VERSION "hnnbnnnynnnnnnnnnnnnnnnnnnnnnnnnnnnnnnnnnn/4/%%%/4/'%**4nnn///"

NS_ :

BS_:

BU_: BAP_Tester Fahrerdisplay_Kombi HUD ICAS1_X_Gateway ICAS3_Gateway ICC_IO_Node Kombi SmartLight_01 ZR_MIB_TOP_ab_Gen3

BO_ 975 TSG_HBFS_01: 8 ICAS1_X_Gateway
	SG_ ASW_Warnung_aktiv_HBFS : 40|1@1+ (1,0) [0|1] ""  Vector__XXX
	SG_ HBFS_FH_Bew_hoch : 32|1@1+ (1,0) [0|1] ""  Vector__XXX
	SG_ HBFS_FH_Bew_tief : 33|1@1+ (1,0) [0|1] ""  Vector__XXX
	SG_ HBFS_FH_Block : 35|1@1+ (1,0) [0|1] ""  Vector__XXX
	SG_ HBFS_FH_Fang : 34|1@1+ (1,0) [0|1] ""  Vector__XXX
	SG_ HBFS_FH_normiert : 39|1@1+ (1,0) [0|1] ""  Vector__XXX
	SG_ HBFS_FH_Oeffnung : 24|8@1+ (0.5,0) [0|100] "PerCent"  Vector__XXX
	SG_ HBFS_FH_S_AutoHoch : 21|1@1+ (1,0) [0|1] ""  Vector__XXX
	SG_ HBFS_FH_S_AutoTief : 23|1@1+ (1,0) [0|1] ""  Vector__XXX
	SG_ HBFS_FH_S_HFS_AutoHoch : 10|1@1+ (1,0) [0|1] ""  Vector__XXX
	SG_ HBFS_FH_S_HFS_AutoTief : 11|1@1+ (1,0) [0|1] ""  Vector__XXX
	SG_ HBFS_FH_S_HFS_ManHoch : 12|1@1+ (1,0) [0|1] ""  Vector__XXX
	SG_ HBFS_FH_S_HFS_ManTief : 13|1@1+ (1,0) [0|1] ""  Vector__XXX
	SG_ HBFS_FH_S_ManHoch : 20|1@1+ (1,0) [0|1] ""  Vector__XXX
	SG_ HBFS_FH_S_ManTief : 22|1@1+ (1,0) [0|1] ""  Vector__XXX
	SG_ HBFS_FH_Thermo : 36|1@1+ (1,0) [0|1] ""  Vector__XXX
	SG_ HBFS_gesafet : 2|1@1+ (1,0) [0|1] ""  Vector__XXX
	SG_ HBFS_Heckrollotaster_betaetigt : 3|1@1+ (1,0) [0|1] ""  Vector__XXX
	SG_ HBFS_Lock_Taster : 6|1@1+ (1,0) [0|1] ""  Vector__XXX
	SG_ HBFS_Lock_Taster_inv : 55|1@1+ (1,0) [0|1] ""  Vector__XXX
	SG_ HBFS_MRollo_Schalter : 52|3@1+ (1,0) [0|7] ""  Vector__XXX
	SG_ HBFS_Oben_Block_erw : 46|1@1+ (1,0) [0|1] ""  Vector__XXX
	SG_ HBFS_SAD_Schalter : 16|4@1+ (1,0) [0|15] ""  Vector__XXX
	SG_ HBFS_Seitenrollo_hoch : 42|1@1+ (1,0) [0|1] ""  Vector__XXX
	SG_ HBFS_Seitenrollo_tief : 43|1@1+ (1,0) [0|1] ""  Vector__XXX
	SG_ HBFS_SK_betaetigt : 63|1@1+ (1,0) [0|1] ""  Vector__XXX
	SG_ HBFS_Sperrklinke : 7|1@1+ (1,0) [0|1] ""  Vector__XXX
	SG_ HBFS_Status_eTAG : 57|2@1+ (1,0) [0|3] ""  Vector__XXX
	SG_ HBFS_Status_KiSi : 44|1@1+ (1,0) [0|1] ""  Vector__XXX
	SG_ HBFS_Status_KiSi_inv : 56|1@1+ (1,0) [0|1] ""  Vector__XXX
	SG_ HBFS_TAG_betaetigt : 8|1@1+ (1,0) [0|1] ""  Vector__XXX
	SG_ HBFS_TIG_betaetigt : 9|1@1+ (1,0) [0|1] ""  Vector__XXX
	SG_ HBFS_TIG_betaetigt_oeffnen : 61|1@1+ (1,0) [0|1] ""  Vector__XXX
	SG_ HBFS_TIG_betaetigt_schliessen : 60|1@1+ (1,0) [0|1] ""  Vector__XXX
	SG_ HBFS_Tuer_geoeffnet : 0|1@1+ (1,0) [0|1] ""  ICAS3_Gateway,ZR_MIB_TOP_ab_Gen3
	SG_ HBFS_Tuer_Status : 14|2@1+ (1,0) [0|3] ""  Vector__XXX
	SG_ HBFS_Tuer_Status_QBit : 59|1@1+ (1,0) [0|1] ""  Vector__XXX
	SG_ HBFS_Tueroeffnen_Warnung : 38|1@1+ (1,0) [0|1] ""  Vector__XXX
	SG_ HBFS_Tuerschloss_defekt : 4|1@1+ (1,0) [0|1] ""  Kombi
	SG_ HBFS_UEKB_aktiviert : 37|1@1+ (1,0) [0|1] ""  Vector__XXX
	SG_ HBFS_Unlock_Taster : 5|1@1+ (1,0) [0|1] ""  Vector__XXX
	SG_ HBFS_Unten_Block_erw : 47|1@1+ (1,0) [0|1] ""  Vector__XXX
	SG_ HBFS_verriegelt : 1|1@1+ (1,0) [0|1] ""  Vector__XXX
	SG_ HBFS_Vorraste_betaetigt : 62|1@1+ (1,0) [0|1] ""  Vector__XXX
	SG_ HBFS_Zuziehhilfe_aktiv : 41|1@1+ (1,0) [0|1] ""  Vector__XXX
	SG_ MTHBFS_M_Taste : 48|1@1+ (1,0) [0|1] ""  Vector__XXX
	SG_ MTHBFS_Pos1 : 49|1@1+ (1,0) [0|1] ""  Vector__XXX
	SG_ MTHBFS_Pos2 : 50|1@1+ (1,0) [0|1] ""  Vector__XXX
	SG_ MTHBFS_Pos3 : 51|1@1+ (1,0) [0|1] ""  Vector__XXX
	SG_ SSR_HBFS_Pos_Unten : 45|1@1+ (1,0) [0|1] ""  Vector__XXX

BO_ 974 TSG_HFS_01: 8 ICAS1_X_Gateway
	SG_ ASW_Warnung_aktiv_HFS : 40|1@1+ (1,0) [0|1] ""  Vector__XXX
	SG_ HFS_FH_Bew_hoch : 32|1@1+ (1,0) [0|1] ""  Vector__XXX
	SG_ HFS_FH_Bew_tief : 33|1@1+ (1,0) [0|1] ""  Vector__XXX
	SG_ HFS_FH_Block : 35|1@1+ (1,0) [0|1] ""  Vector__XXX
	SG_ HFS_FH_Fang : 34|1@1+ (1,0) [0|1] ""  Vector__XXX
	SG_ HFS_FH_normiert : 39|1@1+ (1,0) [0|1] ""  Vector__XXX
	SG_ HFS_FH_Oeffnung : 24|8@1+ (0.5,0) [0|100] "PerCent"  Vector__XXX
	SG_ HFS_FH_S_AutoHoch : 21|1@1+ (1,0) [0|1] ""  Vector__XXX
	SG_ HFS_FH_S_AutoTief : 23|1@1+ (1,0) [0|1] ""  Vector__XXX
	SG_ HFS_FH_S_HBFS_AutoHoch : 10|1@1+ (1,0) [0|1] ""  Vector__XXX
	SG_ HFS_FH_S_HBFS_AutoTief : 11|1@1+ (1,0) [0|1] ""  Vector__XXX
	SG_ HFS_FH_S_HBFS_ManHoch : 12|1@1+ (1,0) [0|1] ""  Vector__XXX
	SG_ HFS_FH_S_HBFS_ManTief : 13|1@1+ (1,0) [0|1] ""  Vector__XXX
	SG_ HFS_FH_S_ManHoch : 20|1@1+ (1,0) [0|1] ""  Vector__XXX
	SG_ HFS_FH_S_ManTief : 22|1@1+ (1,0) [0|1] ""  Vector__XXX
	SG_ HFS_FH_Thermo : 36|1@1+ (1,0) [0|1] ""  Vector__XXX
	SG_ HFS_gesafet : 2|1@1+ (1,0) [0|1] ""  Vector__XXX
	SG_ HFS_Heckrollotaster_betaetigt : 3|1@1+ (1,0) [0|1] ""  Vector__XXX
	SG_ HFS_Lock_Taster : 6|1@1+ (1,0) [0|1] ""  Vector__XXX
	SG_ HFS_Lock_Taster_inv : 55|1@1+ (1,0) [0|1] ""  Vector__XXX
	SG_ HFS_MRollo_Schalter : 52|3@1+ (1,0) [0|7] ""  Vector__XXX
	SG_ HFS_Oben_Block_erw : 46|1@1+ (1,0) [0|1] ""  Vector__XXX
	SG_ HFS_SAD_Schalter : 16|4@1+ (1,0) [0|15] ""  Vector__XXX
	SG_ HFS_Seitenrollo_hoch : 42|1@1+ (1,0) [0|1] ""  Vector__XXX
	SG_ HFS_Seitenrollo_tief : 43|1@1+ (1,0) [0|1] ""  Vector__XXX
	SG_ HFS_SK_betaetigt : 63|1@1+ (1,0) [0|1] ""  Vector__XXX
	SG_ HFS_Sperrklinke : 7|1@1+ (1,0) [0|1] ""  Vector__XXX
	SG_ HFS_Status_eTAG : 56|2@1+ (1,0) [0|3] ""  Vector__XXX
	SG_ HFS_Status_KiSi : 44|1@1+ (1,0) [0|1] ""  Vector__XXX
	SG_ HFS_TAG_betaetigt : 8|1@1+ (1,0) [0|1] ""  Vector__XXX
	SG_ HFS_TCR_Mode_aktiv : 59|1@1+ (1,0) [0|1] ""  Vector__XXX
	SG_ HFS_TIG_betaetigt : 9|1@1+ (1,0) [0|1] ""  Vector__XXX
	SG_ HFS_TIG_betaetigt_oeffnen : 61|1@1+ (1,0) [0|1] ""  Vector__XXX
	SG_ HFS_TIG_betaetigt_schliessen : 60|1@1+ (1,0) [0|1] ""  Vector__XXX
	SG_ HFS_Tuer_geoeffnet : 0|1@1+ (1,0) [0|1] ""  ICAS3_Gateway,ZR_MIB_TOP_ab_Gen3
	SG_ HFS_Tuer_Status : 14|2@1+ (1,0) [0|3] ""  Vector__XXX
	SG_ HFS_Tuer_Status_QBit : 58|1@1+ (1,0) [0|1] ""  Vector__XXX
	SG_ HFS_Tueroeffnen_Warnung : 38|1@1+ (1,0) [0|1] ""  Vector__XXX
	SG_ HFS_Tuerschloss_defekt : 4|1@1+ (1,0) [0|1] ""  Kombi
	SG_ HFS_UEKB_aktiviert : 37|1@1+ (1,0) [0|1] ""  Vector__XXX
	SG_ HFS_Unlock_Taster : 5|1@1+ (1,0) [0|1] ""  Vector__XXX
	SG_ HFS_Unten_Block_erw : 47|1@1+ (1,0) [0|1] ""  Vector__XXX
	SG_ HFS_verriegelt : 1|1@1+ (1,0) [0|1] ""  Vector__XXX
	SG_ HFS_Vorraste_betaetigt : 62|1@1+ (1,0) [0|1] ""  Vector__XXX
	SG_ HFS_Zuziehhilfe_aktiv : 41|1@1+ (1,0) [0|1] ""  Vector__XXX
	SG_ MTHFS_M_Taste : 48|1@1+ (1,0) [0|1] ""  Vector__XXX
	SG_ MTHFS_Pos1 : 49|1@1+ (1,0) [0|1] ""  Vector__XXX
	SG_ MTHFS_Pos2 : 50|1@1+ (1,0) [0|1] ""  Vector__XXX
	SG_ MTHFS_Pos3 : 51|1@1+ (1,0) [0|1] ""  Vector__XXX
	SG_ SSR_HFS_Pos_Unten : 45|1@1+ (1,0) [0|1] ""  Vector__XXX

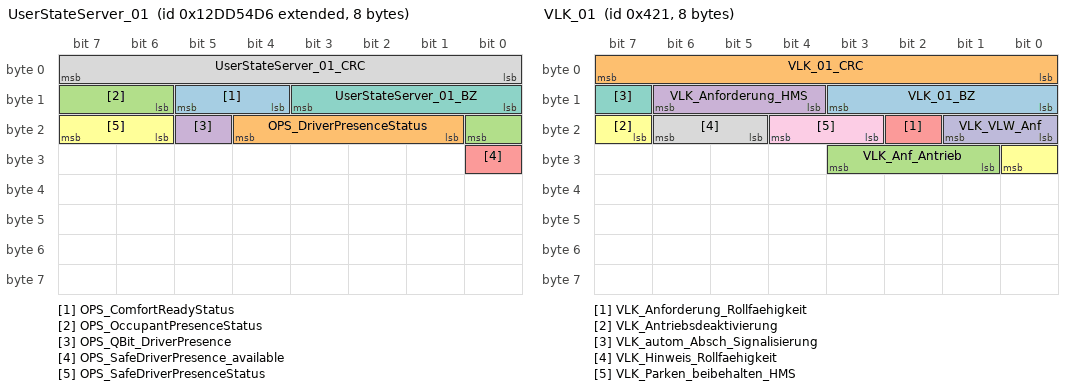
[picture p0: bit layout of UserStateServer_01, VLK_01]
BO_ 2463978710 UserStateServer_01: 8 ICAS1_X_Gateway
	SG_ OPS_ComfortReadyStatus : 12|2@1+ (1,0) [0|3] ""  HUD,ICAS3_Gateway,ICC_IO_Node,ZR_MIB_TOP_ab_Gen3
	SG_ OPS_DriverPresenceStatus : 17|4@1+ (1,0) [0|15] ""  HUD,ICAS3_Gateway,ICC_IO_Node
	SG_ OPS_OccupantPresenceStatus : 14|3@1+ (1,0) [0|7] ""  Vector__XXX
	SG_ OPS_QBit_DriverPresence : 21|1@1+ (1,0) [0|1] ""  Vector__XXX
	SG_ OPS_SafeDriverPresence_available : 24|1@1+ (1,0) [0|1] ""  Vector__XXX
	SG_ OPS_SafeDriverPresenceStatus : 22|2@1+ (1,0) [0|3] ""  Vector__XXX
	SG_ UserStateServer_01_BZ : 8|4@1+ (1,0) [0|15] ""  Vector__XXX
	SG_ UserStateServer_01_CRC : 0|8@1+ (1,0) [0|255] ""  Vector__XXX

BO_ 1716 VIN_01: 8 ICAS1_X_Gateway
	SG_ KS_Geheimnis_1 m0 : 8|8@1+ (1,0) [0|255] ""  ZR_MIB_TOP_ab_Gen3
	SG_ KS_Geheimnis_2 m0 : 16|8@1+ (1,0) [0|255] ""  ZR_MIB_TOP_ab_Gen3
	SG_ KS_Geheimnis_3 m0 : 24|8@1+ (1,0) [0|255] ""  ZR_MIB_TOP_ab_Gen3
	SG_ KS_Geheimnis_4 m0 : 32|8@1+ (1,0) [0|255] ""  ZR_MIB_TOP_ab_Gen3
	SG_ VIN_01_MUX M : 0|2@1+ (1,0) [0|3] ""  ICAS3_Gateway,ICC_IO_Node,Kombi,SmartLight_01,ZR_MIB_TOP_ab_Gen3
	SG_ VIN_1 m0 : 40|8@1+ (1,0) [0|255] ""  ICAS3_Gateway,Kombi,SmartLight_01,ZR_MIB_TOP_ab_Gen3
	SG_ VIN_10 m1 : 56|8@1+ (1,0) [0|255] ""  ICAS3_Gateway,Kombi,SmartLight_01,ZR_MIB_TOP_ab_Gen3
	SG_ VIN_11 m2 : 8|8@1+ (1,0) [0|255] ""  ICAS3_Gateway,Kombi,SmartLight_01,ZR_MIB_TOP_ab_Gen3
	SG_ VIN_12 m2 : 16|8@1+ (1,0) [0|255] ""  ICAS3_Gateway,Kombi,SmartLight_01,ZR_MIB_TOP_ab_Gen3
	SG_ VIN_13 m2 : 24|8@1+ (1,0) [0|255] ""  ICAS3_Gateway,Kombi,SmartLight_01,ZR_MIB_TOP_ab_Gen3
	SG_ VIN_14 m2 : 32|8@1+ (1,0) [0|255] ""  ICAS3_Gateway,Kombi,SmartLight_01,ZR_MIB_TOP_ab_Gen3
	SG_ VIN_15 m2 : 40|8@1+ (1,0) [0|255] ""  ICAS3_Gateway,Kombi,SmartLight_01,ZR_MIB_TOP_ab_Gen3
	SG_ VIN_16 m2 : 48|8@1+ (1,0) [0|255] ""  ICAS3_Gateway,Kombi,SmartLight_01,ZR_MIB_TOP_ab_Gen3
	SG_ VIN_17 m2 : 56|8@1+ (1,0) [0|255] ""  ICAS3_Gateway,Kombi,SmartLight_01,ZR_MIB_TOP_ab_Gen3
	SG_ VIN_2 m0 : 48|8@1+ (1,0) [0|255] ""  ICAS3_Gateway,Kombi,SmartLight_01,ZR_MIB_TOP_ab_Gen3
	SG_ VIN_3 m0 : 56|8@1+ (1,0) [0|255] ""  ICAS3_Gateway,Kombi,SmartLight_01,ZR_MIB_TOP_ab_Gen3
	SG_ VIN_4 m1 : 8|8@1+ (1,0) [0|255] ""  ICAS3_Gateway,Kombi,SmartLight_01,ZR_MIB_TOP_ab_Gen3
	SG_ VIN_5 m1 : 16|8@1+ (1,0) [0|255] ""  ICAS3_Gateway,Kombi,SmartLight_01,ZR_MIB_TOP_ab_Gen3
	SG_ VIN_6 m1 : 24|8@1+ (1,0) [0|255] ""  ICAS3_Gateway,Kombi,SmartLight_01,ZR_MIB_TOP_ab_Gen3
	SG_ VIN_7 m1 : 32|8@1+ (1,0) [0|255] ""  ICAS3_Gateway,Kombi,SmartLight_01,ZR_MIB_TOP_ab_Gen3
	SG_ VIN_8 m1 : 40|8@1+ (1,0) [0|255] ""  ICAS3_Gateway,Kombi,SmartLight_01,ZR_MIB_TOP_ab_Gen3
	SG_ VIN_9 m1 : 48|8@1+ (1,0) [0|255] ""  ICAS3_Gateway,Kombi,SmartLight_01,ZR_MIB_TOP_ab_Gen3

BO_ 1057 VLK_01: 8 ICAS1_X_Gateway
	SG_ VLK_01_BZ : 8|4@1+ (1,0) [0|15] ""  Vector__XXX
	SG_ VLK_01_CRC : 0|8@1+ (1,0) [0|255] ""  Vector__XXX
	SG_ VLK_Anf_Antrieb : 25|3@1+ (1,0) [0|7] ""  Vector__XXX
	SG_ VLK_Anforderung_HMS : 12|3@1+ (1,0) [0|7] ""  Vector__XXX
	SG_ VLK_Anforderung_Rollfaehigkeit : 18|1@1+ (1,0) [0|1] ""  Vector__XXX
	SG_ VLK_Antriebsdeaktivierung : 23|2@1+ (1,0) [0|3] ""  Vector__XXX
	SG_ VLK_autom_Absch_Signalisierung : 15|1@1+ (1,0) [0|1] ""  Kombi
	SG_ VLK_Hinweis_Rollfaehigkeit : 21|2@1+ (1,0) [0|3] ""  Kombi
	SG_ VLK_Parken_beibehalten_HMS : 19|2@1+ (1,0) [0|3] ""  Vector__XXX
	SG_ VLK_VLW_Anf : 16|2@1+ (1,0) [0|3] ""  Kombi

BO_ 2463978663 VZE_04: 32 ICAS1_X_Gateway
	SG_ VZE_Akustik_Limitwechsel : 5|1@1+ (1,0) [0|1] ""  Kombi
	SG_ VZE_Akustik_Limitwechsel_Status : 69|1@1+ (1,0) [0|1] ""  Vector__XXX
	SG_ VZE_Anhaenger_Vmax : 91|4@1+ (10,10) [10|140] "KiloMeterPerHour"  Vector__XXX
	SG_ VZE_Anzeige_VZ_1 : 232|8@1+ (1,0) [1|255] ""  Vector__XXX
	SG_ VZE_Anzeige_VZ_2 : 240|8@1+ (1,0) [1|255] "None"  Vector__XXX
	SG_ VZE_Anzeige_VZ_3 : 248|8@1+ (1,0) [1|255] "None"  Vector__XXX
	SG_ VZE_Anzeige_ZS_1 : 208|4@1+ (1,0) [1|15] "None"  Vector__XXX
	SG_ VZE_Anzeige_ZS_2 : 212|4@1+ (1,0) [1|15] "None"  Vector__XXX
	SG_ VZE_Anzeige_ZS_3 : 216|4@1+ (1,0) [1|15] "None"  Vector__XXX
	SG_ VZE_Anzeigemodus : 0|2@1+ (1,0) [0|3] ""  Vector__XXX
	SG_ VZE_Anzeigeunterdrueck_Zeichen_1 : 50|1@1+ (1,0) [0|1] ""  Vector__XXX
	SG_ VZE_Anzeigeunterdrueck_Zeichen_2 : 10|1@1+ (1,0) [0|1] ""  Vector__XXX
	SG_ VZE_Anzeigeunterdrueck_Zeichen_3 : 9|1@1+ (1,0) [0|1] ""  Vector__XXX
	SG_ VZE_Anzeigeunterdrueck_Zeichen_4 : 127|1@1+ (1,0) [0|1] ""  Vector__XXX
	SG_ VZE_Anzeigeunterdrueck_Zeichen_5 : 72|1@1+ (1,0) [0|1] ""  Vector__XXX
	SG_ VZE_Baustelle : 110|2@1+ (1,0) [0|3] ""  Vector__XXX
	SG_ VZE_Erweiterte_Information : 157|8@1+ (1,0) [1|255] "None"  Vector__XXX
	SG_ VZE_FoD_Status : 206|2@1+ (1,0) [0|3] ""  Fahrerdisplay_Kombi,Kombi,ZR_MIB_TOP_ab_Gen3
	SG_ VZE_Gong : 63|1@1+ (1,0) [0|1] ""  Vector__XXX
	SG_ VZE_Hinweistext : 2|3@1+ (1,0) [1|7] ""  Fahrerdisplay_Kombi
	SG_ VZE_Hinweistext_03 : 220|4@1+ (1,0) [1|15] ""  Vector__XXX
	SG_ VZE_Land : 224|5@1+ (1,0) [1|31] ""  Vector__XXX
	SG_ VZE_Modus_OptischeWarnung : 6|1@1+ (1,0) [0|1] ""  Fahrerdisplay_Kombi
	SG_ VZE_SLWF_Status : 70|2@1+ (1,0) [0|3] ""  Fahrerdisplay_Kombi
	SG_ VZE_Tempowarnung_Einheit : 166|1@1+ (1,0) [0|1] ""  Vector__XXX
	SG_ VZE_Tempowarnung_Offset : 167|5@1+ (1,0) [1|31] ""  Vector__XXX
	SG_ VZE_Tempowarnung_Status : 165|1@1+ (1,0) [0|1] ""  Vector__XXX
	SG_ VZE_Umweltinfo_Anhaengerbetrieb : 156|1@1+ (1,0) [0|1] ""  Vector__XXX
	SG_ VZE_Umweltinfo_Naesse : 154|1@1+ (1,0) [0|1] ""  Vector__XXX
	SG_ VZE_Umweltinfo_Nebel : 155|1@1+ (1,0) [0|1] ""  Vector__XXX
	SG_ VZE_Verkehrszeichen_1 : 11|8@1+ (1,0) [1|255] ""  Vector__XXX
	SG_ VZE_Verkehrszeichen_2 : 19|8@1+ (1,0) [1|255] ""  Vector__XXX
	SG_ VZE_Verkehrszeichen_3 : 27|8@1+ (1,0) [1|255] ""  Vector__XXX
	SG_ VZE_Verkehrszeichen_4 : 75|8@1+ (1,0) [1|255] ""  Vector__XXX
	SG_ VZE_Verkehrszeichen_5 : 83|8@1+ (1,0) [1|255] ""  Kombi
	SG_ VZE_Verkehrszeichen_6 : 128|8@1+ (1,0) [1|255] "None"  Vector__XXX
	SG_ VZE_Verkehrszeichen_Einheit : 8|1@1+ (1,0) [0|1] ""  Vector__XXX
	SG_ VZE_Warnung_Verkehrszeichen_1 : 35|1@1+ (1,0) [0|1] ""  Vector__XXX
	SG_ VZE_Warnung_Verkehrszeichen_2 : 36|1@1+ (1,0) [0|1] ""  Vector__XXX
	SG_ VZE_Warnung_Verkehrszeichen_3 : 37|1@1+ (1,0) [0|1] ""  Vector__XXX
	SG_ VZE_Warnung_Verkehrszeichen_4 : 99|1@1+ (1,0) [0|1] ""  Vector__XXX
	SG_ VZE_Warnung_Verkehrszeichen_5 : 100|1@1+ (1,0) [0|1] ""  Kombi
	SG_ VZE_Warnung_VZ_1 : 229|1@1+ (1,0) [0|1] ""  Vector__XXX
	SG_ VZE_Warnung_VZ_2 : 230|1@1+ (1,0) [0|1] ""  Vector__XXX
	SG_ VZE_Warnung_VZ_3 : 231|1@1+ (1,0) [0|1] ""  Vector__XXX
	SG_ VZE_Zeichen_01_Gesetz : 56|1@1+ (1,0) [0|1] ""  Vector__XXX
	SG_ VZE_Zeichen_01_Kamera : 54|1@1+ (1,0) [0|1] ""  Vector__XXX
	SG_ VZE_Zeichen_01_KameraWied : 51|1@1+ (1,0) [0|1] ""  Vector__XXX
	SG_ VZE_Zeichen_01_Karte : 55|1@1+ (1,0) [0|1] ""  Vector__XXX
	SG_ VZE_Zeichen_02_Gesetz : 59|1@1+ (1,0) [0|1] ""  Vector__XXX
	SG_ VZE_Zeichen_02_Kamera : 57|1@1+ (1,0) [0|1] ""  Vector__XXX
	SG_ VZE_Zeichen_02_KameraWied : 52|1@1+ (1,0) [0|1] ""  Vector__XXX
	SG_ VZE_Zeichen_02_Karte : 58|1@1+ (1,0) [0|1] ""  Vector__XXX
	SG_ VZE_Zeichen_03_Gesetz : 62|1@1+ (1,0) [0|1] ""  Vector__XXX
	SG_ VZE_Zeichen_03_Kamera : 60|1@1+ (1,0) [0|1] ""  Vector__XXX
	SG_ VZE_Zeichen_03_KameraWied : 53|1@1+ (1,0) [0|1] ""  Vector__XXX
	SG_ VZE_Zeichen_03_Karte : 61|1@1+ (1,0) [0|1] ""  Vector__XXX
	SG_ VZE_Zeichen_04_Gesetz : 95|1@1+ (1,0) [0|1] ""  Vector__XXX
	SG_ VZE_Zeichen_04_Kamera : 96|1@1+ (1,0) [0|1] ""  Vector__XXX
	SG_ VZE_Zeichen_04_KameraWied : 97|1@1+ (1,0) [0|1] ""  Vector__XXX
	SG_ VZE_Zeichen_04_Karte : 98|1@1+ (1,0) [0|1] ""  Vector__XXX
	SG_ VZE_Zeichen_05_Entfernung : 113|7@1+ (1,0) [1|127] "Meter"  Vector__XXX
	SG_ VZE_Zeichen_05_Entfernung_StdA : 120|7@1+ (1,0) [1|127] "Meter"  Vector__XXX
	SG_ VZE_Zeichen_05_Gesetz : 101|1@1+ (1,0) [0|1] ""  Vector__XXX
	SG_ VZE_Zeichen_05_Kamera : 74|1@1+ (1,0) [0|1] ""  Vector__XXX
	SG_ VZE_Zeichen_05_KameraWied : 73|1@1+ (1,0) [0|1] ""  Vector__XXX
	SG_ VZE_Zeichen_05_Karte : 112|1@1+ (1,0) [0|1] ""  Vector__XXX
	SG_ VZE_Zeichen_06_Entfernung : 140|7@1+ (1,0) [1|127] "Meter"  Vector__XXX
	SG_ VZE_Zeichen_06_Entfernung_StdA : 147|7@1+ (1,0) [1|127] "Meter"  Vector__XXX
	SG_ VZE_Zusatzschild_1 : 38|4@1+ (1,0) [1|15] ""  Vector__XXX
	SG_ VZE_Zusatzschild_2 : 42|4@1+ (1,0) [1|15] ""  Vector__XXX
	SG_ VZE_Zusatzschild_3 : 46|4@1+ (1,0) [1|15] ""  Vector__XXX
	SG_ VZE_Zusatzschild_4 : 102|4@1+ (1,0) [1|15] ""  Vector__XXX
	SG_ VZE_Zusatzschild_5 : 106|4@1+ (1,0) [1|15] ""  Vector__XXX
	SG_ VZE_Zusatzschild_6 : 136|4@1+ (1,0) [1|15] ""  Vector__XXX

BO_ 916 WBA_03: 8 ICAS1_X_Gateway
	SG_ GE_Sollgang : 40|4@1+ (1,0) [0|15] ""  Vector__XXX
	SG_ GE_Stoppverbot_Anz_01 : 56|1@1+ (1,0) [0|1] ""  Vector__XXX
	SG_ GE_Stoppverbot_Anz_02 : 57|1@1+ (1,0) [0|1] ""  Vector__XXX
	SG_ GE_Stoppverbot_Anz_03 : 58|1@1+ (1,0) [0|1] ""  Vector__XXX
	SG_ GE_Stoppverbot_Anz_04 : 59|1@1+ (1,0) [0|1] ""  Vector__XXX
	SG_ GE_Stoppverbot_Anz_05 : 60|1@1+ (1,0) [0|1] ""  Vector__XXX
	SG_ GE_Stoppverbot_Anz_06 : 61|1@1+ (1,0) [0|1] ""  Vector__XXX
	SG_ GE_Stoppverbot_Anz_07 : 62|1@1+ (1,0) [0|1] ""  Vector__XXX
	SG_ GE_Stoppverbot_Anz_Std : 63|1@1+ (1,0) [0|1] ""  Vector__XXX
	SG_ GE_Tipschaltempf_verfuegbar : 44|1@1+ (1,0) [0|1] ""  Vector__XXX
	SG_ GE_Wiederstart_Anz_Std : 55|1@1+ (1,0) [0|1] ""  Vector__XXX
	SG_ WBA_03_BZ : 8|4@1+ (1,0) [0|15] ""  Fahrerdisplay_Kombi,Kombi
	SG_ WBA_03_CRC : 0|8@1+ (1,0) [0|255] ""  Fahrerdisplay_Kombi,Kombi
	SG_ WBA_Anforderung_Akustik : 53|1@1+ (1,0) [0|1] ""  ICAS3_Gateway,Kombi
	SG_ WBA_Blinken : 54|1@1+ (1,0) [0|1] ""  Vector__XXX
	SG_ WBA_eing_Gang_02 : 24|4@1+ (1,0) [0|15] ""  Vector__XXX
	SG_ WBA_Fahrstufe_02 : 12|4@1+ (1,0) [0|15] ""  Fahrerdisplay_Kombi,Kombi,ZR_MIB_TOP_ab_Gen3
	SG_ WBA_GE_Texte : 28|3@1+ (1,0) [0|7] ""  Kombi
	SG_ WBA_GE_Texte_02 : 45|3@1+ (1,0) [0|7] ""  Kombi
	SG_ WBA_GE_Warnung_02 : 20|4@1+ (1,0) [0|15] ""  Kombi
	SG_ WBA_GE_Zusatzwarnungen : 37|3@1+ (1,0) [0|7] ""  Vector__XXX
	SG_ WBA_Schaltschema_02 : 32|3@1+ (1,0) [0|7] ""  Vector__XXX
	SG_ WBA_Schaltschema_Fahreraktion : 49|1@1+ (1,0) [0|1] ""  Vector__XXX
	SG_ WBA_Schaltschema_FS_inaktiv : 35|2@1+ (1,0) [0|3] ""  Vector__XXX
	SG_ WBA_Schaltschema_FS_vorwaerts : 50|2@1+ (1,0) [0|3] ""  Vector__XXX
	SG_ WBA_Schaltschema_Tippgasse : 48|1@1+ (1,0) [0|1] ""  Vector__XXX
	SG_ WBA_Segeln_aktiv : 31|1@1+ (1,0) [0|1] ""  Vector__XXX
	SG_ WBA_Shiftlock_Lampe : 52|1@1+ (1,0) [0|1] ""  Vector__XXX
	SG_ WBA_ZielFahrstufe : 16|4@1+ (1,0) [0|15] ""  Vector__XXX

BO_ 1361 WFS_01: 8 ICAS1_X_Gateway
	SG_ WFS_Betrieb_Lesespule : 21|1@1+ (1,0) [0|1] ""  Vector__XXX
	SG_ WFS_ELV_authorisiert : 19|1@1+ (1,0) [0|1] ""  Vector__XXX
	SG_ WFS_Fahrerhinweise : 34|2@1+ (1,0) [0|3] ""  Kombi
	SG_ WFS_ID_Geb_autorisiert : 5|1@1+ (1,0) [0|1] ""  Vector__XXX
	SG_ WFS_ID_Geb_autorisiert_in_Kl15 : 6|1@1+ (1,0) [0|1] ""  Vector__XXX
	SG_ WFS_ID_Geb_steckt : 7|1@1+ (1,0) [0|1] ""  Vector__XXX
	SG_ WFS_Klemmenfreigabe : 22|1@1+ (1,0) [0|1] ""  Vector__XXX
	SG_ WFS_Klemmenfreigabe_Signatur : 23|11@1+ (1,0) [0|2047] ""  Vector__XXX
	SG_ WFS_LF_Aktiv : 20|1@1+ (1,0) [0|1] ""  Vector__XXX
	SG_ WFS_LZ : 17|2@1+ (1,0) [0|3] ""  Kombi
	SG_ WFS_LZ_02 : 38|4@1+ (1,0) [0|15] ""  Vector__XXX
	SG_ WFS_Parken_Status : 36|2@1+ (1,0) [0|3] ""  Vector__XXX
	SG_ WFS_Safe : 16|1@1+ (1,0) [0|1] ""  Kombi
	SG_ WFS_Schluessel_Fahrberecht : 0|4@1+ (1,0) [0|15] ""  ZR_MIB_TOP_ab_Gen3
	SG_ WFS_Schluessel_Ist : 12|4@1+ (1,0) [0|8] "None"  Kombi,ZR_MIB_TOP_ab_Gen3
	SG_ WFS_Schluessel_Soll : 8|4@1+ (1,0) [0|8] "None"  Kombi,ZR_MIB_TOP_ab_Gen3
	SG_ WFS_Verbauinfo_ELV : 4|1@1+ (1,0) [0|1] ""  Vector__XXX

BO_ 1369 WFS_01_SOK_Signatur: 8 ICAS1_X_Gateway
	SG_ SOK_WFS01_Signatur : 0|64@1+ (1,0) [1|18446744073709551616] "None"  Vector__XXX

BO_ 34 WFS_Transponder_Req_02: 8 ICAS1_X_Gateway
	SG_ WFS_Transponder_Req_02_Data : 0|64@1+ (1,0) [0|18446744073709551616] "None"  Fahrerdisplay_Kombi

BO_ 35 WFS_Transponder_Resp_02: 8 Fahrerdisplay_Kombi
	SG_ WFS_Transponder_Resp_02_Data : 0|64@1+ (1,0) [0|18446744073709551616] "None"  ICAS1_X_Gateway

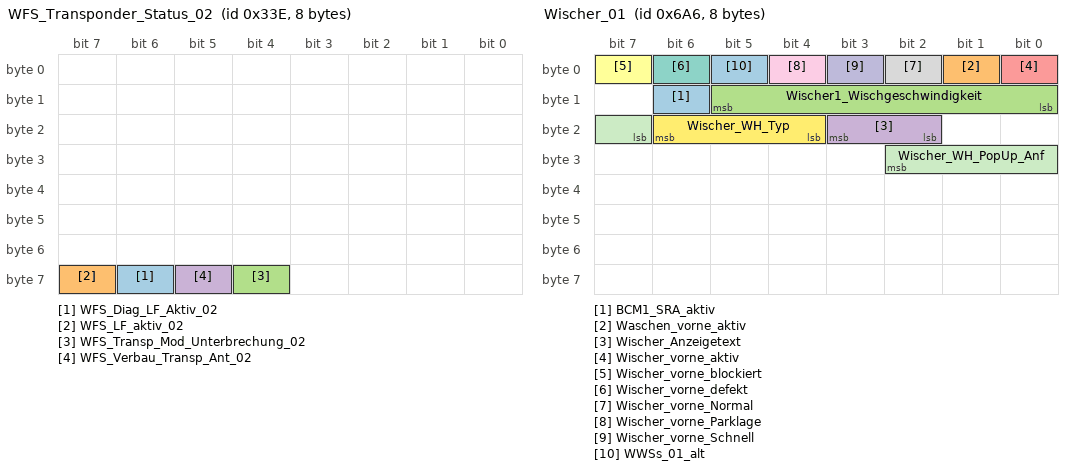
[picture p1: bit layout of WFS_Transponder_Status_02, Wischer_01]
BO_ 830 WFS_Transponder_Status_02: 8 Fahrerdisplay_Kombi
	SG_ WFS_Diag_LF_Aktiv_02 : 62|1@1+ (1,0) [0|1] ""  ICAS1_X_Gateway
	SG_ WFS_LF_aktiv_02 : 63|1@1+ (1,0) [0|1] ""  ICAS1_X_Gateway
	SG_ WFS_Transp_Mod_Unterbrechung_02 : 60|1@1+ (1,0) [0|1] ""  ICAS1_X_Gateway
	SG_ WFS_Verbau_Transp_Ant_02 : 61|1@1+ (1,0) [0|1] ""  ICAS1_X_Gateway

BO_ 1702 Wischer_01: 8 ICAS1_X_Gateway
	SG_ BCM1_SRA_aktiv : 14|1@1+ (1,0) [0|1] ""  Vector__XXX
	SG_ Waschen_vorne_aktiv : 1|1@1+ (1,0) [0|1] ""  Vector__XXX
	SG_ Wischer1_Wischgeschwindigkeit : 8|6@1+ (1,9) [10|70] "MinutInver"  Vector__XXX
	SG_ Wischer_Anzeigetext : 18|2@1+ (1,0) [0|3] ""  Vector__XXX
	SG_ Wischer_vorne_aktiv : 0|1@1+ (1,0) [0|1] ""  Vector__XXX
	SG_ Wischer_vorne_blockiert : 7|1@1+ (1,0) [0|1] ""  Vector__XXX
	SG_ Wischer_vorne_defekt : 6|1@1+ (1,0) [0|1] ""  Fahrerdisplay_Kombi,Kombi
	SG_ Wischer_vorne_Normal : 2|1@1+ (1,0) [0|1] ""  Vector__XXX
	SG_ Wischer_vorne_Parklage : 4|1@1+ (1,0) [0|1] ""  Vector__XXX
	SG_ Wischer_vorne_Schnell : 3|1@1+ (1,0) [0|1] ""  Vector__XXX
	SG_ Wischer_WH_PopUp_Anf : 23|4@1+ (1,0) [0|15] ""  Vector__XXX
	SG_ Wischer_WH_Typ : 20|3@1+ (1,0) [0|7] ""  Kombi
	SG_ WWSs_01_alt : 5|1@1+ (1,0) [0|1] ""  Vector__XXX

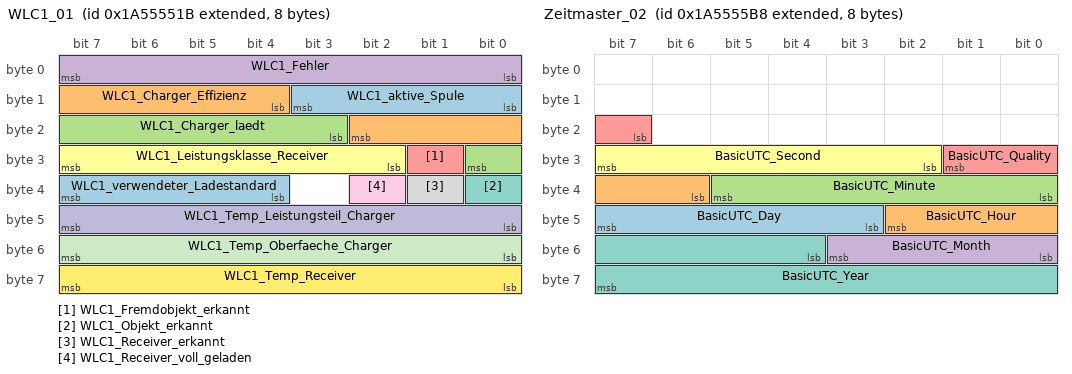
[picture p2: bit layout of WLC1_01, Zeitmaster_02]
BO_ 2589283611 WLC1_01: 8 ICAS3_Gateway
	SG_ WLC1_aktive_Spule : 8|4@1+ (1,0) [0|10] ""  ICAS1_X_Gateway
	SG_ WLC1_Charger_Effizienz : 12|7@1+ (1,0) [0|100] "PerCent"  ICAS1_X_Gateway
	SG_ WLC1_Charger_laedt : 19|6@1+ (0.1,0) [0|5] "Watt"  ICAS1_X_Gateway,ICAS3_Gateway,ZR_MIB_TOP_ab_Gen3
	SG_ WLC1_Fehler : 0|8@1+ (1,0) [0|255] ""  ICAS1_X_Gateway
	SG_ WLC1_Fremdobjekt_erkannt : 25|1@1+ (1,0) [0|1] ""  ICAS1_X_Gateway,ICAS3_Gateway,ZR_MIB_TOP_ab_Gen3
	SG_ WLC1_Leistungsklasse_Receiver : 26|6@1+ (0.1,0) [0|5] "Watt"  ICAS1_X_Gateway
	SG_ WLC1_Objekt_erkannt : 32|1@1+ (1,0) [0|1] ""  ICAS1_X_Gateway
	SG_ WLC1_Receiver_erkannt : 33|1@1+ (1,0) [0|1] ""  ICAS1_X_Gateway
	SG_ WLC1_Receiver_voll_geladen : 34|1@1+ (1,0) [0|1] ""  ICAS1_X_Gateway
	SG_ WLC1_Temp_Leistungsteil_Charger : 40|8@1+ (1,-58) [-58|120] "DegreCelsi"  ICAS1_X_Gateway
	SG_ WLC1_Temp_Oberfaeche_Charger : 48|8@1+ (1,-58) [-58|120] "DegreCelsi"  ICAS1_X_Gateway
	SG_ WLC1_Temp_Receiver : 56|8@1+ (1,-58) [-58|120] "DegreCelsi"  ICAS1_X_Gateway
	SG_ WLC1_verwendeter_Ladestandard : 36|4@1+ (1,0) [0|15] ""  ICAS1_X_Gateway

BO_ 2591965952 XCP_SmaLi_CRO_01: 64 Vector__XXX
	SG_ XCP_SmaLi_CRO_01_Data : 0|512@1+ (1,0) [0|13407807929942597099574024998205846127479365820592393377723561443721764030073546976801874298166903427690031858186486050853753882811946569946433649006084096] ""  SmartLight_01

BO_ 2591965953 XCP_SmaLi_DTO_01: 64 SmartLight_01
	SG_ XCP_SmaLi_DTO_01_Data : 0|512@1+ (1,0) [0|13407807929942597099574024998205846127479365820592393377723561443721764030073546976801874298166903427690031858186486050853753882811946569946433649006084096] ""  Vector__XXX

BO_ 2589283768 Zeitmaster_02: 8 ICAS1_X_Gateway
	SG_ BasicUTC_Day : 43|5@1+ (1,0) [1|31] "Day"  Kombi
	SG_ BasicUTC_Hour : 38|5@1+ (1,0) [0|23] "Hours"  Kombi
	SG_ BasicUTC_Minute : 32|6@1+ (1,0) [0|59] "Minut"  Kombi
	SG_ BasicUTC_Month : 48|4@1+ (1,0) [1|12] "Month"  Kombi
	SG_ BasicUTC_Quality : 23|3@1+ (1,0) [0|7] ""  Kombi
	SG_ BasicUTC_Second : 26|6@1+ (1,0) [0|60] "Secon"  Kombi
	SG_ BasicUTC_Year : 52|12@1+ (1,0) [1|4094] "Year"  Kombi

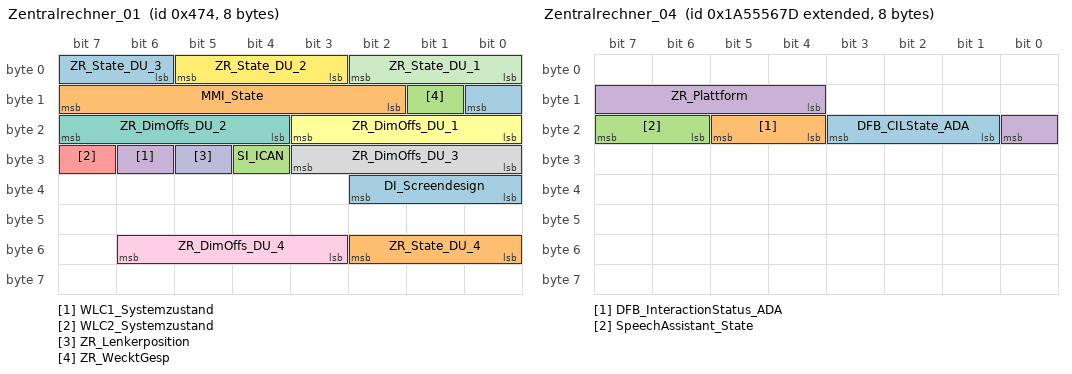
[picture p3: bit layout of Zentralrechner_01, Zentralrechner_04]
BO_ 1140 Zentralrechner_01: 8 ICAS3_Gateway
	SG_ DI_Screendesign : 32|3@1+ (1,0) [0|7] ""  Fahrerdisplay_Kombi,ICAS1_X_Gateway
	SG_ MMI_State : 10|6@1+ (1,0) [0|63] ""  ICAS1_X_Gateway
	SG_ SI_ICAN : 28|1@1+ (1,0) [0|1] ""  ICAS1_X_Gateway
	SG_ WLC1_Systemzustand : 30|1@1+ (1,0) [0|1] ""  ICAS1_X_Gateway
	SG_ WLC2_Systemzustand : 31|1@1+ (1,0) [0|1] ""  ICAS1_X_Gateway
	SG_ ZR_DimOffs_DU_1 : 16|4@1+ (1,-5) [-5|5] "None"  ICAS1_X_Gateway
	SG_ ZR_DimOffs_DU_2 : 20|4@1+ (1,-5) [-5|5] "None"  ICAS1_X_Gateway
	SG_ ZR_DimOffs_DU_3 : 24|4@1+ (1,-5) [-5|5] "None"  ICAS1_X_Gateway
	SG_ ZR_DimOffs_DU_4 : 51|4@1+ (1,-5) [-5|5] "None"  ICAS1_X_Gateway
	SG_ ZR_Lenkerposition : 29|1@1+ (1,0) [0|1] ""  ICAS1_X_Gateway
	SG_ ZR_State_DU_1 : 0|3@1+ (1,0) [0|7] ""  ICAS1_X_Gateway
	SG_ ZR_State_DU_2 : 3|3@1+ (1,0) [0|7] ""  ICAS1_X_Gateway
	SG_ ZR_State_DU_3 : 6|3@1+ (1,0) [0|7] ""  ICAS1_X_Gateway
	SG_ ZR_State_DU_4 : 48|3@1+ (1,0) [0|7] ""  ICAS1_X_Gateway
	SG_ ZR_WecktGesp : 9|1@1+ (1,0) [0|1] ""  ICAS1_X_Gateway

BO_ 2589283965 Zentralrechner_04: 8 ICAS3_Gateway
	SG_ DFB_CILState_ADA : 17|3@1+ (1,0) [0|7] ""  ICAS1_X_Gateway
	SG_ DFB_InteractionStatus_ADA : 20|2@1+ (1,0) [0|3] ""  ICAS1_X_Gateway
	SG_ SpeechAssistant_State : 22|2@1+ (1,0) [0|3] ""  ICAS1_X_Gateway
	SG_ ZR_Plattform : 12|5@1+ (1,0) [0|31] ""  Vector__XXX

BO_ 1411 ZV_02: 8 ICAS1_X_Gateway
	SG_ BCM_FH_Freigabe : 12|1@1+ (1,0) [0|1] ""  SmartLight_01
	SG_ BCM_HSK_Freigabe : 14|1@1+ (1,0) [0|1] ""  Vector__XXX
	SG_ BCM_Komfortfkt_Freigabe : 13|1@1+ (1,0) [0|1] ""  SmartLight_01
	SG_ BCM_Verdeck_Freigabe : 15|1@1+ (1,0) [0|1] ""  Vector__XXX
	SG_ DWA_aktiv : 31|1@1+ (1,0) [0|1] ""  SmartLight_01
	SG_ FBS_IDG_in_Reichweite : 41|1@1+ (1,0) [0|1] ""  SmartLight_01
	SG_ FBS_Warn_Schluessel_Batt : 47|1@1+ (1,0) [0|1] ""  Kombi,SmartLight_01
	SG_ FFB_Auf_Taste : 36|1@1+ (1,0) [0|1] ""  SmartLight_01
	SG_ FFB_CarFinder : 38|1@1+ (1,0) [0|1] ""  Vector__XXX
	SG_ FFB_HDF_Taste : 34|1@1+ (1,0) [0|1] ""  SmartLight_01
	SG_ FFB_Komfortoeffnen : 39|1@1+ (1,0) [0|1] ""  SmartLight_01
	SG_ FFB_Komfortschliessen : 40|1@1+ (1,0) [0|1] ""  SmartLight_01
	SG_ FFB_Panik_Taste : 35|1@1+ (1,0) [0|1] ""  SmartLight_01
	SG_ FFB_Zu_Taste : 37|1@1+ (1,0) [0|1] ""  SmartLight_01
	SG_ IRUE_aktiv : 30|1@1+ (1,0) [0|1] ""  SmartLight_01
	SG_ IRUE_Taster_Fkts_LED : 55|1@1+ (1,0) [0|1] ""  Vector__XXX
	SG_ VIP_Sensor_STSG_HBFS_betaetigt : 11|1@1+ (1,0) [0|1] ""  Vector__XXX
	SG_ VIP_Sensor_STSG_HFS_betaetigt : 10|1@1+ (1,0) [0|1] ""  Vector__XXX
	SG_ ZV_Anf_Challenge_Auth : 3|1@1+ (1,0) [0|1] ""  Vector__XXX
	SG_ ZV_BT_offen : 25|1@1+ (1,0) [0|1] ""  ICAS3_Gateway,Kombi,SmartLight_01,ZR_MIB_TOP_ab_Gen3
	SG_ ZV_Einzeltuerentriegelung : 22|1@1+ (1,0) [0|1] ""  SmartLight_01
	SG_ ZV_eRWK_Umfeld_Pruefung : 6|1@1+ (1,0) [0|1] ""  Vector__XXX
	SG_ ZV_FT_offen : 24|1@1+ (1,0) [0|1] ""  ICAS3_Gateway,ICC_IO_Node,Kombi,SmartLight_01,ZR_MIB_TOP_ab_Gen3
	SG_ ZV_gesafet_extern_ist : 20|1@1+ (1,0) [0|1] ""  SmartLight_01
	SG_ ZV_gesafet_extern_soll : 21|1@1+ (1,0) [0|1] ""  SmartLight_01
	SG_ ZV_HBFS_offen : 27|1@1+ (1,0) [0|1] ""  ICAS3_Gateway,Kombi,SmartLight_01,ZR_MIB_TOP_ab_Gen3
	SG_ ZV_HD_offen : 28|1@1+ (1,0) [0|1] ""  ICAS3_Gateway,Kombi,SmartLight_01,ZR_MIB_TOP_ab_Gen3
	SG_ ZV_Heckeinzelentriegelung : 23|1@1+ (1,0) [0|1] ""  SmartLight_01
	SG_ ZV_HFS_offen : 26|1@1+ (1,0) [0|1] ""  ICAS3_Gateway,Kombi,SmartLight_01,ZR_MIB_TOP_ab_Gen3
	SG_ ZV_HS_offen : 29|1@1+ (1,0) [0|1] ""  Vector__XXX
	SG_ ZV_ist_Zustand_verfuegbar : 54|1@1+ (1,0) [0|1] ""  SmartLight_01
	SG_ ZV_Oeffnungsmodus : 48|2@1+ (1,0) [0|3] ""  SmartLight_01
	SG_ ZV_Rollo_auf : 57|1@1+ (1,0) [0|1] ""  SmartLight_01
	SG_ ZV_Rollo_zu : 58|1@1+ (1,0) [0|1] ""  SmartLight_01
	SG_ ZV_SAD_auf : 59|1@1+ (1,0) [0|1] ""  SmartLight_01
	SG_ ZV_SAD_zu : 60|1@1+ (1,0) [0|1] ""  SmartLight_01
	SG_ ZV_SafeFunktion_aktiv : 46|1@1+ (1,0) [0|1] ""  Kombi,SmartLight_01
	SG_ ZV_Schluessel_Zugang : 42|4@1+ (1,0) [0|15] ""  SmartLight_01
	SG_ ZV_STSG_HBFS_Anf : 2|1@1+ (1,0) [0|1] ""  Vector__XXX
	SG_ ZV_STSG_HFS_Anf : 1|1@1+ (1,0) [0|1] ""  Vector__XXX
	SG_ ZV_Tankklappe_offen : 56|1@1+ (1,0) [0|1] ""  Vector__XXX
	SG_ ZV_verriegeln_Anf : 0|1@1+ (1,0) [0|1] ""  Vector__XXX
	SG_ ZV_verriegelt_extern_ist : 17|1@1+ (1,0) [0|1] ""  Kombi,SmartLight_01
	SG_ ZV_verriegelt_extern_soll : 19|1@1+ (1,0) [0|1] ""  ICAS3_Gateway,ICC_IO_Node,Kombi,SmartLight_01,ZR_MIB_TOP_ab_Gen3
	SG_ ZV_verriegelt_intern_ist : 16|1@1+ (1,0) [0|1] ""  SmartLight_01
	SG_ ZV_verriegelt_intern_soll : 18|1@1+ (1,0) [0|1] ""  SmartLight_01
	SG_ ZV_verriegelt_soll : 62|2@1+ (1,0) [0|3] ""  Vector__XXX

BO_ 708 ZV_04: 8 ICAS1_X_Gateway
	SG_ BCM_Waehlhebel_P_Hinweis : 52|1@1+ (1,0) [0|1] ""  Kombi
	SG_ UHF_FFB_Funkschluesseltyp : 58|3@1+ (1,0) [0|7] ""  Vector__XXX
	SG_ UHF_FFB_SKC_anlernen : 61|1@1+ (1,0) [0|1] ""  Vector__XXX
	SG_ ZV_04_BZ : 8|4@1+ (1,0) [0|15] ""  Vector__XXX
	SG_ ZV_04_CRC : 0|8@1+ (1,0) [0|255] ""  Vector__XXX
	SG_ ZV_DWA_Einfachhorn_Anf : 57|1@1+ (1,0) [0|1] ""  Vector__XXX
	SG_ ZV_DWA_Einfachhorn_Takt : 56|1@1+ (1,0) [0|1] ""  Vector__XXX
	SG_ ZV_Einfachhorn_Anf : 55|1@1+ (1,0) [0|1] ""  Vector__XXX
	SG_ ZV_Einfachhorn_Takt : 54|1@1+ (1,0) [0|1] ""  Vector__XXX
	SG_ ZV_HBFS_Status_KiSi : 16|1@1+ (1,0) [0|1] ""  Vector__XXX
	SG_ ZV_HBFS_TAG_betaetigt : 17|1@1+ (1,0) [0|1] ""  Vector__XXX
	SG_ ZV_HBFS_TIG_oeffnen_betaetigt : 18|1@1+ (1,0) [0|1] ""  Vector__XXX
	SG_ ZV_HBFS_TIG_schliessen_betaetigt : 19|1@1+ (1,0) [0|1] ""  Vector__XXX
	SG_ ZV_HD_Parkbremse_Hinweis : 51|1@1+ (1,0) [0|1] ""  Kombi
	SG_ ZV_HFS_Status_KiSi : 12|1@1+ (1,0) [0|1] ""  Vector__XXX
	SG_ ZV_HFS_TAG_betaetigt : 13|1@1+ (1,0) [0|1] ""  Vector__XXX
	SG_ ZV_HFS_TIG_oeffnen_betaetigt : 14|1@1+ (1,0) [0|1] ""  Vector__XXX
	SG_ ZV_HFS_TIG_schliessen_betaetigt : 15|1@1+ (1,0) [0|1] ""  Vector__XXX
	SG_ ZV_Hupe_Anf : 42|1@1+ (1,0) [0|1] ""  Vector__XXX
	SG_ ZV_Hupe_Takt : 41|1@1+ (1,0) [0|1] ""  Vector__XXX
	SG_ ZV_HW_Motor_Lock_HK : 63|1@1+ (1,0) [0|1] ""  Vector__XXX
	SG_ ZV_HW_Motor_Safe_Hinten : 62|1@1+ (1,0) [0|1] ""  Vector__XXX
	SG_ ZV_HW_TKL_mot_entr : 47|1@1+ (1,0) [0|1] ""  Vector__XXX
	SG_ ZV_HW_TKL_mot_verr : 46|1@1+ (1,0) [0|1] ""  Vector__XXX
	SG_ ZV_Laderaumabd_elektr_aktiviert : 53|1@1+ (1,0) [0|1] ""  Vector__XXX
	SG_ ZV_Status_Cargolock : 43|1@1+ (1,0) [0|1] ""  Vector__XXX
	SG_ ZV_Status_KiSi_CargoLock : 48|3@1+ (1,0) [0|7] ""  Vector__XXX
	SG_ ZV_verriegelt_extern_soll_03 : 44|2@1+ (1,0) [0|3] ""  Vector__XXX

BO_TX_BU_ 975 :ICAS1_X_Gateway;
BO_TX_BU_ 974 :ICAS1_X_Gateway;
BO_TX_BU_ 2463978710 :ICAS1_X_Gateway;
BO_TX_BU_ 1716 :ICAS1_X_Gateway;
BO_TX_BU_ 1057 :ICAS1_X_Gateway;
BO_TX_BU_ 2463978663 :ICAS1_X_Gateway;
BO_TX_BU_ 916 :ICAS1_X_Gateway;
BO_TX_BU_ 1361 :ICAS1_X_Gateway;
BO_TX_BU_ 1369 :ICAS1_X_Gateway;
BO_TX_BU_ 34 :ICAS1_X_Gateway;
BO_TX_BU_ 35 :Fahrerdisplay_Kombi;
BO_TX_BU_ 830 :Fahrerdisplay_Kombi;
BO_TX_BU_ 1702 :ICAS1_X_Gateway;
BO_TX_BU_ 2589283611 :ICAS3_Gateway,ICC_IO_Node,ZR_MIB_TOP_ab_Gen3;
BO_TX_BU_ 2591965953 :SmartLight_01;
BO_TX_BU_ 2589283768 :ICAS1_X_Gateway;
BO_TX_BU_ 1140 :ICAS3_Gateway,ICC_IO_Node,ZR_MIB_TOP_ab_Gen3;
BO_TX_BU_ 2589283965 :ICAS3_Gateway;
BO_TX_BU_ 1411 :ICAS1_X_Gateway;
BO_TX_BU_ 708 :ICAS1_X_Gateway;
CM_ BO_ 1716 "200ms bei D4 und folgende";
CM_ BO_ 916 "ersetzt WBA_02";
CM_ BO_ 1702 "MLBevo";
CM_ SG_ 975 ASW_Warnung_aktiv_HBFS "Abschaltung der Ambientefunktion Tï?½r hinten der Beifahrerseite bei aktiver ASW Warnung an der Fahrertï?½r";
CM_ SG_ 975 HBFS_FH_Bew_hoch "HBFS Fenster bewegt sich in Richtung hoch";
CM_ SG_ 975 HBFS_FH_Bew_tief "HBFS Fenster bewegt sich in Richtung tief";
CM_ SG_ 975 HBFS_FH_Block "Fensterscheibe befindet sich im mechanischen Block (oben oder unten)";
CM_ SG_ 975 HBFS_FH_Fang "Fangbereich ist 4mm von oberer Lippendichtung";
CM_ SG_ 975 HBFS_FH_normiert "Die Position der Fensterheberscheibe ist bekannt.";
CM_ SG_ 975 HBFS_FH_Oeffnung "Gibt den Fensterï?½ffnungswert in % an.";
CM_ SG_ 975 HBFS_FH_S_AutoHoch "Betaetigung FH Schalter auto tief ";
CM_ SG_ 975 HBFS_FH_S_AutoTief "Betaetigung FH Schalter auto hoch";
CM_ SG_ 975 HBFS_FH_S_HFS_AutoHoch "Automatisches Hochfahren der Seitenscheibe HFS";
CM_ SG_ 975 HBFS_FH_S_HFS_AutoTief "Automatisches Absenken der Seitenscheibe HFS";
CM_ SG_ 975 HBFS_FH_S_HFS_ManHoch "Manuelles Hochfahren der Seitenscheibe HFS";
CM_ SG_ 975 HBFS_FH_S_HFS_ManTief "Manuelles Absenken der Seitenscheibe HFS";
CM_ SG_ 975 HBFS_FH_S_ManHoch "Betaetigung FH Schalter man hoch ";
CM_ SG_ 975 HBFS_FH_S_ManTief "Betaetigung FH Schalter man tief";
CM_ SG_ 975 HBFS_FH_Thermo "gibt an ob Fensterheber im Thermoschutz ist";
CM_ SG_ 975 HBFS_gesafet "HBFS Tuer gesafet.\nIm Zustand Safe wird auch das Signal HBFS_verriegelt = 1 gesendet.";
CM_ SG_ 975 HBFS_Heckrollotaster_betaetigt "Verfahren des Heckrollos in Richtung Hoch\n\nBei Einfachtaster wird Bit als Togglebit verwendet (Heckrollo hoch, tief)";
CM_ SG_ 975 HBFS_Lock_Taster "Betaetigung Lock-Taster";
CM_ SG_ 975 HBFS_Lock_Taster_inv "Lock Taster nicht betï?½tigt";
CM_ SG_ 975 HBFS_MRollo_Schalter "  | MRollo2\n-----------------------------\n0 | nicht_betaetigt\n1 | (m) Zu\n2 | (a) Zu\n3 | (m) Auf\n4 | (a) Auf\n5 | Schalter nicht verfuegbar\n6 | Init\n7 | Fehlerfall";
CM_ SG_ 975 HBFS_Oben_Block_erw "Fensterheber in Blockerwartung oben";
CM_ SG_ 975 HBFS_SAD_Schalter "  |   Ausstelldach MD3\n-----------------------------\n0 | nicht_betaetigt\n1 |\n2 |\n3 |\n4 |\n5 | (m) Auf\n6 | (a) Auf\n7 | (m) Zu\n8 | (a) Zu\n13| Schalter nicht verfuegbar\n14| Init\n15| Fehlerfall";
CM_ SG_ 975 HBFS_Seitenrollo_tief "Seitenrollo in Bewegung Richtung tief";
CM_ SG_ 975 HBFS_SK_betaetigt "Status der Sperrklinke";
CM_ SG_ 975 HBFS_Sperrklinke "Vorraste fï?½r Schloï?½\n\nzwischen Vor- und Hauptraste Signal kurz auf 1, danach wieder auf 0 wenn Tï?½r in Hauptraste (Tï?½r ist sicher zu wenn Sperrklinke und Tï?½rkontakt auf 0 sind)";
CM_ SG_ 975 HBFS_Status_eTAG "Status des elektrischen Tueraussengriffes Tuer Beifahrerseite hinten";
CM_ SG_ 975 HBFS_Status_KiSi "Status Kindersicherung HBFS\n";
CM_ SG_ 975 HBFS_Status_KiSi_inv "Inverser Status der elektrischen Kindersicherung Beifahrerseite hinten";
CM_ SG_ 975 HBFS_TAG_betaetigt "Betaetigung Tï?½raussengriff";
CM_ SG_ 975 HBFS_TIG_betaetigt "Betaetigung Tuerinnengriff";
CM_ SG_ 975 HBFS_TIG_betaetigt_oeffnen "Tï?½rinnenbetï?½tigung, Taster Tï?½r ï?½ffnen.";
CM_ SG_ 975 HBFS_TIG_betaetigt_schliessen "Tï?½rinnenbetï?½tigung, Taster Tï?½r schlieï?½en.";
CM_ SG_ 975 HBFS_Tuer_geoeffnet "HBFS Tuer geoeffnet";
CM_ SG_ 975 HBFS_Tuer_Status "Tï?½rstatus mit Fehler und Initwert";
CM_ SG_ 975 HBFS_Tuer_Status_QBit "Dieses Bit gibt die Zuverlï?½ssigkeit des Tï?½rkontakts an. Ein auf dieses Bit folgender Fehlereintrag ist mit dem Sender des Bits abzustimmen (gï?½ltig ab PPE).";
CM_ SG_ 975 HBFS_Tueroeffnen_Warnung "Bit wird gesetzt, wenn Tï?½r wï?½hrend der Fahrt geoeffnet werden soll.";
CM_ SG_ 975 HBFS_Tuerschloss_defekt "Das hintere Tuerschloss auf der Beifahrerseite ist nicht mehr funktionsfï?½hig.";
CM_ SG_ 975 HBFS_UEKB_aktiviert "ï?½berschutzbegrenzungskraft bei Reversieren";
CM_ SG_ 975 HBFS_Unlock_Taster "Betaetigung Unlock Taster";
CM_ SG_ 975 HBFS_Unten_Block_erw "Fensterheber in Blockerwartung unten";
CM_ SG_ 975 HBFS_verriegelt "Verriegelungsstatus Tï?½r";
CM_ SG_ 975 HBFS_Vorraste_betaetigt "Status der Vorraste";
CM_ SG_ 975 HBFS_Zuziehhilfe_aktiv "Zuziehhilfe aktiv";
CM_ SG_ 975 MTHBFS_M_Taste "Betï?½tigung M-Taste HBFS";
CM_ SG_ 975 MTHBFS_Pos1 "Betï?½tigung Postionstaste 1 HBFS";
CM_ SG_ 975 MTHBFS_Pos2 "Betï?½tigung Postionstaste 2 HBFS\n";
CM_ SG_ 975 MTHBFS_Pos3 "Betï?½tigung Postionstaste 3 HBFS";
CM_ SG_ 975 SSR_HBFS_Pos_Unten "Signal fï?½r die 'Global Close'. ï?½ber dieses Bit wissen die anderen TSGs, ob der SSR oder der FH verfahren werden darf.";
CM_ SG_ 974 ASW_Warnung_aktiv_HFS "Abschaltung der Ambientefunktion Tï?½r hinten der Fahrerseite bei aktiver ASW Warnung an der Fahrertï?½r";
CM_ SG_ 974 HFS_FH_Bew_hoch "HFS Fenster bewegt sich in Richtung hoch";
CM_ SG_ 974 HFS_FH_Bew_tief "HFS Fenster bewegt sich in Richtung tief";
CM_ SG_ 974 HFS_FH_Block "Fensterscheibe befindet sich im mechanischen Block (oben oder unten)";
CM_ SG_ 974 HFS_FH_Fang "Fangbereich ist 4mm von oberer Lippendichtung";
CM_ SG_ 974 HFS_FH_normiert "Die Position der Fensterheberscheibe ist bekannt.";
CM_ SG_ 974 HFS_FH_Oeffnung "Gibt den Fensterï?½ffnungswert in % an.";
CM_ SG_ 974 HFS_FH_S_AutoHoch "Betaetigung FH Schalter auto hoch";
CM_ SG_ 974 HFS_FH_S_AutoTief "Betaetigung FH Schalter auto tief ";
CM_ SG_ 974 HFS_FH_S_HBFS_AutoHoch "Automatisches Hochfahren der Seitenscheibe HBFS";
CM_ SG_ 974 HFS_FH_S_HBFS_AutoTief "Automatisches Absenken der Seitenscheibe HBFS";
CM_ SG_ 974 HFS_FH_S_HBFS_ManHoch "Manuelles Hochfahren der Seitenscheibe HBFS";
CM_ SG_ 974 HFS_FH_S_HBFS_ManTief "Manuelles Absenken der Seitenscheibe HBFS";
CM_ SG_ 974 HFS_FH_S_ManHoch "Betaetigung FH Schalter man hoch ";
CM_ SG_ 974 HFS_FH_S_ManTief "Betaetigung FH Schalter man tief";
CM_ SG_ 974 HFS_FH_Thermo "gibt an ob Fensterheber im Thermoschutz ist";
CM_ SG_ 974 HFS_gesafet "HFS Tuer gesafet.\nIm Zustand Safe wird auch das Signal HFS_verriegelt = 1 gesendet.";
CM_ SG_ 974 HFS_Heckrollotaster_betaetigt "Verfahren des Heckrollos in Richtung Hoch\n\nBei Einfachtaster wird Bit als Togglebit verwendet (Heckrollo hoch, tief)";
CM_ SG_ 974 HFS_Lock_Taster "Betï?½tigung Lock-Taster";
CM_ SG_ 974 HFS_Lock_Taster_inv "Lock Taster nicht betï?½tigt";
CM_ SG_ 974 HFS_MRollo_Schalter "  | MRollo2\n-----------------------------\n0 | nicht_betaetigt\n1 | (m) Zu\n2 | (a) Zu\n3 | (m) Auf\n4 | (a) Auf\n5 | Schalter nicht verfuegbar\n6 | Init\n7 | Fehlerfall";
CM_ SG_ 974 HFS_Oben_Block_erw "Fensterheber in Blockerwartung oben";
CM_ SG_ 974 HFS_SAD_Schalter "  |   Ausstelldach MD3\n-----------------------------\n0 | nicht_betaetigt\n1 |\n2 |\n3 |\n4 |\n5 | (m) Auf\n6 | (a) Auf\n7 | (m) Zu\n8 | (a) Zu\n13| Schalter nicht verfuegbar\n14| Init\n15| Fehlerfall";
CM_ SG_ 974 HFS_Seitenrollo_hoch "Seitenrollo in Bewegung Richtung hoch";
CM_ SG_ 974 HFS_Seitenrollo_tief "Seitenrollo in Bewegung Richtung tief";
CM_ SG_ 974 HFS_SK_betaetigt "Status der Sperrklinke";
CM_ SG_ 974 HFS_Sperrklinke "Vorraste fï?½r Schloï?½\n\nzwischen Vor- und Hauptraste Signal kurz auf 1, danach wieder auf 0 wenn Tï?½r in Hauptraste (Tï?½r ist sicher zu wenn Sperrklinke und Tï?½rkontakt auf 0 sind)";
CM_ SG_ 974 HFS_Status_eTAG "Status des elektrischen Tueraussengriffes Tuer Fahrerseite hinten";
CM_ SG_ 974 HFS_Status_KiSi "Status Kindersicherung hinten Fahrerseite";
CM_ SG_ 974 HFS_TAG_betaetigt "Betaetigung Tï?½raussengriff";
CM_ SG_ 974 HFS_TCR_Mode_aktiv "Signal zeigt eine aktive mechanische Redundanz am Tï?½rschloss an.";
CM_ SG_ 974 HFS_TIG_betaetigt "Betaetigung Tï?½rinnengriff";
CM_ SG_ 974 HFS_TIG_betaetigt_oeffnen "Tï?½rinnenbetï?½tigung, Taster Tï?½r ï?½ffnen.";
CM_ SG_ 974 HFS_TIG_betaetigt_schliessen "Tï?½rinnenbetï?½tigung, Taster Tï?½r schlieï?½en.";
CM_ SG_ 974 HFS_Tuer_geoeffnet "HFS Tuer geoeffnet";
CM_ SG_ 974 HFS_Tuer_Status "Tï?½rstatus mit Fehler und Initwert";
CM_ SG_ 974 HFS_Tuer_Status_QBit "Dieses Bit gibt die Zuverlï?½ssigkeit des Tï?½rkontakts an. Ein auf dieses Bit folgender Fehlereintrag ist mit dem Sender des Bits abzustimmen (gï?½ltig ab PPE).";
CM_ SG_ 974 HFS_Tueroeffnen_Warnung "Bit wird gesetzt, wenn Tï?½r wï?½hrend der Fahrt geoeffnet werden soll.";
CM_ SG_ 974 HFS_Tuerschloss_defekt "Das hintere Tuerschloss auf der Fahrerseite ist nicht mehr funktionsfï?½hig.";
CM_ SG_ 974 HFS_UEKB_aktiviert "ï?½berschutzbegrenzungskraft bei Reversieren";
CM_ SG_ 974 HFS_Unlock_Taster "Betaetigung Unlock Taster";
CM_ SG_ 974 HFS_Unten_Block_erw "Fensterheber in Blockerwartung unten";
CM_ SG_ 974 HFS_verriegelt "HFS Tuer verriegelt";
CM_ SG_ 974 HFS_Vorraste_betaetigt "Status der Vorraste";
CM_ SG_ 974 HFS_Zuziehhilfe_aktiv "Zuziehhilfe aktiv";
CM_ SG_ 974 MTHFS_M_Taste "Betï?½tigung M-Taste HFS";
CM_ SG_ 974 MTHFS_Pos1 "Betï?½tigung Postionstaste 1 HFS";
CM_ SG_ 974 MTHFS_Pos2 "Betï?½tigung Postionstaste 2 HFS\n";
CM_ SG_ 974 MTHFS_Pos3 "Betï?½tigung Postionstaste 3 HFS";
CM_ SG_ 974 SSR_HFS_Pos_Unten "Signal fï?½r die 'Global Close'. ï?½ber dieses Bit wissen die anderen TSGs, ob der SSR oder der FH verfahren werden darf.";
CM_ SG_ 2463978710 OPS_ComfortReadyStatus "Das Signal wird durch den Basisdienst User State Server (Technikvariante: OccupantPresenceService) erzeugt und bildet einen neuen Zustand, bestehend aus einer Verknï?½pfung der Fahreranwesenheit (Fahrer abwesend / Fahrer anwesend) und der Klemmensteuerung (";
CM_ SG_ 2463978710 OPS_DriverPresenceStatus "Das Signal wird durch den Basisdienst User State Server (Service: OccupantPresenceService) erzeugt und bildet die Fahrerzustï?½nde im Fahrzeug ab.";
CM_ SG_ 2463978710 OPS_OccupantPresenceStatus "Das Signal wird durch den Basisdienst User State Server (Service: OccupantPresenceService) erzeugt und bildet die Anwesenheit und Abwesenheit aller Insassen im Fahrzeug ab.";
CM_ SG_ 2463978710 OPS_QBit_DriverPresence "Das Signal wird durch den Basisdienst User State Server (Service: OccupantPresenceService) erzeugt und signalisiert die Qualitï?½t der Fahrerzustï?½nde.";
CM_ SG_ 2463978710 OPS_SafeDriverPresence_available "Das Signal signalisiert inwiefern alle vorgesehene Sensoren  fï?½r die Anwesenheit verwendet werden oder mï?½glichweise bestimmte Sensoren nicht verfï?½gbar sind.\nIn beiden Fï?½llen wird eine Anwesenheit berechnet, jedoch bei Ausfall bestimmter Sensoren kann zu ";
CM_ SG_ 2463978710 OPS_SafeDriverPresenceStatus "Signalisierung einer sicheren Fahreranwesenheit nach ASIL B";
CM_ SG_ 1716 VIN_01_MUX "Achtung:\nDie Botschaft ist nicht linear gemultiplext!!!\nSondern 0,1,0,2,0, usw.";
CM_ SG_ 1716 VIN_1 "Initwert:\n0x2D bei Fahrzeugen mit Wegfahrsperrengeneration >= 5 \n0x58 bei Fahrzeugen mit Wegfahrsperrengeneration < 5 (z.B. WFS-4)";
CM_ SG_ 1716 VIN_10 "Initwert:\n0x2D bei Fahrzeugen mit Wegfahrsperrengeneration >= 5 \n0x58 bei Fahrzeugen mit Wegfahrsperrengeneration < 5 (z.B. WFS-4)";
CM_ SG_ 1716 VIN_11 "Initwert:\n0x2D bei Fahrzeugen mit Wegfahrsperrengeneration >= 5 \n0x58 bei Fahrzeugen mit Wegfahrsperrengeneration < 5 (z.B. WFS-4)";
CM_ SG_ 1716 VIN_12 "Initwert:\n0x2D bei Fahrzeugen mit Wegfahrsperrengeneration >= 5 \n0x58 bei Fahrzeugen mit Wegfahrsperrengeneration < 5 (z.B. WFS-4)";
CM_ SG_ 1716 VIN_13 "Initwert:\n0x2D bei Fahrzeugen mit Wegfahrsperrengeneration >= 5 \n0x58 bei Fahrzeugen mit Wegfahrsperrengeneration < 5 (z.B. WFS-4)";
CM_ SG_ 1716 VIN_14 "Initwert:\n0x2D bei Fahrzeugen mit Wegfahrsperrengeneration >= 5 \n0x58 bei Fahrzeugen mit Wegfahrsperrengeneration < 5 (z.B. WFS-4)";
CM_ SG_ 1716 VIN_15 "Initwert:\n0x2D bei Fahrzeugen mit Wegfahrsperrengeneration >= 5 \n0x58 bei Fahrzeugen mit Wegfahrsperrengeneration < 5 (z.B. WFS-4)";
CM_ SG_ 1716 VIN_16 "Initwert:\n0x2D bei Fahrzeugen mit Wegfahrsperrengeneration >= 5 \n0x58 bei Fahrzeugen mit Wegfahrsperrengeneration < 5 (z.B. WFS-4)";
CM_ SG_ 1716 VIN_17 "Initwert:\n0x2D bei Fahrzeugen mit Wegfahrsperrengeneration >= 5 \n0x58 bei Fahrzeugen mit Wegfahrsperrengeneration < 5 (z.B. WFS-4)";
CM_ SG_ 1716 VIN_2 "Initwert:\n0x2D bei Fahrzeugen mit Wegfahrsperrengeneration >= 5 \n0x58 bei Fahrzeugen mit Wegfahrsperrengeneration < 5 (z.B. WFS-4)";
CM_ SG_ 1716 VIN_3 "Initwert:\n0x2D bei Fahrzeugen mit Wegfahrsperrengeneration >= 5 \n0x58 bei Fahrzeugen mit Wegfahrsperrengeneration < 5 (z.B. WFS-4)";
CM_ SG_ 1716 VIN_4 "Initwert:\n0x2D bei Fahrzeugen mit Wegfahrsperrengeneration >= 5 \n0x58 bei Fahrzeugen mit Wegfahrsperrengeneration < 5 (z.B. WFS-4)";
CM_ SG_ 1716 VIN_5 "Initwert:\n0x2D bei Fahrzeugen mit Wegfahrsperrengeneration >= 5 \n0x58 bei Fahrzeugen mit Wegfahrsperrengeneration < 5 (z.B. WFS-4)";
CM_ SG_ 1716 VIN_6 "Initwert:\n0x2D bei Fahrzeugen mit Wegfahrsperrengeneration >= 5 \n0x58 bei Fahrzeugen mit Wegfahrsperrengeneration < 5 (z.B. WFS-4)";
CM_ SG_ 1716 VIN_7 "Initwert:\n0x2D bei Fahrzeugen mit Wegfahrsperrengeneration >= 5 \n0x58 bei Fahrzeugen mit Wegfahrsperrengeneration < 5 (z.B. WFS-4)";
CM_ SG_ 1716 VIN_8 "Initwert:\n0x2D bei Fahrzeugen mit Wegfahrsperrengeneration >= 5 \n0x58 bei Fahrzeugen mit Wegfahrsperrengeneration < 5 (z.B. WFS-4)";
CM_ SG_ 1716 VIN_9 "Initwert:\n0x2D bei Fahrzeugen mit Wegfahrsperrengeneration >= 5 \n0x58 bei Fahrzeugen mit Wegfahrsperrengeneration < 5 (z.B. WFS-4)";
CM_ SG_ 1057 VLK_01_BZ "4bit Botschaftszï?½hler, wird mit jeder Sendebotschaft inkrementiert";
CM_ SG_ 1057 VLK_01_CRC "Fï?½r MLB:\nBerechnung siehe Lastenheft 'Kommunikationsabsicherung fï?½r FlexRay und CAN'\nAb MQB und MLBevo:\nBerechnung siehe Lastenheft 'End-to-End Kommunikationsabsicherung'\n\nEndwerte siehe Begleitdokument 'S-PDU Kennungsfolgen'";
CM_ SG_ 1057 VLK_Anf_Antrieb "Anforderung zur Antriebsfreigabe seitens VLK";
CM_ SG_ 1057 VLK_Anforderung_HMS "Halteanforderung des VLK an HMS aus Funktion Rollsicherung";
CM_ SG_ 1057 VLK_Anforderung_Rollfaehigkeit "Mit diesem Signal wird vom Verlassenskonzept signalisiert, ob der Rollfï?½higkeitsmodus aktiviert ist.";
CM_ SG_ 1057 VLK_Antriebsdeaktivierung "VLK kann mit diesem Signal den Antrieb deaktivieren.";
CM_ SG_ 1057 VLK_autom_Absch_Signalisierung "Signalisierung einer automatisierten Deaktivierung der Zï?½ndung";
CM_ SG_ 1057 VLK_Hinweis_Rollfaehigkeit "Im Signal wird die Meldungsausgabe des Rollfï?½higkeitsmodus im iID mit bzw. ohne Akustik angefordert";
CM_ SG_ 1057 VLK_Parken_beibehalten_HMS "Anforderung durch das Verlassenskonzept, um das Lï?½sen der Parkbremse zu verhindern.";
CM_ SG_ 1057 VLK_VLW_Anf "Anforderndes Signal der Verlassenswarnung fï?½r Fahrzeuge auf technischer Basis MEB. Aufgrund des nicht verbauten Getriebes sind die Signalwerte um die Ersatzreaktionen auf ein fehlerhaftes p_verriegelt reduziert. Ausgabe der Verlassenswarnung erfolgt im Fa";
CM_ SG_ 2463978663 VZE_Akustik_Limitwechsel "Anforderung eines Signaltons bei Tempolimitwechsel.";
CM_ SG_ 2463978663 VZE_Akustik_Limitwechsel_Status "Das Signal ï?½bertrï?½gt die Information, ob der Kunde, in den Einstellungen, die akustische Information, bei einem Tempolimitwechsel, ausgewï?½hlt hat.";
CM_ SG_ 2463978663 VZE_Anhaenger_Vmax "ï?½bertragung der aus Kundeneinstellung und lï?½nderspezifischen Regelungen (StVO, Rechtsprechung...) berechneten legalen Hï?½chstgeschwindigkeit fï?½r das Gespann.\n\n10+ 0*10 = 10 km/h\n10+ 1*10 = 20 km/h\n...\n10+ 5*10 = 60 km/h\n10+ 6*10 = 70 km/h\n...\n10+ 1";
CM_ SG_ 2463978663 VZE_Anzeige_VZ_1 "Das Signal spiegelt eines der Verkehrszeichen: Geschwindigkeitsgebot, ï?½berholverbot, Aufhebungszeichen wider.\n\nWertebereich lt. Hashtabelle";
CM_ SG_ 2463978663 VZE_Anzeige_VZ_2 "Das Signal spiegelt eines der Verkehrszeichen: Geschwindigkeitsgebot, ï?½berholverbot, Aufhebungszeichen wider.\n\nWertebereich lt. Hashtabelle";
CM_ SG_ 2463978663 VZE_Anzeige_VZ_3 "Das Signal spiegelt eines der Verkehrszeichen: Geschwindigkeitsgebot, ï?½berholverbot, Aufhebungszeichen wider.\n\nWertebereich lt. Hashtabelle";
CM_ SG_ 2463978663 VZE_Anzeige_ZS_1 "Zusatzsschild, das zu Verkehrszeichen 1 angezeigt werden soll.\n\nWertebereich lt. Hashtabelle";
CM_ SG_ 2463978663 VZE_Anzeige_ZS_2 "Zusatzsschild, das zu Verkehrszeichen 1 angezeigt werden soll.\n\nWertebereich lt. Hashtabelle";
CM_ SG_ 2463978663 VZE_Anzeige_ZS_3 "Zusatzsschild, das zu Verkehrszeichen 1 angezeigt werden soll.\n\nWertebereich lt. Hashtabelle";
CM_ SG_ 2463978663 VZE_Anzeigemodus "Steuert die verschiedenen Mï?½glichkeiten der Anzeige.";
CM_ SG_ 2463978663 VZE_Anzeigeunterdrueck_Zeichen_1 "Steuerungssignal zur Steuerung der Sichtbarkeit von Verkehrszeichen ";
CM_ SG_ 2463978663 VZE_Anzeigeunterdrueck_Zeichen_2 "Anzeigerelevanz des Zeichens in VZE_Verkehrszeichen_2";
CM_ SG_ 2463978663 VZE_Anzeigeunterdrueck_Zeichen_3 "Anzeigerelevanz des Zeichens in VZE_Verkehrszeichen_3";
CM_ SG_ 2463978663 VZE_Anzeigeunterdrueck_Zeichen_4 "Anzeigerelevanz des Zeichens in VZE_Anzeigerelevanz_Zeichen_4";
CM_ SG_ 2463978663 VZE_Anzeigeunterdrueck_Zeichen_5 "Anzeigerelevanz des Zeichens in VZE_Anzeigerelevanz_Zeichen_5";
CM_ SG_ 2463978663 VZE_Baustelle "Das Signal gibt an, ob aktuell ein Baustellenschild von der VZE erkannt wurde.";
CM_ SG_ 2463978663 VZE_Erweiterte_Information "In dem Signal spiegelt erweiterte Verkehrszeicheninformationen wieder (Ortsschild, Autobahnbeginn, Autobahnende)\n\nWertebereich lt. Hashtabelle";
CM_ SG_ 2463978663 VZE_FoD_Status "Status der VZE fï?½r FoD";
CM_ SG_ 2463978663 VZE_Gong "Das Signal signalisiert dem Kombiinstrument ob bei der VZE-Tempowarnung ein Gong getriggert werden soll.";
CM_ SG_ 2463978663 VZE_Hinweistext "ï?½ber Index wird ein Hinweistext beschrieben, der durch das Kombi dargestellte werden soll.\n\nWertebereich lt. Hashtabelle";
CM_ SG_ 2463978663 VZE_Hinweistext_03 "ï?½ber Index wird ein Hinweistext beschrieben, der durch das Kombi dargestellte werden soll.\n\nWertebereich lt. Hashtabelle";
CM_ SG_ 2463978663 VZE_Land "Steuert die verschiedenen Mï?½glichkeiten der Anzeige.";
CM_ SG_ 2463978663 VZE_Modus_OptischeWarnung "Das Signal gibt an, ob eine optische Warnung blinkend oder dauerhaft ausgegeben werden soll.";
CM_ SG_ 2463978663 VZE_SLWF_Status "Das Signal zeigt den SLWF Zustand der VZE an.";
CM_ SG_ 2463978663 VZE_Tempowarnung_Einheit "0 - Einheit Warnoffset km/h\n1 -  Einheit Warnoffset mph";
CM_ SG_ 2463978663 VZE_Tempowarnung_Offset "das Signal ï?½bertrï?½gt den im CAR:Menï?½ gewï?½hlten Offset fï?½r die VZE-Tempowarnung an das pACC Steuergerï?½t. Die zugrhï?½rige Einheit wird im Signal VZE_Tempowarnung_Einheit ï?½bertragen";
CM_ SG_ 2463978663 VZE_Tempowarnung_Status "0 - Tempowarnung aktiv\n1 -  Tempowarnung desktiv";
CM_ SG_ 2463978663 VZE_Umweltinfo_Anhaengerbetrieb "In dem Signal werden fï?½r die Verkehrszeichenerkennung relevante Umweltinformationen ï?½bertragen.\n\nInfo: Anhï?½ngerbetrieb";
CM_ SG_ 2463978663 VZE_Umweltinfo_Naesse "In dem Signal werden fï?½r die Verkehrszeichenerkennung relevante Umweltinformationen ï?½bertragen.\n\nInfo: Nï?½sse";
CM_ SG_ 2463978663 VZE_Umweltinfo_Nebel "In dem Signal werden fï?½r die Verkehrszeichenerkennung relevante Umweltinformationen ï?½bertragen.\n\nInfo: Nebel";
CM_ SG_ 2463978663 VZE_Verkehrszeichen_1 "Das Signal spiegelt eines der Verkehrszeichen: Geschwindigkeitsgebot, ï?½berholverbot, Aufhebungszeichen wider.\n\nWertebereich lt. Hashtabelle";
CM_ SG_ 2463978663 VZE_Verkehrszeichen_2 "Das Signal spiegelt eines der Verkehrszeichen: Geschwindigkeitsgebot, ï?½berholverbot, Aufhebungszeichen wider.\n\nWertebereich lt. Hashtabelle";
CM_ SG_ 2463978663 VZE_Verkehrszeichen_3 "Das Signal spiegelt eines der Verkehrszeichen: Geschwindigkeitsgebot, ï?½berholverbot, Aufhebungszeichen wider.\n\nWertebereich lt. Hashtabelle";
CM_ SG_ 2463978663 VZE_Verkehrszeichen_4 "Das Signal spiegelt eines der Verkehrszeichen: Geschwindigkeitsgebot, ï?½berholverbot, Aufhebungszeichen wider.\n\nWertebereich lt. Hashtabelle";
CM_ SG_ 2463978663 VZE_Verkehrszeichen_5 "Das Signal spiegelt eines der Verkehrszeichen: Geschwindigkeitsgebot, ï?½berholverbot, Aufhebungszeichen wider.\n\nWertebereich lt. Hashtabelle";
CM_ SG_ 2463978663 VZE_Verkehrszeichen_6 "Das Signal spiegelt eines der Verkehrszeichen: Geschwindigkeitsgebot, ï?½berholverbot, Aufhebungszeichen wider.\n\nWertebereich lt. Hashtabelle";
CM_ SG_ 2463978663 VZE_Verkehrszeichen_Einheit "Signal gibt an ob das ï?½bertragene Verkehrszeichen in mph oder km/h ï?½bermittelt wird";
CM_ SG_ 2463978663 VZE_Warnung_Verkehrszeichen_1 "Ist das Signal gesetzt, so ist fï?½r das Verkehrszeichen 1 eine Warnung auszugeben.";
CM_ SG_ 2463978663 VZE_Warnung_Verkehrszeichen_2 "Ist das Signal gesetzt, so ist fï?½r das Verkehrszeichen 2 eine Warnung auszugeben.";
CM_ SG_ 2463978663 VZE_Warnung_Verkehrszeichen_3 "Ist das Signal gesetzt, so ist fï?½r das Verkehrszeichen 3 eine Warnung auszugeben.";
CM_ SG_ 2463978663 VZE_Warnung_Verkehrszeichen_4 "Ist das Signal gesetzt, so ist fï?½r das Verkehrszeichen 4 eine Warnung auszugeben.";
CM_ SG_ 2463978663 VZE_Warnung_Verkehrszeichen_5 "Ist das Signal gesetzt, so ist fï?½r das Verkehrszeichen 5 eine Warnung auszugeben.";
CM_ SG_ 2463978663 VZE_Warnung_VZ_1 "Ist das Signal gesetzt, so ist fï?½r das Verkehrszeichen 1 eine Warnung auszugeben.";
CM_ SG_ 2463978663 VZE_Warnung_VZ_2 "Ist das Signal gesetzt, so ist fï?½r das Verkehrszeichen 1 eine Warnung auszugeben.";
CM_ SG_ 2463978663 VZE_Warnung_VZ_3 "Ist das Signal gesetzt, so ist fï?½r das Verkehrszeichen 1 eine Warnung auszugeben.";
CM_ SG_ 2463978663 VZE_Zeichen_01_Gesetz "Das VZE-Tempolimit in Verkehrszeichen1  ist das gesetzlich geltende Tempolimit (je Land/Straï?½enklasse).";
CM_ SG_ 2463978663 VZE_Zeichen_01_Kamera "Das VZE-Tempolimit in Verkehrszeichen1 wurde von der Kamera erkannt.";
CM_ SG_ 2463978663 VZE_Zeichen_01_KameraWied "Das VZE-Tempolimit  in Verkehrszeichen1 wurde als Wiederholungsschild von der Kamera erkannt.";
CM_ SG_ 2463978663 VZE_Zeichen_01_Karte "Das VZE-Tempolimit in Verkehrszeichen1 stammt aus den Navigationskartendaten.";
CM_ SG_ 2463978663 VZE_Zeichen_02_Gesetz "Das VZE-Tempolimit in Verkehrszeichen2  ist das gesetzlich geltende Tempolimit (je Land/Straï?½enklasse).";
CM_ SG_ 2463978663 VZE_Zeichen_02_Kamera "Das VZE-Tempolimit in Verkehrszeichen2 wurde von der Kamera erkannt.";
CM_ SG_ 2463978663 VZE_Zeichen_02_KameraWied "Das VZE-Tempolimit  in Verkehrszeichen2 wurde als Wiederholungsschild von der Kamera erkannt.";
CM_ SG_ 2463978663 VZE_Zeichen_02_Karte "Das VZE-Tempolimit in Verkehrszeichen2 stammt aus den Navigationskartendaten.";
CM_ SG_ 2463978663 VZE_Zeichen_03_Gesetz "Das VZE-Tempolimit in Verkehrszeichen3  ist das gesetzlich geltende Tempolimit (je Land/Straï?½enklasse).";
CM_ SG_ 2463978663 VZE_Zeichen_03_Kamera "Das VZE-Tempolimit in Verkehrszeichen3 wurde von der Kamera erkannt.";
CM_ SG_ 2463978663 VZE_Zeichen_03_KameraWied "Das VZE-Tempolimit  in Verkehrszeichen3 wurde als Wiederholungsschild von der Kamera erkannt.";
CM_ SG_ 2463978663 VZE_Zeichen_03_Karte "Das VZE-Tempolimit in Verkehrszeichen3 stammt aus den Navigationskartendaten.";
CM_ SG_ 2463978663 VZE_Zeichen_04_Gesetz "Das VZE-Tempolimit ist das gesetzlich geltende Tempolimit (je Land/Straï?½enklasse).";
CM_ SG_ 2463978663 VZE_Zeichen_04_Kamera "Das VZE-Tempolimit wurde von der Kamera erkannt.";
CM_ SG_ 2463978663 VZE_Zeichen_04_KameraWied "Das VZE-Tempolimit wurde als Wiederholungsschild von der Kamera erkannt.";
CM_ SG_ 2463978663 VZE_Zeichen_04_Karte "Das VZE-Tempolimit stammt aus den Navigationskartendaten.";
CM_ SG_ 2463978663 VZE_Zeichen_05_Entfernung "In dem Signal wird die Entfernung zum Verkehrszeichen5 ï?½bertragen";
CM_ SG_ 2463978663 VZE_Zeichen_05_Entfernung_StdA "In dem Signal wird die Standardabweichung bzgl. der Entfernung zum Verkehrszeichen5 ï?½bertragen ";
CM_ SG_ 2463978663 VZE_Zeichen_05_Gesetz "Das VZE-Tempolimit ist das gesetzlich geltende Tempolimit (je Land/Straï?½enklasse).";
CM_ SG_ 2463978663 VZE_Zeichen_05_Kamera "Das VZE-Tempolimit wurde von der Kamera erkannt.";
CM_ SG_ 2463978663 VZE_Zeichen_05_KameraWied "Das VZE-Tempolimit wurde als Wiederholungsschild von der Kamera erkannt.";
CM_ SG_ 2463978663 VZE_Zeichen_05_Karte "Das VZE-Tempolimit stammt aus den Navigationskartendaten.";
CM_ SG_ 2463978663 VZE_Zeichen_06_Entfernung "In dem Signal wird die Entfernung zum Verkehrszeichen6 ï?½bertragen";
CM_ SG_ 2463978663 VZE_Zeichen_06_Entfernung_StdA "In dem Signal wird die Standardabweichung bzgl. der Entfernung zum Verkehrszeichen6 ï?½bertragen ";
CM_ SG_ 2463978663 VZE_Zusatzschild_1 "Zusatzsschild, das zu Verkehrszeichen 1 angezeigt werden soll.\n\nWertebereich lt. Hashtabelle";
CM_ SG_ 2463978663 VZE_Zusatzschild_2 "Zusatzsschild, das zu Verkehrszeichen 2 angezeigt werden soll.\n\nWertebereich lt. Hashtabelle";
CM_ SG_ 2463978663 VZE_Zusatzschild_3 "Zusatzsschild, das zu Verkehrszeichen 3 angezeigt werden soll.\n\nWertebereich lt. Hashtabelle";
CM_ SG_ 2463978663 VZE_Zusatzschild_4 "Zusatzsschild, das zu Verkehrszeichen 4 angezeigt werden soll.\n\nWertebereich lt. Hashtabelle";
CM_ SG_ 2463978663 VZE_Zusatzschild_5 "Zusatzsschild, das zu Verkehrszeichen 5 angezeigt werden soll.\n\nWertebereich lt. Hashtabelle";
CM_ SG_ 2463978663 VZE_Zusatzschild_6 "Zusatzsschild, das zu Verkehrszeichen 6 angezeigt werden soll.\n\nWertebereich lt. Hashtabelle";
CM_ SG_ 916 GE_Sollgang "Signalisiert den Sollgang, in den getippt werden soll. Abhï?½ngig vom Signal 'WBA_eing_Gang_02' und dem Sollgang kann dann das Kombi die Hochschaltempfehlung in Tip darstellen.";
CM_ SG_ 916 GE_Stoppverbot_Anz_01 "Dieses Signal gibt die detaillierte Begrï?½ndung fï?½r ein Stoppverbot vom Getriebesteuergerï?½t an.";
CM_ SG_ 916 GE_Stoppverbot_Anz_02 "Dieses Signal gibt die detaillierte Begrï?½ndung fï?½r ein Stoppverbot vom Getriebesteuergerï?½t an.";
CM_ SG_ 916 GE_Stoppverbot_Anz_03 "Dieses Signal gibt die detaillierte Begrï?½ndung fï?½r ein Stoppverbot vom Getriebesteuergerï?½t an.";
CM_ SG_ 916 GE_Stoppverbot_Anz_04 "Dieses Signal gibt die detaillierte Begrï?½ndung fï?½r ein Stoppverbot vom Getriebesteuergerï?½t an.";
CM_ SG_ 916 GE_Stoppverbot_Anz_05 "Dieses Signal gibt die detaillierte Begrï?½ndung fï?½r ein Stoppverbot vom Getriebesteuergerï?½t an.";
CM_ SG_ 916 GE_Stoppverbot_Anz_06 "Dieses Signal gibt die detaillierte Begrï?½ndung fï?½r ein Stoppverbot vom Getriebesteuergerï?½t an.";
CM_ SG_ 916 GE_Stoppverbot_Anz_07 "Dieses Signal gibt die detaillierte Begrï?½ndung fï?½r ein Stoppverbot vom Getriebesteuergerï?½t an.";
CM_ SG_ 916 GE_Stoppverbot_Anz_Std "Dieses Signal gibt die detaillierte Begrï?½ndung fï?½r ein Stoppverbot vom Getriebesteuergerï?½t an.";
CM_ SG_ 916 GE_Tipschaltempf_verfuegbar "Signalisierung, ob eine Hochschaltempfehlung im Tipmodus verfï?½gbar ist oder nicht.";
CM_ SG_ 916 GE_Wiederstart_Anz_Std "Dieses Signal gibt die detaillierte Begrï?½ndung fï?½r einen Wiederstart vom Getriebesteuergerï?½t an. ";
CM_ SG_ 916 WBA_03_CRC "Fï?½r MLB:\n'Berechnung siehe Lastenheft 'Kommunikationsabsicherung fï?½r FlexRay und CAN''\n\nAb MQB und MLBevo:\n'Berechnung siehe Lastenheft 'End-to-End Kommunikationsabsicherung''\n\nEndwerte siehe Begleitdokument 'S-PDU Kennungsfolgen'";
CM_ SG_ 916 WBA_Anforderung_Akustik "Anforderung eines Signaltons bei Anwahl der Fahrstufe R";
CM_ SG_ 916 WBA_Blinken "Dieses Bit steuert die Fehlerlampe an oder wird zum Blinken der WBA-Anzeige genutzt - nur falls WBA_Senderkennung = 00 (GSG)\n";
CM_ SG_ 916 WBA_eing_Gang_02 "Das Automatikgetriebe gibt den aktuell eingelegten Gang aus.\nBesonderheiten:\n0x0 = marktabhï?½ngig wird auf Ganganzeige zur Fahrstufe komplett verzichtet\n0xA = kurzzeitige Unterdrï?½ckung der Ganganzeige (z. B. Segeln, Zwischenstellung, etc.)";
CM_ SG_ 916 WBA_Fahrstufe_02 "Bei Automatgetrieben wird in diesem Signal die aktuelle anzuzeigende Fahrstufe ausgegeben.\n\nDie Signalkodierungen 0x9, 0xA und 0xB werden im MSS-R8NF und MQB-A1/B/A2 verwendet.\n\nDie Signalkodierungen 0xC und 0xD werden nur im MQB-A1/B/A2 verwendet.\n";
CM_ SG_ 916 WBA_GE_Texte "Fahrerhinweise fï?½r das Kombi";
CM_ SG_ 916 WBA_GE_Texte_02 "Fahrerhinweise fï?½r das Kombi";
CM_ SG_ 916 WBA_GE_Warnung_02 "Prioritï?½tswarnungen Getriebe";
CM_ SG_ 916 WBA_GE_Zusatzwarnungen "Prioritaetswarnungen Getriebe an Kombi\nAudi MLB Wertebereich 0 bis 3\nVW MQB Projekte verwenden nur den Wertebereich 0 bis 2\nVW MQB Getriebefehler werden ï?½ber das Signal  GE_Warnungen_02 gesendet.";
CM_ SG_ 916 WBA_Schaltschema_02 "Basis-Layout des Schaltschemas zur Anzeige im Kombiinstrument";
CM_ SG_ 916 WBA_Schaltschema_Fahreraktion "Signalisiert Fahreraktion an der Schaltbetaetigung";
CM_ SG_ 916 WBA_Schaltschema_FS_inaktiv "Gibt an, welche Fahrstufen innerhalb von WBA_Schaltschema_02 aktuell nicht erreichbar sind (z.B. aufgrund zu hoher Fahrzeuggeschwindigkeit oder fehlender Fahrbereitschaft).";
CM_ SG_ 916 WBA_Schaltschema_FS_vorwaerts "Zeigt an, welche der zwei Vorwï?½rtsfahrstufen aktiv ist und ob in die inaktive geschaltet werden kann.";
CM_ SG_ 916 WBA_Schaltschema_Tippgasse "Zeigt den Verbau einer Tippgasse zur Anzeige im Schaltschema an.";
CM_ SG_ 916 WBA_Segeln_aktiv "Getriebe geht in den Segelbetrieb";
CM_ SG_ 916 WBA_Shiftlock_Lampe "Signalisiert dem Kombi, dass die Shiftlock-Lampe (grï?½nes 'Bremse treten' Symbol) anzuzeigen ist.\n\nAnmerkung: Signal ist nur von Kombis auszuwerten, die die Shiftlock-Info ï?½ber Soft- oder Hard-LED und nicht als reine Textmeldung anzeigen.";
CM_ SG_ 916 WBA_ZielFahrstufe "Zielfahrprogramm (Darstellung), fï?½r getipptes S/E/M mit neuem Wï?½hlhebel im MQB";
CM_ SG_ 1361 WFS_Betrieb_Lesespule "Schlï?½sselkommunikation ï?½ber die Lesespule";
CM_ SG_ 1361 WFS_ELV_authorisiert "Authorisierung der elektrischen Lenkungsverriegelung an der WFS";
CM_ SG_ 1361 WFS_Fahrerhinweise "Meldungen, Fahrer- und Warnhinweise der Wegfahrsperre";
CM_ SG_ 1361 WFS_ID_Geb_autorisiert "Authorisierung Schluessel (ID-Geber)";
CM_ SG_ 1361 WFS_ID_Geb_autorisiert_in_Kl15 "Authorisierung des Schlï?½ssels im aktiven Klemme-15-Zyklus";
CM_ SG_ 1361 WFS_ID_Geb_steckt "Schluessel (ID-Geber) im Zuendschloss\n";
CM_ SG_ 1361 WFS_Klemmenfreigabe "Freigabe von der WFS zum Einschalten der Klemme 15 und Klemme S";
CM_ SG_ 1361 WFS_Klemmenfreigabe_Signatur "Signatur zur Klemmenfreigabe durch die WFS";
CM_ SG_ 1361 WFS_LF_Aktiv "LF Schluesselkommunikation\n";
CM_ SG_ 1361 WFS_LZ "Anforderung aus Lastenheft WFS V\n";
CM_ SG_ 1361 WFS_LZ_02 "Inbetriebnahme/Anlernzustand der Wegfahrsperre";
CM_ SG_ 1361 WFS_Parken_Status "Schnittstelle zwischen WFS und ZFAS fï?½r das Pilotierte Parken um in Richtung ZFAS den Status der WFS im BCM2 zu kommunizieren";
CM_ SG_ 1361 WFS_Safe "Status WFS";
CM_ SG_ 1361 WFS_Schluessel_Fahrberecht "Schlï?½sselnummer Fahrberechtigung\n0 = ungueltig, xxxx = Schluessel-Nr.";
CM_ SG_ 1361 WFS_Schluessel_Ist "Istwert der gelernten Schluessel";
CM_ SG_ 1361 WFS_Schluessel_Soll "Sollwert der zu lernenden Schluessel";
CM_ SG_ 1361 WFS_Verbauinfo_ELV "Info ï?½ber die Konfiguration der ELV im WFS-Master";
CM_ SG_ 1369 SOK_WFS01_Signatur "Signatur im Rahmen der durch SOK geschï?½tzen Broadcast-Kommunikation\n\nGeschï?½tzte Funktion: Car2Car\nGeschï?½tzte Signale: WFS_ID_Geb_autorisiert_in_Kl15\nGeschï?½tzte Botschaft: WFS_01";
CM_ SG_ 34 WFS_Transponder_Req_02_Data "Transponderdaten von WFS-Master an Kombi senden";
CM_ SG_ 35 WFS_Transponder_Resp_02_Data "Transponderdaten von Kombi an WFS-Master senden";
CM_ SG_ 830 WFS_Diag_LF_Aktiv_02 "Transponderdiagnose ist aktiv (nicht WFS)";
CM_ SG_ 830 WFS_LF_aktiv_02 "LF aktiv, Zugriff auf Transponder";
CM_ SG_ 830 WFS_Transp_Mod_Unterbrechung_02 "Transponder Gateway verlï?½sst Modus Sleep oder Unterspannung";
CM_ SG_ 830 WFS_Verbau_Transp_Ant_02 "Kodierung Funktion Transponderantenne";
CM_ SG_ 1702 BCM1_SRA_aktiv "Status Scheinwerferreinigungsanlage";
CM_ SG_ 1702 Waschen_vorne_aktiv "Status: Waschen vorne aktiv";
CM_ SG_ 1702 Wischer1_Wischgeschwindigkeit "aktuelle, durch Sensorik gemessene Wischgeschwindigkeit";
CM_ SG_ 1702 Wischer_Anzeigetext "Das Signal fordert einen Kombi-Pop-Up mit entsprechenden Texten an";
CM_ SG_ 1702 Wischer_vorne_aktiv "Status: Wischer vorne";
CM_ SG_ 1702 Wischer_vorne_blockiert "Blockade Wischer vorne (z.B. durch Schnee)";
CM_ SG_ 1702 Wischer_vorne_defekt "Fehlerstatus Wischer vorne (Anzeige im Kombi)";
CM_ SG_ 1702 Wischer_vorne_Normal "Wischer Front normal aktiv";
CM_ SG_ 1702 Wischer_vorne_Parklage "Wischer Front in Parklage";
CM_ SG_ 1702 Wischer_vorne_Schnell "Wischer vorne schnell aktiv";
CM_ SG_ 1702 Wischer_WH_PopUp_Anf "Anzeige von Wischerstufen im Kombi.";
CM_ SG_ 1702 Wischer_WH_Typ "Signal beinhaltet Lenkstockschaltertyp fï?½r grafische Anzeige im Kombi zur Wischerfunktion";
CM_ SG_ 1702 WWSs_01_alt "Veraltet Bit fï?½r die LIN-Botschaft WWSs_01.\n\nBetroffene Signale:\n\nWischer_vorne_aktiv";
CM_ SG_ 2589283611 WLC1_aktive_Spule "Active_Coil";
CM_ SG_ 2589283611 WLC1_Charger_Effizienz "Charger charging (Efficiency in % )\n0 = no charging \n1 = charging with 1%\n10 = charging with 10 %";
CM_ SG_ 2589283611 WLC1_Charger_laedt "Charger charging (ï?½bertragene Leistung) (0,1W)\n\n0 = no charging \n1 = charging with 0,1 Watt\n10 = charging with 1 Watt";
CM_ SG_ 2589283611 WLC1_Fehler "ï?½bermittelt auftretende Fehler des WLC an das Master-SG zur Ablage im dort verorteten Fehlerspeicher";
CM_ SG_ 2589283611 WLC1_Fremdobjekt_erkannt "Messwert/Anzeige Fremdobjekt erkannt";
CM_ SG_ 2589283611 WLC1_Leistungsklasse_Receiver "Performance_Class_Receiver\n0 = no Device\n1 = class with 0,1 Watt\n10 = class with 1 Watt";
CM_ SG_ 2589283611 WLC1_Objekt_erkannt "non wireless Charging Device in the storage box ";
CM_ SG_ 2589283611 WLC1_Receiver_erkannt "wireless Charging Device (Phone) is in the storage box ";
CM_ SG_ 2589283611 WLC1_Receiver_voll_geladen "0 = WLC not fully charged or no Device available\n1 = WLC Device fully charged ";
CM_ SG_ 2589283611 WLC1_Temp_Leistungsteil_Charger "Temperature_Power_Electronics\n0 = -58 ï?½C\n1 = -57 ï?½C\n..";
CM_ SG_ 2589283611 WLC1_Temp_Oberfaeche_Charger "Surface_Temperature_WLC\n0 = -58 ï?½C\n1 = -57 ï?½C\n..";
CM_ SG_ 2589283611 WLC1_Temp_Receiver "Temperature_Receiver\n0 = -58 ï?½C\n1 = -57 ï?½C\n..";
CM_ SG_ 2589283611 WLC1_verwendeter_Ladestandard "WLC_technology";
CM_ SG_ 2589283768 BasicUTC_Day "UTC-Datum: Tag des Monats";
CM_ SG_ 2589283768 BasicUTC_Hour "UTC-Zeit: Stunde des Tages";
CM_ SG_ 2589283768 BasicUTC_Minute "UTC-Zeit: Minute der Stunde";
CM_ SG_ 2589283768 BasicUTC_Month "UTC-Datum: Monat des Jahres";
CM_ SG_ 2589283768 BasicUTC_Quality "UTC: Signalgï?½te";
CM_ SG_ 2589283768 BasicUTC_Second "UTC-Zeit: Sekunde der Minute\n\nDer Sekundenwert nimmt regulï?½r einen Wert im Bereich 0 bis 59 an.\nIm Moment einer Schaltsekunde wird der Wert 60 ausgegeben.";
CM_ SG_ 2589283768 BasicUTC_Year "UTC-Datum: Jahr";
CM_ SG_ 1140 DI_Screendesign "Information welcher Designwunsch ausgewï?½hlt wurde zur Kennlinienumschaltung";
CM_ SG_ 1140 MMI_State "Powerstate des Zentralrechners. MMI_Off wird im Zustand dead mode gesendet.";
CM_ SG_ 1140 SI_ICAN "MQB: Busruhe ICAN.\nE3: Busruhe ABCAN.";
CM_ SG_ 1140 WLC1_Systemzustand "0 = Wireless Charger off (Message produced by HMI)\n1 = Wireless Charger on (Message produced by HMI)";
CM_ SG_ 1140 WLC2_Systemzustand "0 = Wireless Charger off\n1 = Wireless Charger on";
CM_ SG_ 1140 ZR_DimOffs_DU_1 "Dimmungs-Offset der Display Unit.";
CM_ SG_ 1140 ZR_DimOffs_DU_2 "Dimmungs-Offset der Display Unit.";
CM_ SG_ 1140 ZR_DimOffs_DU_3 "Dimmungs-Offset der Display Unit.";
CM_ SG_ 1140 ZR_DimOffs_DU_4 "Dimmungs-Offset der Display Unit.";
CM_ SG_ 1140 ZR_Lenkerposition "Ueber Diagnose (Codierung) im Zentralrechner eingespeicherte Lenkerposition\n";
CM_ SG_ 1140 ZR_State_DU_1 "Kontrollbit fï?½r Display, Hintergrundbeleuchtung aus, Hintergrundbeleuchtung an, Energiesparmodus.\n";
CM_ SG_ 1140 ZR_State_DU_2 "Kontrollbit fï?½r Display, Hintergrundbeleuchtung aus, Hintergrundbeleuchtung an, Energiesparmodus.\n";
CM_ SG_ 1140 ZR_State_DU_3 "Kontrollbit fï?½r Display, Hintergrundbeleuchtung aus, Hintergrundbeleuchtung an, Energiesparmodus.\n";
CM_ SG_ 1140 ZR_State_DU_4 "Kontrollbit fï?½r Display, Hintergrundbeleuchtung aus, Hintergrundbeleuchtung an, Energiesparmodus.";
CM_ SG_ 1140 ZR_WecktGesp "Befehl zum Sperren der Wecktasten am Bedienteil.";
CM_ SG_ 2589283965 DFB_CILState_ADA "Gibt den Status der Bedieneingaben im ABT hinsichtlich der Kritikalitï?½t auf die Unaufmerksamkeit des Fahrers an.";
CM_ SG_ 2589283965 DFB_InteractionStatus_ADA "Gibt an, ob eine Bedieneingabe vom Kunde im ABT durchgefï?½hrt wurde.";
CM_ SG_ 2589283965 SpeechAssistant_State "This signal contain the information if a speech assistant is active or not.";
CM_ SG_ 2589283965 ZR_Plattform "Fahrzeug-Plattform (vom Zentralrechner am I-CAN bzw. AB-CAN genutzte Datenfestlegungsversion)";
CM_ SG_ 1411 BCM_FH_Freigabe "Funktionsfreigabe Fensterheber";
CM_ SG_ 1411 BCM_HSK_Freigabe "Handschuhkastenfreigabe";
CM_ SG_ 1411 BCM_Komfortfkt_Freigabe "globale Freigabe der Komfortfunktion";
CM_ SG_ 1411 BCM_Verdeck_Freigabe "Freigabe Verdeckbetrieb\n";
CM_ SG_ 1411 DWA_aktiv "Status DWA  aktiv";
CM_ SG_ 1411 FBS_IDG_in_Reichweite "Fï?½r elektrisch betï?½tigte Tï?½ren und Klappen muss fï?½r eine Betï?½tigung ï?½ber Funk eine Reichweitenbegrenzung eingefï?½hrt werden. Diese Bit zeigt an, dass sich der Funkschlï?½ssel innerhalb der geforderten Reichweite befindet";
CM_ SG_ 1411 FBS_Warn_Schluessel_Batt "Kombi Prio Warnung Schluessel Batterie\n'Bitte Schlï?½sselbatterie wechseln!'";
CM_ SG_ 1411 FFB_Auf_Taste "Auf-Taste Funkschluessel\n\n";
CM_ SG_ 1411 FFB_CarFinder "Car Finder Funktion (Blinken ohne zu entriegeln)";
CM_ SG_ 1411 FFB_HDF_Taste "HDF Taste am Funkschluessel\n";
CM_ SG_ 1411 FFB_Komfortoeffnen "Komfortoeffnen Funk\n";
CM_ SG_ 1411 FFB_Komfortschliessen "Komfortschliessen Funk\n";
CM_ SG_ 1411 FFB_Panik_Taste "Panik Taste Funkschluessel\n";
CM_ SG_ 1411 FFB_Zu_Taste "Zu-Taste Funkschluessel\n";
CM_ SG_ 1411 IRUE_aktiv "Status Innenraumï?½berwachung\n";
CM_ SG_ 1411 IRUE_Taster_Fkts_LED "Anforderung Funktions-LED IRUE-Taster (LED wird vom TSG angesteuert)\nMQB: Bei Verbau eines einzelnen Taster zur Deaktivierung von IRUE und NGS wird dieses Signal zur Ansteuerung der Funktions-LED gesendet.";
CM_ SG_ 1411 VIP_Sensor_STSG_HBFS_betaetigt "Schiebetï?½rlauf HBFS wurde durch VIP angefordert und als berechtigt eingestuft.";
CM_ SG_ 1411 VIP_Sensor_STSG_HFS_betaetigt "Schiebetï?½rlauf HFS wurde durch VIP angefordert und als berechtigt eingestuft.";
CM_ SG_ 1411 ZV_Anf_Challenge_Auth "Anforderung an alle beteiligten Steuergerï?½te die Challenge an den ZV-Master zu senden.";
CM_ SG_ 1411 ZV_BT_offen "gespiegeltes Bit BT_Tuer_geoeffnet TSG_BT_1 Botschaft";
CM_ SG_ 1411 ZV_Einzeltuerentriegelung "Einzeltï?½rentriegelung ZV\n";
CM_ SG_ 1411 ZV_eRWK_Umfeld_Pruefung "Anforderung an PDC/PLA im eRWK-Modus eine Umfeldprï?½fung durchzufï?½hren";
CM_ SG_ 1411 ZV_FT_offen "gespiegeltes Bit FT_Tuer_geoeffnet TSG_FT_1 Botschaft";
CM_ SG_ 1411 ZV_gesafet_extern_ist "Istzustand: Fahrzeug aussen gesafet\n";
CM_ SG_ 1411 ZV_gesafet_extern_soll "Sollzustand: Fahrzeug gesafet extern\n";
CM_ SG_ 1411 ZV_HBFS_offen "gespiegeltes Bit HBFS_Tuer_geoeffnet TSG_HBFS_1 Botschaft";
CM_ SG_ 1411 ZV_HD_offen "Status Heckdeckel\n";
CM_ SG_ 1411 ZV_Heckeinzelentriegelung "Heckdeckeleinzelentriegelung";
CM_ SG_ 1411 ZV_HFS_offen "gespiegeltes Bit HFS_Tuer_geoeffnet TSG_HFS_1 Botschaft";
CM_ SG_ 1411 ZV_HS_offen "Status Heckscheibe\n";
CM_ SG_ 1411 ZV_ist_Zustand_verfuegbar "Verfï?½gbarkeit IST-Zustand ZV\n\n";
CM_ SG_ 1411 ZV_Oeffnungsmodus "Konfigurierter Oeffnungsmodus fuer ZV:\n0 = globale Oeffnung (alle Tueren)\n1 = ZV mit Einzeltuerentriegelung (FFB - nur Fahrertuer, Kessy - nur bediente Tuer)\n2 = ZV individuell selektive Oeffnung (FFB - Fahrerseite, Kessy - bediente Tuer + Fahrertuer)";
CM_ SG_ 1411 ZV_Rollo_auf "Komfortï?½ffnen des Dachrollos";
CM_ SG_ 1411 ZV_Rollo_zu "Komfortschlieï?½en des Dachrollos";
CM_ SG_ 1411 ZV_SAD_auf "Komfortï?½ffnen des Schiebeausstelldaches";
CM_ SG_ 1411 ZV_SAD_zu "Komfortschlieï?½en des Schiebeausstelldaches";
CM_ SG_ 1411 ZV_SafeFunktion_aktiv "Statusï?½bermittlung ob die Safe Funktion im Fzg. aktiv ist. Das Kombi benï?½tigt das Signal, um den Text Safelock aktiv anzuzeigen. ";
CM_ SG_ 1411 ZV_Schluessel_Zugang "aktuelle Funkschlï?½sselnummer";
CM_ SG_ 1411 ZV_STSG_HBFS_Anf "Die ZV fordert einen Lauf bzw. Stopp der Schiebetï?½r an.";
CM_ SG_ 1411 ZV_STSG_HFS_Anf "Die ZV fordert einen Lauf bzw. Stopp der Schiebetï?½r an.";
CM_ SG_ 1411 ZV_Tankklappe_offen "ï?½ffnungsstatus der Tankklappe";
CM_ SG_ 1411 ZV_verriegeln_Anf "Gesammelte externe ZV-Verriegelungsanforderung des Kunden (z. B. zur Aktivierung der Anzeige des Ladezustands ï?½ber Aussenlicht).";
CM_ SG_ 1411 ZV_verriegelt_extern_ist "Istzustand: Verriegelung Fahrzeug aussen\n";
CM_ SG_ 1411 ZV_verriegelt_extern_soll "Sollzustand: Verriegelung Fahrzeug aussen\n";
CM_ SG_ 1411 ZV_verriegelt_intern_ist "Istzustand: Verriegelung Fahrzeug innen\n";
CM_ SG_ 1411 ZV_verriegelt_intern_soll "Sollzustand: Verriegelung Fahrzeug innen\n";
CM_ SG_ 1411 ZV_verriegelt_soll "Fahrzeug Gesamtverriegelungsstatus Sollzustand fï?½r Ladestecker- und Ladeklappenverriegelung. ";
CM_ SG_ 708 BCM_Waehlhebel_P_Hinweis "Infotext NAR fï?½r die Vorbedingung 'Waehlhebel in P' fï?½r ï?½ffnen der Heckklappe ï?½ber den Fahrerrauminnentaster.";
CM_ SG_ 708 UHF_FFB_Funkschluesseltyp "Typ des Funkschluessels und Funkfrequenzen";
CM_ SG_ 708 UHF_FFB_SKC_anlernen "Neuer FFB_SKC von der WFS-Applikation";
CM_ SG_ 708 ZV_04_BZ "4bit Botschaftszï?½hler, wird mit jeder Sendebotschaft inkrementiert";
CM_ SG_ 708 ZV_04_CRC "Fï?½r MLB:\nBerechnung siehe Lastenheft 'Kommunikationsabsicherung fï?½r FlexRay und CAN'\nAb MQB und MLBevo:\nBerechnung siehe Lastenheft 'End-to-End Kommunikationsabsicherung'\n\nEndwerte siehe Begleitdokument 'S-PDU Kennungsfolgen'";
CM_ SG_ 708 ZV_DWA_Einfachhorn_Anf "Anforderung zur Ansteuerung der Einfachhorns (statisches Signal)";
CM_ SG_ 708 ZV_DWA_Einfachhorn_Takt "Takt fï?½r die Ansteuerung des Einfachhorns ï?½ber SWC-QTG";
CM_ SG_ 708 ZV_Einfachhorn_Anf "Anforderung zur Ansteuerung der Einfachhorns (statisches Signal) durch die ZV";
CM_ SG_ 708 ZV_Einfachhorn_Takt "Takt fï?½r die Ansteuerung des Einfachhorns ï?½ber SWC-ZV";
CM_ SG_ 708 ZV_HBFS_Status_KiSi "Status der Kindersicherung: aktiv-inaktiv\nhinten Beifahrerseite";
CM_ SG_ 708 ZV_HBFS_TAG_betaetigt "Status des Tï?½rauï?½engriffs, betatigt-nicht betaetigt\nhinten Beifahrerseite";
CM_ SG_ 708 ZV_HBFS_TIG_oeffnen_betaetigt "Status des Tï?½rinnengriffs_oeffnen, betaetigt-nicht betaetigt\nhinten Beifahrerseite";
CM_ SG_ 708 ZV_HBFS_TIG_schliessen_betaetigt "Status des Tï?½rinnengriffs_schliessen, betaetigt-nicht betaetigt\nhinten Beifahrerseite";
CM_ SG_ 708 ZV_HD_Parkbremse_Hinweis "Infotext NAR fï?½r die Vorbedingung 'Parkbremse aktiv' fï?½r ï?½ffnen der Heckklappe ï?½ber den Fahrerrauminnentaster.";
CM_ SG_ 708 ZV_HFS_Status_KiSi "Status der Kindersicherung: aktiv-inaktiv\nhinten Fahrerseite";
CM_ SG_ 708 ZV_HFS_TAG_betaetigt "Status des Tï?½rauï?½engriffs, betatigt-nicht betaetigt\nhinten Fahrerseite";
CM_ SG_ 708 ZV_HFS_TIG_oeffnen_betaetigt "Status des Tï?½rinnengriffs_oeffnen, betaetigt-nicht betaetigt\nhinten Fahrerseite";
CM_ SG_ 708 ZV_HFS_TIG_schliessen_betaetigt "Status des Tï?½rinnengriffs_schliessen, betaetigt-nicht betaetigt\nhinten Fahrerseite";
CM_ SG_ 708 ZV_Hupe_Anf "Anforderung zur Ansteuerung des Signalhorns (statisches Signal) durch die ZV";
CM_ SG_ 708 ZV_Hupe_Takt "Takt fï?½r die Ansteuerung des Signalhorns ï?½ber SWC-ZV";
CM_ SG_ 708 ZV_HW_Motor_Lock_HK "Ansteuervorgabe fï?½r den Schlossmotor der Heckklappe";
CM_ SG_ 708 ZV_HW_Motor_Safe_Hinten "Ansteuervorgabe fï?½r die Safemotoren Hinten";
CM_ SG_ 708 ZV_HW_TKL_mot_entr "Ansteuerung des Tankklappenmotors fï?½r die Entriegelung";
CM_ SG_ 708 ZV_HW_TKL_mot_verr "Ansteuerung des Tankklappenmotors fï?½r die Verriegelung";
CM_ SG_ 708 ZV_Laderaumabd_elektr_aktiviert "Komfortï?½ffnen Elektrische Laderaumabdeckung aktiviert";
CM_ SG_ 708 ZV_Status_Cargolock "Status der CargoLock-Funktion";
CM_ SG_ 708 ZV_Status_KiSi_CargoLock "Status Kindersicherung oder Status des CargoLock (abhï?½ngig von der Austattungsvariante)";
CM_ SG_ 708 ZV_verriegelt_extern_soll_03 "Sollzustand: Verriegelung Fahrzeug aussen";
BA_DEF_ BO_ "CANFD_BRS" ENUM "0", "1";
BA_DEF_ BO_ "DiagRequest" ENUM "No", "Yes";
BA_DEF_ BO_ "DiagResponse" ENUM "No", "Yes";
BA_DEF_ BO_ "DiagState" ENUM "No", "Yes";
BA_DEF_ BO_ "GenMsgChkConstant" HEX 0 4095;
BA_DEF_ BO_ "GenMsgCycleTime" INT 0 65535;
BA_DEF_ BO_ "GenMsgCycleTimeFast" INT 0 65535;
BA_DEF_ BO_ "GenMsgDelayTime" INT 0 100000;
BA_DEF_ BO_ "GenMsgILSupport" ENUM "No", "Yes";
BA_DEF_ BO_ "GenMsgNrOfRepetition" INT 0 100;
BA_DEF_ BO_ "GenMsgPDUConstants" STRING;
BA_DEF_ BO_ "GenMsgSendType" ENUM "Cyclic", "not_used", "not_used", "not_used", "not_used", "not_used", "not_used", "IfActive", "NoMsgSendType";
BA_DEF_ BO_ "GenMsgStartDelayTime" INT 0 100000;
BA_DEF_ BO_ "MsgType" ENUM "Application", "NM ", "NMH", "TP2.0", "ISO-TP ", "BAP", "EID", "KS", "XCP_PRE_CONFIGURED", "XCP_RUNTIME_CONFIGURED";
BA_DEF_ BO_ "NmMessage" ENUM "No", "Yes";
BA_DEF_ BO_ "NmhMessage" ENUM "No", "Yes";
BA_DEF_ BO_ "VAGTP20_API" HEX 0 255;
BA_DEF_ BO_ "VAGTP20_DynConnection" ENUM "No", "Yes";
BA_DEF_ BO_ "VAGTP20_DynSetup" ENUM "No", "Yes";
BA_DEF_ BO_ "VAGTP20_StatConnection" ENUM "No", "Yes";
BA_DEF_ BO_ "VFrameFormat" ENUM "StandardCAN", "ExtendedCAN", "reserved", "reserved", "reserved", "reserved", "reserved", "reserved", "reserved", "reserved", "reserved", "reserved", "reserved", "reserved", "StandardCAN_FD", "ExtendedCAN_FD";
BA_DEF_ SG_ "Fehlerwert" HEX 0 2147483647;
BA_DEF_ SG_ "GenSigActiveRepetitions" INT -2147483648 2147483647;
BA_DEF_ SG_ "GenSigFuncType" ENUM "NoFunction", "MsgCounter", "CRC-8", "XOR", "XOR-2", "DatedBit", "SW-Kl15", "CHK", "Constant", "Protocol", "CRC-8-SAE_J1850", "CRC-32", "DataLength", "DataID", "MsgCounter16", "SOK-Signatur", "Cluster";
BA_DEF_ SG_ "GenSigInactiveValue" INT -2147483648 2147483647;
BA_DEF_ SG_ "GenSigMissingSourceValue" HEX 0 2147483647;
BA_DEF_ SG_ "GenSigSendType" ENUM "Cyclic", "OnWrite", "OnWriteWithRepetition", "OnChange", "OnChangeWithRepetition", "IfActive", "IfActiveWithRepetition", "NoSigSendType", "OnChangeAndIfActive", "OnChangeAndIfActiveWithRepetition";
BA_DEF_ SG_ "GenSigStartValue" INT -2147483648 2147483647;
BA_DEF_ SG_ "GenSigSwitchedByIgnition" ENUM "No", "Yes";
BA_DEF_ SG_ "NWM-WakeupAllowed" ENUM "No", "Yes";

BA_DEF_REL_ BU_SG_REL_ "GenSigTimeoutTime" INT 0 65535;
BA_DEF_DEF_ "CANFD_BRS" "1";
BA_DEF_DEF_ "DiagRequest" "No";
BA_DEF_DEF_ "DiagResponse" "No";
BA_DEF_DEF_ "DiagState" "No";
BA_DEF_DEF_ "Fehlerwert" 0;
BA_DEF_DEF_ "GenMsgChkConstant" 0;
BA_DEF_DEF_ "GenMsgCycleTime" 0;
BA_DEF_DEF_ "GenMsgCycleTimeFast" 0;
BA_DEF_DEF_ "GenMsgDelayTime" 0;
BA_DEF_DEF_ "GenMsgILSupport" "No";
BA_DEF_DEF_ "GenMsgNrOfRepetition" 0;
BA_DEF_DEF_ "GenMsgPDUConstants" "";
BA_DEF_DEF_ "GenMsgSendType" "NoMsgSendType";
BA_DEF_DEF_ "GenMsgStartDelayTime" 0;
BA_DEF_DEF_ "GenSigActiveRepetitions" 0;
BA_DEF_DEF_ "GenSigFuncType" "NoFunction";
BA_DEF_DEF_ "GenSigInactiveValue" 0;
BA_DEF_DEF_ "GenSigMissingSourceValue" 0;
BA_DEF_DEF_ "GenSigSendType" "NoSigSendType";
BA_DEF_DEF_ "GenSigStartValue" 0;
BA_DEF_DEF_ "GenSigSwitchedByIgnition" "Yes";
BA_DEF_DEF_ "MsgType" "Application";
BA_DEF_DEF_ "NWM-WakeupAllowed" "No";
BA_DEF_DEF_ "NmMessage" "No";
BA_DEF_DEF_ "NmhMessage" "No";
BA_DEF_DEF_ "VAGTP20_API" 0;
BA_DEF_DEF_ "VAGTP20_DynConnection" "No";
BA_DEF_DEF_ "VAGTP20_DynSetup" "No";
BA_DEF_DEF_ "VAGTP20_StatConnection" "No";
BA_DEF_DEF_ "VFrameFormat" "StandardCAN";
BA_DEF_DEF_REL_ "GenSigTimeoutTime" 0;
BA_ "GenMsgCycleTime" BO_ 975 100;
BA_ "GenMsgDelayTime" BO_ 975 20;
BA_ "GenMsgILSupport" BO_ 975 1;
BA_ "GenMsgSendType" BO_ 975 0;
BA_ "VFrameFormat" BO_ 975 14;
BA_ "GenMsgCycleTime" BO_ 974 100;
BA_ "GenMsgDelayTime" BO_ 974 20;
BA_ "GenMsgILSupport" BO_ 974 1;
BA_ "GenMsgSendType" BO_ 974 0;
BA_ "VFrameFormat" BO_ 974 14;
BA_ "GenMsgCycleTime" BO_ 2463978710 100;
BA_ "GenMsgCycleTimeFast" BO_ 2463978710 10;
BA_ "GenMsgDelayTime" BO_ 2463978710 10;
BA_ "GenMsgILSupport" BO_ 2463978710 1;
BA_ "GenMsgNrOfRepetition" BO_ 2463978710 5;
BA_ "GenMsgPDUConstants" BO_ 2463978710 "0xf3,0xbb,0x4c,0x48,0x05,0x08,0x69,0xc8,0x60,0x76,0x27,0x02,0x3a,0xa8,0x32,0x51";
BA_ "GenMsgSendType" BO_ 2463978710 0;
BA_ "VFrameFormat" BO_ 2463978710 15;
BA_ "GenMsgCycleTime" BO_ 1716 200;
BA_ "GenMsgILSupport" BO_ 1716 1;
BA_ "GenMsgSendType" BO_ 1716 0;
BA_ "VFrameFormat" BO_ 1716 14;
BA_ "GenMsgCycleTime" BO_ 1057 100;
BA_ "GenMsgDelayTime" BO_ 1057 50;
BA_ "GenMsgILSupport" BO_ 1057 1;
BA_ "GenMsgPDUConstants" BO_ 1057 "0x8e,0x95,0xed,0x45,0x8d,0x80,0x23,0x35,0x30,0x56,0x14,0xf1,0x38,0x42,0xba,0x1d";
BA_ "GenMsgSendType" BO_ 1057 0;
BA_ "VFrameFormat" BO_ 1057 14;
BA_ "GenMsgCycleTime" BO_ 2463978663 200;
BA_ "GenMsgDelayTime" BO_ 2463978663 40;
BA_ "GenMsgILSupport" BO_ 2463978663 1;
BA_ "GenMsgSendType" BO_ 2463978663 0;
BA_ "VFrameFormat" BO_ 2463978663 15;
BA_ "GenMsgCycleTime" BO_ 916 160;
BA_ "GenMsgDelayTime" BO_ 916 10;
BA_ "GenMsgILSupport" BO_ 916 1;
BA_ "GenMsgPDUConstants" BO_ 916 "0x47,0x94,0x92,0x6a,0x67,0xb5,0x0d,0x38,0xe3,0x8a,0x5d,0xb4,0x54,0xab,0xae,0x27";
BA_ "GenMsgSendType" BO_ 916 0;
BA_ "VFrameFormat" BO_ 916 14;
BA_ "GenMsgCycleTime" BO_ 1361 200;
BA_ "GenMsgDelayTime" BO_ 1361 50;
BA_ "GenMsgILSupport" BO_ 1361 1;
BA_ "GenMsgSendType" BO_ 1361 0;
BA_ "VFrameFormat" BO_ 1361 14;
BA_ "GenMsgCycleTime" BO_ 1369 200;
BA_ "GenMsgDelayTime" BO_ 1369 50;
BA_ "GenMsgSendType" BO_ 1369 0;
BA_ "VFrameFormat" BO_ 1369 14;
BA_ "VFrameFormat" BO_ 34 14;
BA_ "VFrameFormat" BO_ 35 14;
BA_ "GenMsgCycleTime" BO_ 830 1000;
BA_ "GenMsgDelayTime" BO_ 830 10;
BA_ "GenMsgILSupport" BO_ 830 1;
BA_ "GenMsgSendType" BO_ 830 0;
BA_ "VFrameFormat" BO_ 830 14;
BA_ "GenMsgCycleTime" BO_ 1702 1000;
BA_ "GenMsgDelayTime" BO_ 1702 50;
BA_ "GenMsgILSupport" BO_ 1702 1;
BA_ "GenMsgSendType" BO_ 1702 0;
BA_ "VFrameFormat" BO_ 1702 14;
BA_ "GenMsgCycleTime" BO_ 2589283611 1000;
BA_ "GenMsgDelayTime" BO_ 2589283611 40;
BA_ "GenMsgILSupport" BO_ 2589283611 1;
BA_ "GenMsgSendType" BO_ 2589283611 0;
BA_ "VFrameFormat" BO_ 2589283611 15;
BA_ "MsgType" BO_ 2591965952 6;
BA_ "VFrameFormat" BO_ 2591965952 15;
BA_ "MsgType" BO_ 2591965953 6;
BA_ "VFrameFormat" BO_ 2591965953 15;
BA_ "GenMsgCycleTime" BO_ 2589283768 1000;
BA_ "GenMsgILSupport" BO_ 2589283768 1;
BA_ "GenMsgSendType" BO_ 2589283768 0;
BA_ "VFrameFormat" BO_ 2589283768 15;
BA_ "GenMsgCycleTime" BO_ 1140 1000;
BA_ "GenMsgDelayTime" BO_ 1140 40;
BA_ "GenMsgILSupport" BO_ 1140 1;
BA_ "GenMsgSendType" BO_ 1140 0;
BA_ "VFrameFormat" BO_ 1140 14;
BA_ "GenMsgCycleTime" BO_ 2589283965 500;
BA_ "GenMsgDelayTime" BO_ 2589283965 100;
BA_ "GenMsgILSupport" BO_ 2589283965 1;
BA_ "GenMsgSendType" BO_ 2589283965 0;
BA_ "VFrameFormat" BO_ 2589283965 15;
BA_ "GenMsgCycleTime" BO_ 1411 200;
BA_ "GenMsgCycleTimeFast" BO_ 1411 50;
BA_ "GenMsgDelayTime" BO_ 1411 20;
BA_ "GenMsgILSupport" BO_ 1411 1;
BA_ "GenMsgNrOfRepetition" BO_ 1411 3;
BA_ "GenMsgSendType" BO_ 1411 0;
BA_ "VFrameFormat" BO_ 1411 14;
BA_ "GenMsgCycleTime" BO_ 708 500;
BA_ "GenMsgCycleTimeFast" BO_ 708 20;
BA_ "GenMsgDelayTime" BO_ 708 10;
BA_ "GenMsgILSupport" BO_ 708 1;
BA_ "GenMsgNrOfRepetition" BO_ 708 5;
BA_ "GenMsgPDUConstants" BO_ 708 "0x27,0x23,0xf6,0x9b,0x88,0x5f,0x4d,0xcd,0xe1,0x34,0xaa,0x81,0x11,0xc6,0x21,0x0a";
BA_ "GenMsgSendType" BO_ 708 0;
BA_ "VFrameFormat" BO_ 708 14;
BA_ "GenSigSendType" SG_ 975 ASW_Warnung_aktiv_HBFS 3;
BA_ "GenSigSwitchedByIgnition" SG_ 975 ASW_Warnung_aktiv_HBFS 0;
BA_ "GenSigSendType" SG_ 975 HBFS_FH_Bew_hoch 3;
BA_ "GenSigSwitchedByIgnition" SG_ 975 HBFS_FH_Bew_hoch 0;
BA_ "GenSigSendType" SG_ 975 HBFS_FH_Bew_tief 3;
BA_ "GenSigSwitchedByIgnition" SG_ 975 HBFS_FH_Bew_tief 0;
BA_ "GenSigSendType" SG_ 975 HBFS_FH_Block 3;
BA_ "GenSigSwitchedByIgnition" SG_ 975 HBFS_FH_Block 0;
BA_ "GenSigSendType" SG_ 975 HBFS_FH_Fang 3;
BA_ "GenSigSwitchedByIgnition" SG_ 975 HBFS_FH_Fang 0;
BA_ "GenSigSendType" SG_ 975 HBFS_FH_normiert 3;
BA_ "GenSigSwitchedByIgnition" SG_ 975 HBFS_FH_normiert 0;
BA_ "GenSigSendType" SG_ 975 HBFS_FH_Oeffnung 3;
BA_ "GenSigSwitchedByIgnition" SG_ 975 HBFS_FH_Oeffnung 0;
BA_ "GenSigSendType" SG_ 975 HBFS_FH_S_AutoHoch 3;
BA_ "GenSigSwitchedByIgnition" SG_ 975 HBFS_FH_S_AutoHoch 0;
BA_ "GenSigSendType" SG_ 975 HBFS_FH_S_AutoTief 3;
BA_ "GenSigSwitchedByIgnition" SG_ 975 HBFS_FH_S_AutoTief 0;
BA_ "GenSigSendType" SG_ 975 HBFS_FH_S_HFS_AutoHoch 3;
BA_ "GenSigSwitchedByIgnition" SG_ 975 HBFS_FH_S_HFS_AutoHoch 0;
BA_ "GenSigSendType" SG_ 975 HBFS_FH_S_HFS_AutoTief 3;
BA_ "GenSigSwitchedByIgnition" SG_ 975 HBFS_FH_S_HFS_AutoTief 0;
BA_ "GenSigSendType" SG_ 975 HBFS_FH_S_HFS_ManHoch 3;
BA_ "GenSigSwitchedByIgnition" SG_ 975 HBFS_FH_S_HFS_ManHoch 0;
BA_ "GenSigSendType" SG_ 975 HBFS_FH_S_HFS_ManTief 3;
BA_ "GenSigSwitchedByIgnition" SG_ 975 HBFS_FH_S_HFS_ManTief 0;
BA_ "GenSigSendType" SG_ 975 HBFS_FH_S_ManHoch 3;
BA_ "GenSigSwitchedByIgnition" SG_ 975 HBFS_FH_S_ManHoch 0;
BA_ "GenSigSendType" SG_ 975 HBFS_FH_S_ManTief 3;
BA_ "GenSigSwitchedByIgnition" SG_ 975 HBFS_FH_S_ManTief 0;
BA_ "GenSigSendType" SG_ 975 HBFS_FH_Thermo 3;
BA_ "GenSigSwitchedByIgnition" SG_ 975 HBFS_FH_Thermo 0;
BA_ "GenSigSendType" SG_ 975 HBFS_gesafet 3;
BA_ "GenSigSwitchedByIgnition" SG_ 975 HBFS_gesafet 0;
BA_ "GenSigSendType" SG_ 975 HBFS_Heckrollotaster_betaetigt 3;
BA_ "GenSigSwitchedByIgnition" SG_ 975 HBFS_Heckrollotaster_betaetigt 0;
BA_ "GenSigSendType" SG_ 975 HBFS_Lock_Taster 3;
BA_ "GenSigSwitchedByIgnition" SG_ 975 HBFS_Lock_Taster 0;
BA_ "GenSigSendType" SG_ 975 HBFS_Lock_Taster_inv 3;
BA_ "GenSigSwitchedByIgnition" SG_ 975 HBFS_Lock_Taster_inv 0;
BA_ "Fehlerwert" SG_ 975 HBFS_MRollo_Schalter 7;
BA_ "GenSigSendType" SG_ 975 HBFS_MRollo_Schalter 3;
BA_ "GenSigStartValue" SG_ 975 HBFS_MRollo_Schalter 6;
BA_ "GenSigSwitchedByIgnition" SG_ 975 HBFS_MRollo_Schalter 0;
BA_ "GenSigSendType" SG_ 975 HBFS_Oben_Block_erw 3;
BA_ "GenSigSwitchedByIgnition" SG_ 975 HBFS_Oben_Block_erw 0;
BA_ "Fehlerwert" SG_ 975 HBFS_SAD_Schalter 15;
BA_ "GenSigSendType" SG_ 975 HBFS_SAD_Schalter 3;
BA_ "GenSigStartValue" SG_ 975 HBFS_SAD_Schalter 14;
BA_ "GenSigSwitchedByIgnition" SG_ 975 HBFS_SAD_Schalter 0;
BA_ "GenSigSendType" SG_ 975 HBFS_Seitenrollo_hoch 3;
BA_ "GenSigSwitchedByIgnition" SG_ 975 HBFS_Seitenrollo_hoch 0;
BA_ "GenSigSendType" SG_ 975 HBFS_Seitenrollo_tief 3;
BA_ "GenSigSwitchedByIgnition" SG_ 975 HBFS_Seitenrollo_tief 0;
BA_ "GenSigSendType" SG_ 975 HBFS_SK_betaetigt 3;
BA_ "GenSigSwitchedByIgnition" SG_ 975 HBFS_SK_betaetigt 0;
BA_ "GenSigSendType" SG_ 975 HBFS_Sperrklinke 3;
BA_ "GenSigSwitchedByIgnition" SG_ 975 HBFS_Sperrklinke 0;
BA_ "Fehlerwert" SG_ 975 HBFS_Status_eTAG 3;
BA_ "GenSigSendType" SG_ 975 HBFS_Status_eTAG 3;
BA_ "GenSigSwitchedByIgnition" SG_ 975 HBFS_Status_eTAG 0;
BA_ "GenSigSendType" SG_ 975 HBFS_Status_KiSi 3;
BA_ "GenSigSwitchedByIgnition" SG_ 975 HBFS_Status_KiSi 0;
BA_ "GenSigSendType" SG_ 975 HBFS_Status_KiSi_inv 3;
BA_ "GenSigStartValue" SG_ 975 HBFS_Status_KiSi_inv 1;
BA_ "GenSigSwitchedByIgnition" SG_ 975 HBFS_Status_KiSi_inv 0;
BA_ "GenSigSendType" SG_ 975 HBFS_TAG_betaetigt 3;
BA_ "GenSigSwitchedByIgnition" SG_ 975 HBFS_TAG_betaetigt 0;
BA_ "GenSigSendType" SG_ 975 HBFS_TIG_betaetigt 3;
BA_ "GenSigSwitchedByIgnition" SG_ 975 HBFS_TIG_betaetigt 0;
BA_ "GenSigSendType" SG_ 975 HBFS_TIG_betaetigt_oeffnen 3;
BA_ "GenSigSwitchedByIgnition" SG_ 975 HBFS_TIG_betaetigt_oeffnen 0;
BA_ "GenSigSendType" SG_ 975 HBFS_TIG_betaetigt_schliessen 3;
BA_ "GenSigSwitchedByIgnition" SG_ 975 HBFS_TIG_betaetigt_schliessen 0;
BA_ "GenSigSendType" SG_ 975 HBFS_Tuer_geoeffnet 3;
BA_ "GenSigSwitchedByIgnition" SG_ 975 HBFS_Tuer_geoeffnet 0;
BA_ "Fehlerwert" SG_ 975 HBFS_Tuer_Status 3;
BA_ "GenSigSendType" SG_ 975 HBFS_Tuer_Status 3;
BA_ "GenSigSwitchedByIgnition" SG_ 975 HBFS_Tuer_Status 0;
BA_ "GenSigSendType" SG_ 975 HBFS_Tuer_Status_QBit 3;
BA_ "GenSigSwitchedByIgnition" SG_ 975 HBFS_Tuer_Status_QBit 0;
BA_ "GenSigSendType" SG_ 975 HBFS_Tueroeffnen_Warnung 3;
BA_ "GenSigSwitchedByIgnition" SG_ 975 HBFS_Tueroeffnen_Warnung 0;
BA_ "GenSigSendType" SG_ 975 HBFS_Tuerschloss_defekt 0;
BA_ "GenSigSwitchedByIgnition" SG_ 975 HBFS_Tuerschloss_defekt 0;
BA_ "GenSigSendType" SG_ 975 HBFS_UEKB_aktiviert 3;
BA_ "GenSigSwitchedByIgnition" SG_ 975 HBFS_UEKB_aktiviert 0;
BA_ "GenSigSendType" SG_ 975 HBFS_Unlock_Taster 3;
BA_ "GenSigSwitchedByIgnition" SG_ 975 HBFS_Unlock_Taster 0;
BA_ "GenSigSendType" SG_ 975 HBFS_Unten_Block_erw 3;
BA_ "GenSigSwitchedByIgnition" SG_ 975 HBFS_Unten_Block_erw 0;
BA_ "GenSigSendType" SG_ 975 HBFS_verriegelt 3;
BA_ "GenSigSwitchedByIgnition" SG_ 975 HBFS_verriegelt 0;
BA_ "GenSigSendType" SG_ 975 HBFS_Vorraste_betaetigt 3;
BA_ "GenSigSwitchedByIgnition" SG_ 975 HBFS_Vorraste_betaetigt 0;
BA_ "GenSigSendType" SG_ 975 HBFS_Zuziehhilfe_aktiv 3;
BA_ "GenSigSwitchedByIgnition" SG_ 975 HBFS_Zuziehhilfe_aktiv 0;
BA_ "GenSigSendType" SG_ 975 MTHBFS_M_Taste 3;
BA_ "GenSigSwitchedByIgnition" SG_ 975 MTHBFS_M_Taste 0;
BA_ "GenSigSendType" SG_ 975 MTHBFS_Pos1 3;
BA_ "GenSigSwitchedByIgnition" SG_ 975 MTHBFS_Pos1 0;
BA_ "GenSigSendType" SG_ 975 MTHBFS_Pos2 3;
BA_ "GenSigSwitchedByIgnition" SG_ 975 MTHBFS_Pos2 0;
BA_ "GenSigSendType" SG_ 975 MTHBFS_Pos3 3;
BA_ "GenSigSwitchedByIgnition" SG_ 975 MTHBFS_Pos3 0;
BA_ "GenSigSendType" SG_ 975 SSR_HBFS_Pos_Unten 0;
BA_ "GenSigSwitchedByIgnition" SG_ 975 SSR_HBFS_Pos_Unten 0;
BA_ "GenSigSendType" SG_ 974 ASW_Warnung_aktiv_HFS 3;
BA_ "GenSigSwitchedByIgnition" SG_ 974 ASW_Warnung_aktiv_HFS 0;
BA_ "GenSigSendType" SG_ 974 HFS_FH_Bew_hoch 3;
BA_ "GenSigSwitchedByIgnition" SG_ 974 HFS_FH_Bew_hoch 0;
BA_ "GenSigSendType" SG_ 974 HFS_FH_Bew_tief 3;
BA_ "GenSigSwitchedByIgnition" SG_ 974 HFS_FH_Bew_tief 0;
BA_ "GenSigSendType" SG_ 974 HFS_FH_Block 3;
BA_ "GenSigSwitchedByIgnition" SG_ 974 HFS_FH_Block 0;
BA_ "GenSigSendType" SG_ 974 HFS_FH_Fang 3;
BA_ "GenSigSwitchedByIgnition" SG_ 974 HFS_FH_Fang 0;
BA_ "GenSigSendType" SG_ 974 HFS_FH_normiert 3;
BA_ "GenSigSwitchedByIgnition" SG_ 974 HFS_FH_normiert 0;
BA_ "GenSigSendType" SG_ 974 HFS_FH_Oeffnung 3;
BA_ "GenSigSwitchedByIgnition" SG_ 974 HFS_FH_Oeffnung 0;
BA_ "GenSigSendType" SG_ 974 HFS_FH_S_AutoHoch 3;
BA_ "GenSigSwitchedByIgnition" SG_ 974 HFS_FH_S_AutoHoch 0;
BA_ "GenSigSendType" SG_ 974 HFS_FH_S_AutoTief 3;
BA_ "GenSigSwitchedByIgnition" SG_ 974 HFS_FH_S_AutoTief 0;
BA_ "GenSigSendType" SG_ 974 HFS_FH_S_HBFS_AutoHoch 3;
BA_ "GenSigSwitchedByIgnition" SG_ 974 HFS_FH_S_HBFS_AutoHoch 0;
BA_ "GenSigSendType" SG_ 974 HFS_FH_S_HBFS_AutoTief 3;
BA_ "GenSigSwitchedByIgnition" SG_ 974 HFS_FH_S_HBFS_AutoTief 0;
BA_ "GenSigSendType" SG_ 974 HFS_FH_S_HBFS_ManHoch 3;
BA_ "GenSigSwitchedByIgnition" SG_ 974 HFS_FH_S_HBFS_ManHoch 0;
BA_ "GenSigSendType" SG_ 974 HFS_FH_S_HBFS_ManTief 3;
BA_ "GenSigSwitchedByIgnition" SG_ 974 HFS_FH_S_HBFS_ManTief 0;
BA_ "GenSigSendType" SG_ 974 HFS_FH_S_ManHoch 3;
BA_ "GenSigSwitchedByIgnition" SG_ 974 HFS_FH_S_ManHoch 0;
BA_ "GenSigSendType" SG_ 974 HFS_FH_S_ManTief 3;
BA_ "GenSigSwitchedByIgnition" SG_ 974 HFS_FH_S_ManTief 0;
BA_ "GenSigSendType" SG_ 974 HFS_FH_Thermo 3;
BA_ "GenSigSwitchedByIgnition" SG_ 974 HFS_FH_Thermo 0;
BA_ "GenSigSendType" SG_ 974 HFS_gesafet 3;
BA_ "GenSigSwitchedByIgnition" SG_ 974 HFS_gesafet 0;
BA_ "GenSigSendType" SG_ 974 HFS_Heckrollotaster_betaetigt 3;
BA_ "GenSigSwitchedByIgnition" SG_ 974 HFS_Heckrollotaster_betaetigt 0;
BA_ "GenSigSendType" SG_ 974 HFS_Lock_Taster 3;
BA_ "GenSigSwitchedByIgnition" SG_ 974 HFS_Lock_Taster 0;
BA_ "GenSigSendType" SG_ 974 HFS_Lock_Taster_inv 3;
BA_ "GenSigSwitchedByIgnition" SG_ 974 HFS_Lock_Taster_inv 0;
BA_ "Fehlerwert" SG_ 974 HFS_MRollo_Schalter 7;
BA_ "GenSigSendType" SG_ 974 HFS_MRollo_Schalter 3;
BA_ "GenSigStartValue" SG_ 974 HFS_MRollo_Schalter 6;
BA_ "GenSigSwitchedByIgnition" SG_ 974 HFS_MRollo_Schalter 0;
BA_ "GenSigSendType" SG_ 974 HFS_Oben_Block_erw 3;
BA_ "GenSigSwitchedByIgnition" SG_ 974 HFS_Oben_Block_erw 0;
BA_ "Fehlerwert" SG_ 974 HFS_SAD_Schalter 15;
BA_ "GenSigSendType" SG_ 974 HFS_SAD_Schalter 3;
BA_ "GenSigStartValue" SG_ 974 HFS_SAD_Schalter 14;
BA_ "GenSigSwitchedByIgnition" SG_ 974 HFS_SAD_Schalter 0;
BA_ "GenSigSendType" SG_ 974 HFS_Seitenrollo_hoch 3;
BA_ "GenSigSwitchedByIgnition" SG_ 974 HFS_Seitenrollo_hoch 0;
BA_ "GenSigSendType" SG_ 974 HFS_Seitenrollo_tief 3;
BA_ "GenSigSwitchedByIgnition" SG_ 974 HFS_Seitenrollo_tief 0;
BA_ "GenSigSendType" SG_ 974 HFS_SK_betaetigt 3;
BA_ "GenSigSwitchedByIgnition" SG_ 974 HFS_SK_betaetigt 0;
BA_ "GenSigSendType" SG_ 974 HFS_Sperrklinke 3;
BA_ "GenSigSwitchedByIgnition" SG_ 974 HFS_Sperrklinke 0;
BA_ "Fehlerwert" SG_ 974 HFS_Status_eTAG 3;
BA_ "GenSigSendType" SG_ 974 HFS_Status_eTAG 3;
BA_ "GenSigSwitchedByIgnition" SG_ 974 HFS_Status_eTAG 0;
BA_ "GenSigSendType" SG_ 974 HFS_Status_KiSi 3;
BA_ "GenSigSwitchedByIgnition" SG_ 974 HFS_Status_KiSi 0;
BA_ "GenSigSendType" SG_ 974 HFS_TAG_betaetigt 3;
BA_ "GenSigSwitchedByIgnition" SG_ 974 HFS_TAG_betaetigt 0;
BA_ "GenSigSendType" SG_ 974 HFS_TCR_Mode_aktiv 3;
BA_ "GenSigSwitchedByIgnition" SG_ 974 HFS_TCR_Mode_aktiv 0;
BA_ "GenSigSendType" SG_ 974 HFS_TIG_betaetigt 3;
BA_ "GenSigSwitchedByIgnition" SG_ 974 HFS_TIG_betaetigt 0;
BA_ "GenSigSendType" SG_ 974 HFS_TIG_betaetigt_oeffnen 3;
BA_ "GenSigSwitchedByIgnition" SG_ 974 HFS_TIG_betaetigt_oeffnen 0;
BA_ "GenSigSendType" SG_ 974 HFS_TIG_betaetigt_schliessen 3;
BA_ "GenSigSwitchedByIgnition" SG_ 974 HFS_TIG_betaetigt_schliessen 0;
BA_ "GenSigSendType" SG_ 974 HFS_Tuer_geoeffnet 3;
BA_ "GenSigSwitchedByIgnition" SG_ 974 HFS_Tuer_geoeffnet 0;
BA_ "Fehlerwert" SG_ 974 HFS_Tuer_Status 3;
BA_ "GenSigSendType" SG_ 974 HFS_Tuer_Status 3;
BA_ "GenSigSwitchedByIgnition" SG_ 974 HFS_Tuer_Status 0;
BA_ "GenSigSendType" SG_ 974 HFS_Tuer_Status_QBit 0;
BA_ "GenSigSwitchedByIgnition" SG_ 974 HFS_Tuer_Status_QBit 0;
BA_ "GenSigSendType" SG_ 974 HFS_Tueroeffnen_Warnung 3;
BA_ "GenSigSwitchedByIgnition" SG_ 974 HFS_Tueroeffnen_Warnung 0;
BA_ "GenSigSendType" SG_ 974 HFS_Tuerschloss_defekt 0;
BA_ "GenSigSwitchedByIgnition" SG_ 974 HFS_Tuerschloss_defekt 0;
BA_ "GenSigSendType" SG_ 974 HFS_UEKB_aktiviert 3;
BA_ "GenSigSwitchedByIgnition" SG_ 974 HFS_UEKB_aktiviert 0;
BA_ "GenSigSendType" SG_ 974 HFS_Unlock_Taster 3;
BA_ "GenSigSwitchedByIgnition" SG_ 974 HFS_Unlock_Taster 0;
BA_ "GenSigSendType" SG_ 974 HFS_Unten_Block_erw 3;
BA_ "GenSigSwitchedByIgnition" SG_ 974 HFS_Unten_Block_erw 0;
BA_ "GenSigSendType" SG_ 974 HFS_verriegelt 3;
BA_ "GenSigSwitchedByIgnition" SG_ 974 HFS_verriegelt 0;
BA_ "GenSigSendType" SG_ 974 HFS_Vorraste_betaetigt 3;
BA_ "GenSigSwitchedByIgnition" SG_ 974 HFS_Vorraste_betaetigt 0;
BA_ "GenSigSendType" SG_ 974 HFS_Zuziehhilfe_aktiv 3;
BA_ "GenSigSwitchedByIgnition" SG_ 974 HFS_Zuziehhilfe_aktiv 0;
BA_ "GenSigSendType" SG_ 974 MTHFS_M_Taste 3;
BA_ "GenSigSwitchedByIgnition" SG_ 974 MTHFS_M_Taste 0;
BA_ "GenSigSendType" SG_ 974 MTHFS_Pos1 3;
BA_ "GenSigSwitchedByIgnition" SG_ 974 MTHFS_Pos1 0;
BA_ "GenSigSendType" SG_ 974 MTHFS_Pos2 3;
BA_ "GenSigSwitchedByIgnition" SG_ 974 MTHFS_Pos2 0;
BA_ "GenSigSendType" SG_ 974 MTHFS_Pos3 3;
BA_ "GenSigSwitchedByIgnition" SG_ 974 MTHFS_Pos3 0;
BA_ "GenSigSendType" SG_ 974 SSR_HFS_Pos_Unten 0;
BA_ "GenSigSwitchedByIgnition" SG_ 974 SSR_HFS_Pos_Unten 0;
BA_ "Fehlerwert" SG_ 2463978710 OPS_ComfortReadyStatus 3;
BA_ "GenSigSendType" SG_ 2463978710 OPS_ComfortReadyStatus 4;
BA_ "GenSigSwitchedByIgnition" SG_ 2463978710 OPS_ComfortReadyStatus 0;
BA_ "Fehlerwert" SG_ 2463978710 OPS_DriverPresenceStatus 15;
BA_ "GenSigSendType" SG_ 2463978710 OPS_DriverPresenceStatus 4;
BA_ "GenSigSwitchedByIgnition" SG_ 2463978710 OPS_DriverPresenceStatus 0;
BA_ "Fehlerwert" SG_ 2463978710 OPS_OccupantPresenceStatus 7;
BA_ "GenSigSendType" SG_ 2463978710 OPS_OccupantPresenceStatus 4;
BA_ "GenSigSwitchedByIgnition" SG_ 2463978710 OPS_OccupantPresenceStatus 0;
BA_ "GenSigSendType" SG_ 2463978710 OPS_QBit_DriverPresence 4;
BA_ "GenSigStartValue" SG_ 2463978710 OPS_QBit_DriverPresence 1;
BA_ "GenSigSwitchedByIgnition" SG_ 2463978710 OPS_QBit_DriverPresence 0;
BA_ "GenSigSendType" SG_ 2463978710 OPS_SafeDriverPresence_available 4;
BA_ "GenSigSwitchedByIgnition" SG_ 2463978710 OPS_SafeDriverPresence_available 0;
BA_ "Fehlerwert" SG_ 2463978710 OPS_SafeDriverPresenceStatus 3;
BA_ "GenSigSendType" SG_ 2463978710 OPS_SafeDriverPresenceStatus 4;
BA_ "GenSigFuncType" SG_ 2463978710 UserStateServer_01_BZ 1;
BA_ "GenSigSendType" SG_ 2463978710 UserStateServer_01_BZ 0;
BA_ "GenSigSwitchedByIgnition" SG_ 2463978710 UserStateServer_01_BZ 0;
BA_ "GenSigFuncType" SG_ 2463978710 UserStateServer_01_CRC 2;
BA_ "GenSigSendType" SG_ 2463978710 UserStateServer_01_CRC 0;
BA_ "GenSigSwitchedByIgnition" SG_ 2463978710 UserStateServer_01_CRC 0;
BA_ "GenSigSwitchedByIgnition" SG_ 1716 KS_Geheimnis_1 0;
BA_ "GenSigSwitchedByIgnition" SG_ 1716 KS_Geheimnis_2 0;
BA_ "GenSigSwitchedByIgnition" SG_ 1716 KS_Geheimnis_3 0;
BA_ "GenSigSwitchedByIgnition" SG_ 1716 KS_Geheimnis_4 0;
BA_ "GenSigSendType" SG_ 1716 VIN_01_MUX 0;
BA_ "GenSigSwitchedByIgnition" SG_ 1716 VIN_01_MUX 0;
BA_ "GenSigStartValue" SG_ 1716 VIN_1 45;
BA_ "GenSigSwitchedByIgnition" SG_ 1716 VIN_1 0;
BA_ "GenSigStartValue" SG_ 1716 VIN_10 45;
BA_ "GenSigSwitchedByIgnition" SG_ 1716 VIN_10 0;
BA_ "GenSigStartValue" SG_ 1716 VIN_11 45;
BA_ "GenSigSwitchedByIgnition" SG_ 1716 VIN_11 0;
BA_ "GenSigStartValue" SG_ 1716 VIN_12 45;
BA_ "GenSigSwitchedByIgnition" SG_ 1716 VIN_12 0;
BA_ "GenSigStartValue" SG_ 1716 VIN_13 45;
BA_ "GenSigSwitchedByIgnition" SG_ 1716 VIN_13 0;
BA_ "GenSigStartValue" SG_ 1716 VIN_14 45;
BA_ "GenSigSwitchedByIgnition" SG_ 1716 VIN_14 0;
BA_ "GenSigStartValue" SG_ 1716 VIN_15 45;
BA_ "GenSigSwitchedByIgnition" SG_ 1716 VIN_15 0;
BA_ "GenSigStartValue" SG_ 1716 VIN_16 45;
BA_ "GenSigSwitchedByIgnition" SG_ 1716 VIN_16 0;
BA_ "GenSigStartValue" SG_ 1716 VIN_17 45;
BA_ "GenSigSwitchedByIgnition" SG_ 1716 VIN_17 0;
BA_ "GenSigStartValue" SG_ 1716 VIN_2 45;
BA_ "GenSigSwitchedByIgnition" SG_ 1716 VIN_2 0;
BA_ "GenSigStartValue" SG_ 1716 VIN_3 45;
BA_ "GenSigSwitchedByIgnition" SG_ 1716 VIN_3 0;
BA_ "GenSigStartValue" SG_ 1716 VIN_4 45;
BA_ "GenSigSwitchedByIgnition" SG_ 1716 VIN_4 0;
BA_ "GenSigStartValue" SG_ 1716 VIN_5 45;
BA_ "GenSigSwitchedByIgnition" SG_ 1716 VIN_5 0;
BA_ "GenSigStartValue" SG_ 1716 VIN_6 45;
BA_ "GenSigSwitchedByIgnition" SG_ 1716 VIN_6 0;
BA_ "GenSigStartValue" SG_ 1716 VIN_7 45;
BA_ "GenSigSwitchedByIgnition" SG_ 1716 VIN_7 0;
BA_ "GenSigStartValue" SG_ 1716 VIN_8 45;
BA_ "GenSigSwitchedByIgnition" SG_ 1716 VIN_8 0;
BA_ "GenSigStartValue" SG_ 1716 VIN_9 45;
BA_ "GenSigSwitchedByIgnition" SG_ 1716 VIN_9 0;
BA_ "GenSigFuncType" SG_ 1057 VLK_01_BZ 1;
BA_ "GenSigSendType" SG_ 1057 VLK_01_BZ 0;
BA_ "GenSigSwitchedByIgnition" SG_ 1057 VLK_01_BZ 0;
BA_ "GenSigFuncType" SG_ 1057 VLK_01_CRC 2;
BA_ "GenSigSendType" SG_ 1057 VLK_01_CRC 0;
BA_ "GenSigSwitchedByIgnition" SG_ 1057 VLK_01_CRC 0;
BA_ "Fehlerwert" SG_ 1057 VLK_Anf_Antrieb 7;
BA_ "GenSigSendType" SG_ 1057 VLK_Anf_Antrieb 3;
BA_ "GenSigSwitchedByIgnition" SG_ 1057 VLK_Anf_Antrieb 0;
BA_ "GenSigSendType" SG_ 1057 VLK_Anforderung_HMS 3;
BA_ "GenSigSwitchedByIgnition" SG_ 1057 VLK_Anforderung_HMS 0;
BA_ "GenSigSendType" SG_ 1057 VLK_Anforderung_Rollfaehigkeit 0;
BA_ "GenSigSwitchedByIgnition" SG_ 1057 VLK_Anforderung_Rollfaehigkeit 0;
BA_ "Fehlerwert" SG_ 1057 VLK_Antriebsdeaktivierung 3;
BA_ "GenSigSendType" SG_ 1057 VLK_Antriebsdeaktivierung 3;
BA_ "GenSigSwitchedByIgnition" SG_ 1057 VLK_Antriebsdeaktivierung 0;
BA_ "GenSigSendType" SG_ 1057 VLK_autom_Absch_Signalisierung 0;
BA_ "GenSigSwitchedByIgnition" SG_ 1057 VLK_autom_Absch_Signalisierung 0;
BA_ "GenSigSendType" SG_ 1057 VLK_Hinweis_Rollfaehigkeit 3;
BA_ "GenSigSwitchedByIgnition" SG_ 1057 VLK_Hinweis_Rollfaehigkeit 0;
BA_ "Fehlerwert" SG_ 1057 VLK_Parken_beibehalten_HMS 3;
BA_ "GenSigSendType" SG_ 1057 VLK_Parken_beibehalten_HMS 3;
BA_ "GenSigStartValue" SG_ 1057 VLK_Parken_beibehalten_HMS 2;
BA_ "GenSigSwitchedByIgnition" SG_ 1057 VLK_Parken_beibehalten_HMS 0;
BA_ "GenSigSendType" SG_ 1057 VLK_VLW_Anf 3;
BA_ "GenSigSwitchedByIgnition" SG_ 1057 VLK_VLW_Anf 0;
BA_ "GenSigSendType" SG_ 2463978663 VZE_Akustik_Limitwechsel 0;
BA_ "GenSigSendType" SG_ 2463978663 VZE_Akustik_Limitwechsel_Status 0;
BA_ "Fehlerwert" SG_ 2463978663 VZE_Anhaenger_Vmax 15;
BA_ "GenSigSendType" SG_ 2463978663 VZE_Anhaenger_Vmax 3;
BA_ "GenSigStartValue" SG_ 2463978663 VZE_Anhaenger_Vmax 14;
BA_ "GenSigSendType" SG_ 2463978663 VZE_Anzeige_VZ_1 0;
BA_ "GenSigSwitchedByIgnition" SG_ 2463978663 VZE_Anzeige_VZ_1 0;
BA_ "GenSigSendType" SG_ 2463978663 VZE_Anzeige_VZ_2 0;
BA_ "GenSigSwitchedByIgnition" SG_ 2463978663 VZE_Anzeige_VZ_2 0;
BA_ "GenSigSendType" SG_ 2463978663 VZE_Anzeige_VZ_3 0;
BA_ "GenSigSwitchedByIgnition" SG_ 2463978663 VZE_Anzeige_VZ_3 0;
BA_ "GenSigSendType" SG_ 2463978663 VZE_Anzeige_ZS_1 0;
BA_ "GenSigSwitchedByIgnition" SG_ 2463978663 VZE_Anzeige_ZS_1 0;
BA_ "GenSigSendType" SG_ 2463978663 VZE_Anzeige_ZS_2 0;
BA_ "GenSigSwitchedByIgnition" SG_ 2463978663 VZE_Anzeige_ZS_2 0;
BA_ "GenSigSendType" SG_ 2463978663 VZE_Anzeige_ZS_3 0;
BA_ "GenSigSwitchedByIgnition" SG_ 2463978663 VZE_Anzeige_ZS_3 0;
BA_ "GenSigSendType" SG_ 2463978663 VZE_Anzeigemodus 3;
BA_ "GenSigSendType" SG_ 2463978663 VZE_Anzeigeunterdrueck_Zeichen_1 3;
BA_ "GenSigSendType" SG_ 2463978663 VZE_Anzeigeunterdrueck_Zeichen_2 3;
BA_ "GenSigSendType" SG_ 2463978663 VZE_Anzeigeunterdrueck_Zeichen_3 3;
BA_ "GenSigSendType" SG_ 2463978663 VZE_Anzeigeunterdrueck_Zeichen_4 3;
BA_ "GenSigSendType" SG_ 2463978663 VZE_Anzeigeunterdrueck_Zeichen_5 3;
BA_ "GenSigSendType" SG_ 2463978663 VZE_Baustelle 3;
BA_ "GenSigSendType" SG_ 2463978663 VZE_Erweiterte_Information 0;
BA_ "GenSigSendType" SG_ 2463978663 VZE_FoD_Status 0;
BA_ "GenSigSwitchedByIgnition" SG_ 2463978663 VZE_FoD_Status 0;
BA_ "GenSigSendType" SG_ 2463978663 VZE_Gong 3;
BA_ "GenSigSendType" SG_ 2463978663 VZE_Hinweistext 3;
BA_ "GenSigSendType" SG_ 2463978663 VZE_Hinweistext_03 0;
BA_ "GenSigSwitchedByIgnition" SG_ 2463978663 VZE_Hinweistext_03 0;
BA_ "GenSigSendType" SG_ 2463978663 VZE_Land 0;
BA_ "GenSigSwitchedByIgnition" SG_ 2463978663 VZE_Land 0;
BA_ "GenSigSendType" SG_ 2463978663 VZE_Modus_OptischeWarnung 0;
BA_ "GenSigSendType" SG_ 2463978663 VZE_SLWF_Status 0;
BA_ "GenSigSwitchedByIgnition" SG_ 2463978663 VZE_SLWF_Status 0;
BA_ "GenSigSendType" SG_ 2463978663 VZE_Tempowarnung_Einheit 0;
BA_ "GenSigSendType" SG_ 2463978663 VZE_Tempowarnung_Offset 0;
BA_ "GenSigSendType" SG_ 2463978663 VZE_Tempowarnung_Status 0;
BA_ "GenSigSwitchedByIgnition" SG_ 2463978663 VZE_Tempowarnung_Status 0;
BA_ "GenSigSendType" SG_ 2463978663 VZE_Umweltinfo_Anhaengerbetrieb 0;
BA_ "GenSigSendType" SG_ 2463978663 VZE_Umweltinfo_Naesse 0;
BA_ "GenSigSendType" SG_ 2463978663 VZE_Umweltinfo_Nebel 0;
BA_ "GenSigSendType" SG_ 2463978663 VZE_Verkehrszeichen_1 3;
BA_ "GenSigSendType" SG_ 2463978663 VZE_Verkehrszeichen_2 3;
BA_ "GenSigSendType" SG_ 2463978663 VZE_Verkehrszeichen_3 3;
BA_ "GenSigSendType" SG_ 2463978663 VZE_Verkehrszeichen_4 3;
BA_ "GenSigSendType" SG_ 2463978663 VZE_Verkehrszeichen_5 3;
BA_ "GenSigSendType" SG_ 2463978663 VZE_Verkehrszeichen_6 0;
BA_ "GenSigSendType" SG_ 2463978663 VZE_Verkehrszeichen_Einheit 3;
BA_ "GenSigSwitchedByIgnition" SG_ 2463978663 VZE_Verkehrszeichen_Einheit 0;
BA_ "GenSigSendType" SG_ 2463978663 VZE_Warnung_Verkehrszeichen_1 3;
BA_ "GenSigSendType" SG_ 2463978663 VZE_Warnung_Verkehrszeichen_2 3;
BA_ "GenSigSendType" SG_ 2463978663 VZE_Warnung_Verkehrszeichen_3 3;
BA_ "GenSigSendType" SG_ 2463978663 VZE_Warnung_Verkehrszeichen_4 3;
BA_ "GenSigSendType" SG_ 2463978663 VZE_Warnung_Verkehrszeichen_5 3;
BA_ "GenSigSendType" SG_ 2463978663 VZE_Warnung_VZ_1 0;
BA_ "GenSigSwitchedByIgnition" SG_ 2463978663 VZE_Warnung_VZ_1 0;
BA_ "GenSigSendType" SG_ 2463978663 VZE_Warnung_VZ_2 0;
BA_ "GenSigSwitchedByIgnition" SG_ 2463978663 VZE_Warnung_VZ_2 0;
BA_ "GenSigSendType" SG_ 2463978663 VZE_Warnung_VZ_3 0;
BA_ "GenSigSwitchedByIgnition" SG_ 2463978663 VZE_Warnung_VZ_3 0;
BA_ "GenSigSendType" SG_ 2463978663 VZE_Zeichen_01_Gesetz 3;
BA_ "GenSigSendType" SG_ 2463978663 VZE_Zeichen_01_Kamera 3;
BA_ "GenSigSendType" SG_ 2463978663 VZE_Zeichen_01_KameraWied 3;
BA_ "GenSigSendType" SG_ 2463978663 VZE_Zeichen_01_Karte 3;
BA_ "GenSigSendType" SG_ 2463978663 VZE_Zeichen_02_Gesetz 3;
BA_ "GenSigSendType" SG_ 2463978663 VZE_Zeichen_02_Kamera 3;
BA_ "GenSigSendType" SG_ 2463978663 VZE_Zeichen_02_KameraWied 3;
BA_ "GenSigSendType" SG_ 2463978663 VZE_Zeichen_02_Karte 3;
BA_ "GenSigSendType" SG_ 2463978663 VZE_Zeichen_03_Gesetz 3;
BA_ "GenSigSendType" SG_ 2463978663 VZE_Zeichen_03_Kamera 3;
BA_ "GenSigSendType" SG_ 2463978663 VZE_Zeichen_03_KameraWied 3;
BA_ "GenSigSendType" SG_ 2463978663 VZE_Zeichen_03_Karte 3;
BA_ "GenSigSendType" SG_ 2463978663 VZE_Zeichen_04_Gesetz 3;
BA_ "GenSigSendType" SG_ 2463978663 VZE_Zeichen_04_Kamera 3;
BA_ "GenSigSendType" SG_ 2463978663 VZE_Zeichen_04_KameraWied 3;
BA_ "GenSigSendType" SG_ 2463978663 VZE_Zeichen_04_Karte 3;
BA_ "GenSigSendType" SG_ 2463978663 VZE_Zeichen_05_Entfernung 0;
BA_ "GenSigSendType" SG_ 2463978663 VZE_Zeichen_05_Entfernung_StdA 0;
BA_ "GenSigSendType" SG_ 2463978663 VZE_Zeichen_05_Gesetz 3;
BA_ "GenSigSendType" SG_ 2463978663 VZE_Zeichen_05_Kamera 3;
BA_ "GenSigSendType" SG_ 2463978663 VZE_Zeichen_05_KameraWied 3;
BA_ "GenSigSendType" SG_ 2463978663 VZE_Zeichen_05_Karte 3;
BA_ "GenSigSendType" SG_ 2463978663 VZE_Zeichen_06_Entfernung 0;
BA_ "GenSigSendType" SG_ 2463978663 VZE_Zeichen_06_Entfernung_StdA 0;
BA_ "GenSigSendType" SG_ 2463978663 VZE_Zusatzschild_1 3;
BA_ "GenSigSendType" SG_ 2463978663 VZE_Zusatzschild_2 3;
BA_ "GenSigSendType" SG_ 2463978663 VZE_Zusatzschild_3 3;
BA_ "GenSigSendType" SG_ 2463978663 VZE_Zusatzschild_4 3;
BA_ "GenSigSendType" SG_ 2463978663 VZE_Zusatzschild_5 3;
BA_ "GenSigSendType" SG_ 2463978663 VZE_Zusatzschild_6 0;
BA_ "GenSigSendType" SG_ 916 GE_Sollgang 3;
BA_ "GenSigSwitchedByIgnition" SG_ 916 GE_Sollgang 0;
BA_ "GenSigSendType" SG_ 916 GE_Stoppverbot_Anz_01 0;
BA_ "GenSigSwitchedByIgnition" SG_ 916 GE_Stoppverbot_Anz_01 0;
BA_ "GenSigSendType" SG_ 916 GE_Stoppverbot_Anz_02 0;
BA_ "GenSigSwitchedByIgnition" SG_ 916 GE_Stoppverbot_Anz_02 0;
BA_ "GenSigSendType" SG_ 916 GE_Stoppverbot_Anz_03 0;
BA_ "GenSigSwitchedByIgnition" SG_ 916 GE_Stoppverbot_Anz_03 0;
BA_ "GenSigSendType" SG_ 916 GE_Stoppverbot_Anz_04 0;
BA_ "GenSigSwitchedByIgnition" SG_ 916 GE_Stoppverbot_Anz_04 0;
BA_ "GenSigSendType" SG_ 916 GE_Stoppverbot_Anz_05 0;
BA_ "GenSigSwitchedByIgnition" SG_ 916 GE_Stoppverbot_Anz_05 0;
BA_ "GenSigSendType" SG_ 916 GE_Stoppverbot_Anz_06 0;
BA_ "GenSigSwitchedByIgnition" SG_ 916 GE_Stoppverbot_Anz_06 0;
BA_ "GenSigSendType" SG_ 916 GE_Stoppverbot_Anz_07 0;
BA_ "GenSigSwitchedByIgnition" SG_ 916 GE_Stoppverbot_Anz_07 0;
BA_ "GenSigSendType" SG_ 916 GE_Stoppverbot_Anz_Std 0;
BA_ "GenSigSwitchedByIgnition" SG_ 916 GE_Stoppverbot_Anz_Std 0;
BA_ "GenSigFuncType" SG_ 916 GE_Tipschaltempf_verfuegbar 8;
BA_ "GenSigSendType" SG_ 916 GE_Tipschaltempf_verfuegbar 0;
BA_ "GenSigSwitchedByIgnition" SG_ 916 GE_Tipschaltempf_verfuegbar 0;
BA_ "GenSigSendType" SG_ 916 GE_Wiederstart_Anz_Std 0;
BA_ "GenSigSwitchedByIgnition" SG_ 916 GE_Wiederstart_Anz_Std 0;
BA_ "GenSigFuncType" SG_ 916 WBA_03_BZ 1;
BA_ "GenSigSendType" SG_ 916 WBA_03_BZ 0;
BA_ "GenSigSwitchedByIgnition" SG_ 916 WBA_03_BZ 0;
BA_ "GenSigFuncType" SG_ 916 WBA_03_CRC 2;
BA_ "GenSigSendType" SG_ 916 WBA_03_CRC 0;
BA_ "GenSigSwitchedByIgnition" SG_ 916 WBA_03_CRC 0;
BA_ "GenSigSendType" SG_ 916 WBA_Anforderung_Akustik 3;
BA_ "GenSigSwitchedByIgnition" SG_ 916 WBA_Anforderung_Akustik 0;
BA_ "GenSigSendType" SG_ 916 WBA_Blinken 3;
BA_ "GenSigSwitchedByIgnition" SG_ 916 WBA_Blinken 0;
BA_ "GenSigSendType" SG_ 916 WBA_eing_Gang_02 3;
BA_ "GenSigSwitchedByIgnition" SG_ 916 WBA_eing_Gang_02 0;
BA_ "GenSigSendType" SG_ 916 WBA_Fahrstufe_02 3;
BA_ "GenSigSwitchedByIgnition" SG_ 916 WBA_Fahrstufe_02 0;
BA_ "GenSigSendType" SG_ 916 WBA_GE_Texte 3;
BA_ "GenSigSwitchedByIgnition" SG_ 916 WBA_GE_Texte 0;
BA_ "GenSigSendType" SG_ 916 WBA_GE_Texte_02 0;
BA_ "GenSigSwitchedByIgnition" SG_ 916 WBA_GE_Texte_02 0;
BA_ "GenSigSendType" SG_ 916 WBA_GE_Warnung_02 3;
BA_ "GenSigSwitchedByIgnition" SG_ 916 WBA_GE_Warnung_02 0;
BA_ "GenSigSendType" SG_ 916 WBA_GE_Zusatzwarnungen 3;
BA_ "GenSigSwitchedByIgnition" SG_ 916 WBA_GE_Zusatzwarnungen 0;
BA_ "GenSigSendType" SG_ 916 WBA_Schaltschema_02 3;
BA_ "GenSigSwitchedByIgnition" SG_ 916 WBA_Schaltschema_02 0;
BA_ "GenSigSendType" SG_ 916 WBA_Schaltschema_Fahreraktion 3;
BA_ "GenSigSwitchedByIgnition" SG_ 916 WBA_Schaltschema_Fahreraktion 0;
BA_ "GenSigSendType" SG_ 916 WBA_Schaltschema_FS_inaktiv 3;
BA_ "GenSigSwitchedByIgnition" SG_ 916 WBA_Schaltschema_FS_inaktiv 0;
BA_ "GenSigSendType" SG_ 916 WBA_Schaltschema_FS_vorwaerts 3;
BA_ "GenSigSwitchedByIgnition" SG_ 916 WBA_Schaltschema_FS_vorwaerts 0;
BA_ "GenSigSendType" SG_ 916 WBA_Schaltschema_Tippgasse 3;
BA_ "GenSigSwitchedByIgnition" SG_ 916 WBA_Schaltschema_Tippgasse 0;
BA_ "GenSigSendType" SG_ 916 WBA_Segeln_aktiv 3;
BA_ "GenSigSwitchedByIgnition" SG_ 916 WBA_Segeln_aktiv 0;
BA_ "GenSigSendType" SG_ 916 WBA_Shiftlock_Lampe 3;
BA_ "GenSigSwitchedByIgnition" SG_ 916 WBA_Shiftlock_Lampe 0;
BA_ "GenSigSendType" SG_ 916 WBA_ZielFahrstufe 3;
BA_ "GenSigSwitchedByIgnition" SG_ 916 WBA_ZielFahrstufe 0;
BA_ "GenSigSendType" SG_ 1361 WFS_Betrieb_Lesespule 3;
BA_ "GenSigSwitchedByIgnition" SG_ 1361 WFS_Betrieb_Lesespule 0;
BA_ "GenSigSendType" SG_ 1361 WFS_ELV_authorisiert 3;
BA_ "GenSigSwitchedByIgnition" SG_ 1361 WFS_ELV_authorisiert 0;
BA_ "GenSigSendType" SG_ 1361 WFS_Fahrerhinweise 3;
BA_ "GenSigSwitchedByIgnition" SG_ 1361 WFS_Fahrerhinweise 0;
BA_ "GenSigSendType" SG_ 1361 WFS_ID_Geb_autorisiert 3;
BA_ "GenSigSwitchedByIgnition" SG_ 1361 WFS_ID_Geb_autorisiert 0;
BA_ "GenSigSendType" SG_ 1361 WFS_ID_Geb_autorisiert_in_Kl15 3;
BA_ "GenSigSwitchedByIgnition" SG_ 1361 WFS_ID_Geb_autorisiert_in_Kl15 0;
BA_ "GenSigSendType" SG_ 1361 WFS_ID_Geb_steckt 3;
BA_ "GenSigSwitchedByIgnition" SG_ 1361 WFS_ID_Geb_steckt 0;
BA_ "GenSigSendType" SG_ 1361 WFS_Klemmenfreigabe 3;
BA_ "GenSigSwitchedByIgnition" SG_ 1361 WFS_Klemmenfreigabe 0;
BA_ "GenSigSendType" SG_ 1361 WFS_Klemmenfreigabe_Signatur 3;
BA_ "GenSigSwitchedByIgnition" SG_ 1361 WFS_Klemmenfreigabe_Signatur 0;
BA_ "GenSigSendType" SG_ 1361 WFS_LF_Aktiv 3;
BA_ "GenSigSwitchedByIgnition" SG_ 1361 WFS_LF_Aktiv 0;
BA_ "GenSigSendType" SG_ 1361 WFS_LZ 3;
BA_ "GenSigSwitchedByIgnition" SG_ 1361 WFS_LZ 0;
BA_ "Fehlerwert" SG_ 1361 WFS_LZ_02 9;
BA_ "GenSigSendType" SG_ 1361 WFS_LZ_02 3;
BA_ "GenSigSwitchedByIgnition" SG_ 1361 WFS_LZ_02 0;
BA_ "GenSigSendType" SG_ 1361 WFS_Parken_Status 3;
BA_ "GenSigSwitchedByIgnition" SG_ 1361 WFS_Parken_Status 0;
BA_ "GenSigSendType" SG_ 1361 WFS_Safe 3;
BA_ "GenSigSwitchedByIgnition" SG_ 1361 WFS_Safe 0;
BA_ "GenSigSendType" SG_ 1361 WFS_Schluessel_Fahrberecht 0;
BA_ "GenSigSwitchedByIgnition" SG_ 1361 WFS_Schluessel_Fahrberecht 0;
BA_ "GenSigSendType" SG_ 1361 WFS_Schluessel_Ist 3;
BA_ "GenSigSwitchedByIgnition" SG_ 1361 WFS_Schluessel_Ist 0;
BA_ "GenSigSendType" SG_ 1361 WFS_Schluessel_Soll 3;
BA_ "GenSigSwitchedByIgnition" SG_ 1361 WFS_Schluessel_Soll 0;
BA_ "GenSigSendType" SG_ 1361 WFS_Verbauinfo_ELV 3;
BA_ "GenSigSwitchedByIgnition" SG_ 1361 WFS_Verbauinfo_ELV 0;
BA_ "GenSigFuncType" SG_ 1369 SOK_WFS01_Signatur 15;
BA_ "GenSigSendType" SG_ 1369 SOK_WFS01_Signatur 3;
BA_ "GenSigSwitchedByIgnition" SG_ 1369 SOK_WFS01_Signatur 0;
BA_ "GenSigFuncType" SG_ 34 WFS_Transponder_Req_02_Data 9;
BA_ "GenSigSendType" SG_ 34 WFS_Transponder_Req_02_Data 1;
BA_ "GenSigSwitchedByIgnition" SG_ 34 WFS_Transponder_Req_02_Data 0;
BA_ "GenSigFuncType" SG_ 35 WFS_Transponder_Resp_02_Data 9;
BA_ "GenSigSendType" SG_ 35 WFS_Transponder_Resp_02_Data 3;
BA_ "GenSigSwitchedByIgnition" SG_ 35 WFS_Transponder_Resp_02_Data 0;
BA_ "GenSigSendType" SG_ 830 WFS_Diag_LF_Aktiv_02 3;
BA_ "GenSigSwitchedByIgnition" SG_ 830 WFS_Diag_LF_Aktiv_02 0;
BA_ "GenSigSendType" SG_ 830 WFS_LF_aktiv_02 3;
BA_ "GenSigSwitchedByIgnition" SG_ 830 WFS_LF_aktiv_02 0;
BA_ "GenSigSendType" SG_ 830 WFS_Transp_Mod_Unterbrechung_02 3;
BA_ "GenSigSwitchedByIgnition" SG_ 830 WFS_Transp_Mod_Unterbrechung_02 0;
BA_ "GenSigSendType" SG_ 830 WFS_Verbau_Transp_Ant_02 3;
BA_ "GenSigSwitchedByIgnition" SG_ 830 WFS_Verbau_Transp_Ant_02 0;
BA_ "GenSigSendType" SG_ 1702 BCM1_SRA_aktiv 3;
BA_ "GenSigSwitchedByIgnition" SG_ 1702 BCM1_SRA_aktiv 0;
BA_ "GenSigSendType" SG_ 1702 Waschen_vorne_aktiv 3;
BA_ "GenSigSwitchedByIgnition" SG_ 1702 Waschen_vorne_aktiv 0;
BA_ "Fehlerwert" SG_ 1702 Wischer1_Wischgeschwindigkeit 63;
BA_ "GenSigSendType" SG_ 1702 Wischer1_Wischgeschwindigkeit 0;
BA_ "GenSigStartValue" SG_ 1702 Wischer1_Wischgeschwindigkeit 62;
BA_ "GenSigSwitchedByIgnition" SG_ 1702 Wischer1_Wischgeschwindigkeit 0;
BA_ "GenSigSendType" SG_ 1702 Wischer_Anzeigetext 3;
BA_ "GenSigSwitchedByIgnition" SG_ 1702 Wischer_Anzeigetext 0;
BA_ "GenSigSendType" SG_ 1702 Wischer_vorne_aktiv 3;
BA_ "GenSigSwitchedByIgnition" SG_ 1702 Wischer_vorne_aktiv 0;
BA_ "GenSigSendType" SG_ 1702 Wischer_vorne_blockiert 3;
BA_ "GenSigSwitchedByIgnition" SG_ 1702 Wischer_vorne_blockiert 0;
BA_ "GenSigSendType" SG_ 1702 Wischer_vorne_defekt 3;
BA_ "GenSigSwitchedByIgnition" SG_ 1702 Wischer_vorne_defekt 0;
BA_ "GenSigSendType" SG_ 1702 Wischer_vorne_Normal 3;
BA_ "GenSigSwitchedByIgnition" SG_ 1702 Wischer_vorne_Normal 0;
BA_ "GenSigSendType" SG_ 1702 Wischer_vorne_Parklage 3;
BA_ "GenSigStartValue" SG_ 1702 Wischer_vorne_Parklage 1;
BA_ "GenSigSwitchedByIgnition" SG_ 1702 Wischer_vorne_Parklage 0;
BA_ "GenSigSendType" SG_ 1702 Wischer_vorne_Schnell 3;
BA_ "GenSigSwitchedByIgnition" SG_ 1702 Wischer_vorne_Schnell 0;
BA_ "GenSigSendType" SG_ 1702 Wischer_WH_PopUp_Anf 3;
BA_ "GenSigSwitchedByIgnition" SG_ 1702 Wischer_WH_PopUp_Anf 0;
BA_ "GenSigSendType" SG_ 1702 Wischer_WH_Typ 0;
BA_ "GenSigSwitchedByIgnition" SG_ 1702 Wischer_WH_Typ 0;
BA_ "GenSigFuncType" SG_ 1702 WWSs_01_alt 5;
BA_ "GenSigSendType" SG_ 1702 WWSs_01_alt 0;
BA_ "GenSigStartValue" SG_ 1702 WWSs_01_alt 1;
BA_ "GenSigSwitchedByIgnition" SG_ 1702 WWSs_01_alt 0;
BA_ "GenSigSendType" SG_ 2589283611 WLC1_aktive_Spule 3;
BA_ "GenSigSwitchedByIgnition" SG_ 2589283611 WLC1_aktive_Spule 0;
BA_ "GenSigSendType" SG_ 2589283611 WLC1_Charger_Effizienz 3;
BA_ "GenSigSwitchedByIgnition" SG_ 2589283611 WLC1_Charger_Effizienz 0;
BA_ "GenSigSendType" SG_ 2589283611 WLC1_Charger_laedt 3;
BA_ "GenSigSwitchedByIgnition" SG_ 2589283611 WLC1_Charger_laedt 0;
BA_ "GenSigSendType" SG_ 2589283611 WLC1_Fehler 3;
BA_ "GenSigSwitchedByIgnition" SG_ 2589283611 WLC1_Fehler 0;
BA_ "GenSigSendType" SG_ 2589283611 WLC1_Fremdobjekt_erkannt 3;
BA_ "GenSigSwitchedByIgnition" SG_ 2589283611 WLC1_Fremdobjekt_erkannt 0;
BA_ "GenSigSendType" SG_ 2589283611 WLC1_Leistungsklasse_Receiver 0;
BA_ "GenSigSwitchedByIgnition" SG_ 2589283611 WLC1_Leistungsklasse_Receiver 0;
BA_ "GenSigSendType" SG_ 2589283611 WLC1_Objekt_erkannt 3;
BA_ "GenSigSwitchedByIgnition" SG_ 2589283611 WLC1_Objekt_erkannt 0;
BA_ "GenSigSendType" SG_ 2589283611 WLC1_Receiver_erkannt 3;
BA_ "GenSigSwitchedByIgnition" SG_ 2589283611 WLC1_Receiver_erkannt 0;
BA_ "GenSigSendType" SG_ 2589283611 WLC1_Receiver_voll_geladen 3;
BA_ "GenSigSwitchedByIgnition" SG_ 2589283611 WLC1_Receiver_voll_geladen 0;
BA_ "GenSigSendType" SG_ 2589283611 WLC1_Temp_Leistungsteil_Charger 0;
BA_ "GenSigSwitchedByIgnition" SG_ 2589283611 WLC1_Temp_Leistungsteil_Charger 0;
BA_ "GenSigSendType" SG_ 2589283611 WLC1_Temp_Oberfaeche_Charger 0;
BA_ "GenSigSwitchedByIgnition" SG_ 2589283611 WLC1_Temp_Oberfaeche_Charger 0;
BA_ "GenSigSendType" SG_ 2589283611 WLC1_Temp_Receiver 0;
BA_ "GenSigSwitchedByIgnition" SG_ 2589283611 WLC1_Temp_Receiver 0;
BA_ "GenSigSendType" SG_ 2589283611 WLC1_verwendeter_Ladestandard 0;
BA_ "GenSigSwitchedByIgnition" SG_ 2589283611 WLC1_verwendeter_Ladestandard 0;
BA_ "GenSigSwitchedByIgnition" SG_ 2591965952 XCP_SmaLi_CRO_01_Data 0;
BA_ "GenSigSwitchedByIgnition" SG_ 2591965953 XCP_SmaLi_DTO_01_Data 0;
BA_ "GenSigSendType" SG_ 2589283768 BasicUTC_Day 0;
BA_ "GenSigSwitchedByIgnition" SG_ 2589283768 BasicUTC_Day 0;
BA_ "GenSigSendType" SG_ 2589283768 BasicUTC_Hour 0;
BA_ "GenSigStartValue" SG_ 2589283768 BasicUTC_Hour 31;
BA_ "GenSigSwitchedByIgnition" SG_ 2589283768 BasicUTC_Hour 0;
BA_ "GenSigSendType" SG_ 2589283768 BasicUTC_Minute 0;
BA_ "GenSigStartValue" SG_ 2589283768 BasicUTC_Minute 63;
BA_ "GenSigSwitchedByIgnition" SG_ 2589283768 BasicUTC_Minute 0;
BA_ "GenSigSendType" SG_ 2589283768 BasicUTC_Month 0;
BA_ "GenSigStartValue" SG_ 2589283768 BasicUTC_Month 15;
BA_ "GenSigSwitchedByIgnition" SG_ 2589283768 BasicUTC_Month 0;
BA_ "Fehlerwert" SG_ 2589283768 BasicUTC_Quality 3;
BA_ "GenSigSendType" SG_ 2589283768 BasicUTC_Quality 0;
BA_ "GenSigSwitchedByIgnition" SG_ 2589283768 BasicUTC_Quality 0;
BA_ "GenSigSendType" SG_ 2589283768 BasicUTC_Second 0;
BA_ "GenSigStartValue" SG_ 2589283768 BasicUTC_Second 63;
BA_ "GenSigSwitchedByIgnition" SG_ 2589283768 BasicUTC_Second 0;
BA_ "GenSigSendType" SG_ 2589283768 BasicUTC_Year 0;
BA_ "GenSigStartValue" SG_ 2589283768 BasicUTC_Year 4095;
BA_ "GenSigSwitchedByIgnition" SG_ 2589283768 BasicUTC_Year 0;
BA_ "Fehlerwert" SG_ 1140 DI_Screendesign 7;
BA_ "GenSigSendType" SG_ 1140 DI_Screendesign 3;
BA_ "GenSigStartValue" SG_ 1140 DI_Screendesign 6;
BA_ "GenSigSwitchedByIgnition" SG_ 1140 DI_Screendesign 0;
BA_ "GenSigSendType" SG_ 1140 MMI_State 3;
BA_ "GenSigSwitchedByIgnition" SG_ 1140 MMI_State 0;
BA_ "GenSigSendType" SG_ 1140 SI_ICAN 3;
BA_ "GenSigStartValue" SG_ 1140 SI_ICAN 1;
BA_ "GenSigSwitchedByIgnition" SG_ 1140 SI_ICAN 0;
BA_ "GenSigSendType" SG_ 1140 WLC1_Systemzustand 3;
BA_ "GenSigSwitchedByIgnition" SG_ 1140 WLC1_Systemzustand 0;
BA_ "GenSigSendType" SG_ 1140 WLC2_Systemzustand 3;
BA_ "GenSigSwitchedByIgnition" SG_ 1140 WLC2_Systemzustand 0;
BA_ "GenSigSendType" SG_ 1140 ZR_DimOffs_DU_1 3;
BA_ "GenSigStartValue" SG_ 1140 ZR_DimOffs_DU_1 14;
BA_ "GenSigSwitchedByIgnition" SG_ 1140 ZR_DimOffs_DU_1 0;
BA_ "GenSigSendType" SG_ 1140 ZR_DimOffs_DU_2 3;
BA_ "GenSigStartValue" SG_ 1140 ZR_DimOffs_DU_2 14;
BA_ "GenSigSwitchedByIgnition" SG_ 1140 ZR_DimOffs_DU_2 0;
BA_ "GenSigSendType" SG_ 1140 ZR_DimOffs_DU_3 3;
BA_ "GenSigStartValue" SG_ 1140 ZR_DimOffs_DU_3 14;
BA_ "GenSigSwitchedByIgnition" SG_ 1140 ZR_DimOffs_DU_3 0;
BA_ "GenSigSendType" SG_ 1140 ZR_DimOffs_DU_4 3;
BA_ "GenSigSendType" SG_ 1140 ZR_Lenkerposition 0;
BA_ "GenSigSwitchedByIgnition" SG_ 1140 ZR_Lenkerposition 0;
BA_ "GenSigSendType" SG_ 1140 ZR_State_DU_1 3;
BA_ "GenSigSwitchedByIgnition" SG_ 1140 ZR_State_DU_1 0;
BA_ "GenSigSendType" SG_ 1140 ZR_State_DU_2 3;
BA_ "GenSigSwitchedByIgnition" SG_ 1140 ZR_State_DU_2 0;
BA_ "GenSigSendType" SG_ 1140 ZR_State_DU_3 3;
BA_ "GenSigSwitchedByIgnition" SG_ 1140 ZR_State_DU_3 0;
BA_ "GenSigSendType" SG_ 1140 ZR_State_DU_4 3;
BA_ "GenSigSendType" SG_ 1140 ZR_WecktGesp 3;
BA_ "GenSigSwitchedByIgnition" SG_ 1140 ZR_WecktGesp 0;
BA_ "GenSigSendType" SG_ 2589283965 DFB_CILState_ADA 3;
BA_ "GenSigSwitchedByIgnition" SG_ 2589283965 DFB_CILState_ADA 0;
BA_ "GenSigSendType" SG_ 2589283965 DFB_InteractionStatus_ADA 3;
BA_ "GenSigSwitchedByIgnition" SG_ 2589283965 DFB_InteractionStatus_ADA 0;
BA_ "GenSigSendType" SG_ 2589283965 SpeechAssistant_State 3;
BA_ "GenSigSwitchedByIgnition" SG_ 2589283965 SpeechAssistant_State 0;
BA_ "GenSigSendType" SG_ 2589283965 ZR_Plattform 3;
BA_ "GenSigSwitchedByIgnition" SG_ 2589283965 ZR_Plattform 0;
BA_ "GenSigSendType" SG_ 1411 BCM_FH_Freigabe 3;
BA_ "GenSigSwitchedByIgnition" SG_ 1411 BCM_FH_Freigabe 0;
BA_ "GenSigSendType" SG_ 1411 BCM_HSK_Freigabe 3;
BA_ "GenSigSwitchedByIgnition" SG_ 1411 BCM_HSK_Freigabe 0;
BA_ "GenSigSendType" SG_ 1411 BCM_Komfortfkt_Freigabe 3;
BA_ "GenSigSwitchedByIgnition" SG_ 1411 BCM_Komfortfkt_Freigabe 0;
BA_ "GenSigSendType" SG_ 1411 BCM_Verdeck_Freigabe 3;
BA_ "GenSigSwitchedByIgnition" SG_ 1411 BCM_Verdeck_Freigabe 0;
BA_ "GenSigSendType" SG_ 1411 DWA_aktiv 3;
BA_ "GenSigSwitchedByIgnition" SG_ 1411 DWA_aktiv 0;
BA_ "GenSigSendType" SG_ 1411 FBS_IDG_in_Reichweite 6;
BA_ "GenSigSwitchedByIgnition" SG_ 1411 FBS_IDG_in_Reichweite 0;
BA_ "GenSigSendType" SG_ 1411 FBS_Warn_Schluessel_Batt 3;
BA_ "GenSigSwitchedByIgnition" SG_ 1411 FBS_Warn_Schluessel_Batt 0;
BA_ "GenSigSendType" SG_ 1411 FFB_Auf_Taste 6;
BA_ "GenSigSwitchedByIgnition" SG_ 1411 FFB_Auf_Taste 0;
BA_ "GenSigSendType" SG_ 1411 FFB_CarFinder 6;
BA_ "GenSigSwitchedByIgnition" SG_ 1411 FFB_CarFinder 0;
BA_ "GenSigSendType" SG_ 1411 FFB_HDF_Taste 6;
BA_ "GenSigSwitchedByIgnition" SG_ 1411 FFB_HDF_Taste 0;
BA_ "GenSigSendType" SG_ 1411 FFB_Komfortoeffnen 6;
BA_ "GenSigSwitchedByIgnition" SG_ 1411 FFB_Komfortoeffnen 0;
BA_ "GenSigSendType" SG_ 1411 FFB_Komfortschliessen 6;
BA_ "GenSigSwitchedByIgnition" SG_ 1411 FFB_Komfortschliessen 0;
BA_ "GenSigSendType" SG_ 1411 FFB_Panik_Taste 6;
BA_ "GenSigSwitchedByIgnition" SG_ 1411 FFB_Panik_Taste 0;
BA_ "GenSigSendType" SG_ 1411 FFB_Zu_Taste 6;
BA_ "GenSigSwitchedByIgnition" SG_ 1411 FFB_Zu_Taste 0;
BA_ "GenSigSendType" SG_ 1411 IRUE_aktiv 3;
BA_ "GenSigSwitchedByIgnition" SG_ 1411 IRUE_aktiv 0;
BA_ "GenSigSendType" SG_ 1411 IRUE_Taster_Fkts_LED 3;
BA_ "GenSigSwitchedByIgnition" SG_ 1411 IRUE_Taster_Fkts_LED 0;
BA_ "GenSigSendType" SG_ 1411 VIP_Sensor_STSG_HBFS_betaetigt 6;
BA_ "GenSigSwitchedByIgnition" SG_ 1411 VIP_Sensor_STSG_HBFS_betaetigt 0;
BA_ "GenSigSendType" SG_ 1411 VIP_Sensor_STSG_HFS_betaetigt 6;
BA_ "GenSigSwitchedByIgnition" SG_ 1411 VIP_Sensor_STSG_HFS_betaetigt 0;
BA_ "GenSigSendType" SG_ 1411 ZV_Anf_Challenge_Auth 6;
BA_ "GenSigSwitchedByIgnition" SG_ 1411 ZV_Anf_Challenge_Auth 0;
BA_ "GenSigSendType" SG_ 1411 ZV_BT_offen 3;
BA_ "GenSigSwitchedByIgnition" SG_ 1411 ZV_BT_offen 0;
BA_ "GenSigSendType" SG_ 1411 ZV_Einzeltuerentriegelung 3;
BA_ "GenSigSwitchedByIgnition" SG_ 1411 ZV_Einzeltuerentriegelung 0;
BA_ "GenSigSendType" SG_ 1411 ZV_eRWK_Umfeld_Pruefung 6;
BA_ "GenSigSwitchedByIgnition" SG_ 1411 ZV_eRWK_Umfeld_Pruefung 0;
BA_ "GenSigSendType" SG_ 1411 ZV_FT_offen 3;
BA_ "GenSigSwitchedByIgnition" SG_ 1411 ZV_FT_offen 0;
BA_ "GenSigSendType" SG_ 1411 ZV_gesafet_extern_ist 3;
BA_ "GenSigSwitchedByIgnition" SG_ 1411 ZV_gesafet_extern_ist 0;
BA_ "GenSigSendType" SG_ 1411 ZV_gesafet_extern_soll 3;
BA_ "GenSigSwitchedByIgnition" SG_ 1411 ZV_gesafet_extern_soll 0;
BA_ "GenSigSendType" SG_ 1411 ZV_HBFS_offen 3;
BA_ "GenSigSwitchedByIgnition" SG_ 1411 ZV_HBFS_offen 0;
BA_ "GenSigSendType" SG_ 1411 ZV_HD_offen 3;
BA_ "GenSigSwitchedByIgnition" SG_ 1411 ZV_HD_offen 0;
BA_ "GenSigSendType" SG_ 1411 ZV_Heckeinzelentriegelung 3;
BA_ "GenSigSwitchedByIgnition" SG_ 1411 ZV_Heckeinzelentriegelung 0;
BA_ "GenSigSendType" SG_ 1411 ZV_HFS_offen 3;
BA_ "GenSigSwitchedByIgnition" SG_ 1411 ZV_HFS_offen 0;
BA_ "GenSigSendType" SG_ 1411 ZV_HS_offen 3;
BA_ "GenSigSwitchedByIgnition" SG_ 1411 ZV_HS_offen 0;
BA_ "GenSigSendType" SG_ 1411 ZV_ist_Zustand_verfuegbar 3;
BA_ "GenSigSwitchedByIgnition" SG_ 1411 ZV_ist_Zustand_verfuegbar 0;
BA_ "GenSigSendType" SG_ 1411 ZV_Oeffnungsmodus 3;
BA_ "GenSigSwitchedByIgnition" SG_ 1411 ZV_Oeffnungsmodus 0;
BA_ "GenSigSendType" SG_ 1411 ZV_Rollo_auf 3;
BA_ "GenSigSwitchedByIgnition" SG_ 1411 ZV_Rollo_auf 0;
BA_ "GenSigSendType" SG_ 1411 ZV_Rollo_zu 3;
BA_ "GenSigSwitchedByIgnition" SG_ 1411 ZV_Rollo_zu 0;
BA_ "GenSigSendType" SG_ 1411 ZV_SAD_auf 3;
BA_ "GenSigSwitchedByIgnition" SG_ 1411 ZV_SAD_auf 0;
BA_ "GenSigSendType" SG_ 1411 ZV_SAD_zu 3;
BA_ "GenSigSwitchedByIgnition" SG_ 1411 ZV_SAD_zu 0;
BA_ "GenSigSendType" SG_ 1411 ZV_SafeFunktion_aktiv 3;
BA_ "GenSigSwitchedByIgnition" SG_ 1411 ZV_SafeFunktion_aktiv 0;
BA_ "GenSigSendType" SG_ 1411 ZV_Schluessel_Zugang 3;
BA_ "GenSigSwitchedByIgnition" SG_ 1411 ZV_Schluessel_Zugang 0;
BA_ "GenSigSendType" SG_ 1411 ZV_STSG_HBFS_Anf 3;
BA_ "GenSigSwitchedByIgnition" SG_ 1411 ZV_STSG_HBFS_Anf 0;
BA_ "GenSigSendType" SG_ 1411 ZV_STSG_HFS_Anf 3;
BA_ "GenSigSwitchedByIgnition" SG_ 1411 ZV_STSG_HFS_Anf 0;
BA_ "GenSigSendType" SG_ 1411 ZV_Tankklappe_offen 0;
BA_ "GenSigSwitchedByIgnition" SG_ 1411 ZV_Tankklappe_offen 0;
BA_ "GenSigSendType" SG_ 1411 ZV_verriegeln_Anf 6;
BA_ "GenSigSwitchedByIgnition" SG_ 1411 ZV_verriegeln_Anf 0;
BA_ "GenSigSendType" SG_ 1411 ZV_verriegelt_extern_ist 3;
BA_ "GenSigSwitchedByIgnition" SG_ 1411 ZV_verriegelt_extern_ist 0;
BA_ "GenSigSendType" SG_ 1411 ZV_verriegelt_extern_soll 3;
BA_ "GenSigSwitchedByIgnition" SG_ 1411 ZV_verriegelt_extern_soll 0;
BA_ "GenSigSendType" SG_ 1411 ZV_verriegelt_intern_ist 3;
BA_ "GenSigSwitchedByIgnition" SG_ 1411 ZV_verriegelt_intern_ist 0;
BA_ "GenSigSendType" SG_ 1411 ZV_verriegelt_intern_soll 3;
BA_ "GenSigSwitchedByIgnition" SG_ 1411 ZV_verriegelt_intern_soll 0;
BA_ "GenSigSendType" SG_ 1411 ZV_verriegelt_soll 3;
BA_ "GenSigSwitchedByIgnition" SG_ 1411 ZV_verriegelt_soll 0;
BA_ "GenSigSendType" SG_ 708 BCM_Waehlhebel_P_Hinweis 4;
BA_ "GenSigSwitchedByIgnition" SG_ 708 BCM_Waehlhebel_P_Hinweis 0;
BA_ "GenSigSendType" SG_ 708 UHF_FFB_Funkschluesseltyp 4;
BA_ "GenSigSwitchedByIgnition" SG_ 708 UHF_FFB_Funkschluesseltyp 0;
BA_ "GenSigSendType" SG_ 708 UHF_FFB_SKC_anlernen 4;
BA_ "GenSigSwitchedByIgnition" SG_ 708 UHF_FFB_SKC_anlernen 0;
BA_ "GenSigFuncType" SG_ 708 ZV_04_BZ 1;
BA_ "GenSigSendType" SG_ 708 ZV_04_BZ 0;
BA_ "GenSigSwitchedByIgnition" SG_ 708 ZV_04_BZ 0;
BA_ "GenSigFuncType" SG_ 708 ZV_04_CRC 2;
BA_ "GenSigSendType" SG_ 708 ZV_04_CRC 0;
BA_ "GenSigSendType" SG_ 708 ZV_DWA_Einfachhorn_Anf 4;
BA_ "GenSigSwitchedByIgnition" SG_ 708 ZV_DWA_Einfachhorn_Anf 0;
BA_ "GenSigSendType" SG_ 708 ZV_DWA_Einfachhorn_Takt 4;
BA_ "GenSigSwitchedByIgnition" SG_ 708 ZV_DWA_Einfachhorn_Takt 0;
BA_ "GenSigSendType" SG_ 708 ZV_Einfachhorn_Anf 4;
BA_ "GenSigSwitchedByIgnition" SG_ 708 ZV_Einfachhorn_Anf 0;
BA_ "GenSigSendType" SG_ 708 ZV_Einfachhorn_Takt 4;
BA_ "GenSigSwitchedByIgnition" SG_ 708 ZV_Einfachhorn_Takt 0;
BA_ "GenSigSendType" SG_ 708 ZV_HBFS_Status_KiSi 4;
BA_ "GenSigSwitchedByIgnition" SG_ 708 ZV_HBFS_Status_KiSi 0;
BA_ "GenSigSendType" SG_ 708 ZV_HBFS_TAG_betaetigt 4;
BA_ "GenSigSwitchedByIgnition" SG_ 708 ZV_HBFS_TAG_betaetigt 0;
BA_ "GenSigSendType" SG_ 708 ZV_HBFS_TIG_oeffnen_betaetigt 4;
BA_ "GenSigSwitchedByIgnition" SG_ 708 ZV_HBFS_TIG_oeffnen_betaetigt 0;
BA_ "GenSigSendType" SG_ 708 ZV_HBFS_TIG_schliessen_betaetigt 4;
BA_ "GenSigSwitchedByIgnition" SG_ 708 ZV_HBFS_TIG_schliessen_betaetigt 0;
BA_ "GenSigSendType" SG_ 708 ZV_HD_Parkbremse_Hinweis 4;
BA_ "GenSigSwitchedByIgnition" SG_ 708 ZV_HD_Parkbremse_Hinweis 0;
BA_ "GenSigSendType" SG_ 708 ZV_HFS_Status_KiSi 4;
BA_ "GenSigSwitchedByIgnition" SG_ 708 ZV_HFS_Status_KiSi 0;
BA_ "GenSigSendType" SG_ 708 ZV_HFS_TAG_betaetigt 4;
BA_ "GenSigSwitchedByIgnition" SG_ 708 ZV_HFS_TAG_betaetigt 0;
BA_ "GenSigSendType" SG_ 708 ZV_HFS_TIG_oeffnen_betaetigt 4;
BA_ "GenSigSwitchedByIgnition" SG_ 708 ZV_HFS_TIG_oeffnen_betaetigt 0;
BA_ "GenSigSendType" SG_ 708 ZV_HFS_TIG_schliessen_betaetigt 4;
BA_ "GenSigSwitchedByIgnition" SG_ 708 ZV_HFS_TIG_schliessen_betaetigt 0;
BA_ "GenSigSendType" SG_ 708 ZV_Hupe_Anf 4;
BA_ "GenSigSwitchedByIgnition" SG_ 708 ZV_Hupe_Anf 0;
BA_ "GenSigSendType" SG_ 708 ZV_Hupe_Takt 4;
BA_ "GenSigSwitchedByIgnition" SG_ 708 ZV_Hupe_Takt 0;
BA_ "GenSigSendType" SG_ 708 ZV_HW_Motor_Lock_HK 6;
BA_ "GenSigSwitchedByIgnition" SG_ 708 ZV_HW_Motor_Lock_HK 0;
BA_ "GenSigSendType" SG_ 708 ZV_HW_Motor_Safe_Hinten 6;
BA_ "GenSigSwitchedByIgnition" SG_ 708 ZV_HW_Motor_Safe_Hinten 0;
BA_ "GenSigSendType" SG_ 708 ZV_HW_TKL_mot_entr 4;
BA_ "GenSigSwitchedByIgnition" SG_ 708 ZV_HW_TKL_mot_entr 0;
BA_ "GenSigSendType" SG_ 708 ZV_HW_TKL_mot_verr 4;
BA_ "GenSigSwitchedByIgnition" SG_ 708 ZV_HW_TKL_mot_verr 0;
BA_ "GenSigSendType" SG_ 708 ZV_Laderaumabd_elektr_aktiviert 3;
BA_ "GenSigSwitchedByIgnition" SG_ 708 ZV_Laderaumabd_elektr_aktiviert 0;
BA_ "GenSigSendType" SG_ 708 ZV_Status_Cargolock 4;
BA_ "GenSigSwitchedByIgnition" SG_ 708 ZV_Status_Cargolock 0;
BA_ "Fehlerwert" SG_ 708 ZV_Status_KiSi_CargoLock 7;
BA_ "GenSigSendType" SG_ 708 ZV_Status_KiSi_CargoLock 4;
BA_ "GenSigSwitchedByIgnition" SG_ 708 ZV_Status_KiSi_CargoLock 0;
BA_ "Fehlerwert" SG_ 708 ZV_verriegelt_extern_soll_03 3;
BA_ "GenSigSendType" SG_ 708 ZV_verriegelt_extern_soll_03 4;
BA_ "GenSigSwitchedByIgnition" SG_ 708 ZV_verriegelt_extern_soll_03 0;
BA_REL_ "GenSigTimeoutTime" BU_SG_REL_ Fahrerdisplay_Kombi SG_ 916 WBA_03_BZ 1600;
BA_REL_ "GenSigTimeoutTime" BU_SG_REL_ Fahrerdisplay_Kombi SG_ 916 WBA_03_CRC 1600;
BA_REL_ "GenSigTimeoutTime" BU_SG_REL_ Fahrerdisplay_Kombi SG_ 916 WBA_Fahrstufe_02 1600;
BA_REL_ "GenSigTimeoutTime" BU_SG_REL_ Fahrerdisplay_Kombi SG_ 1140 DI_Screendesign 5000;
BA_REL_ "GenSigTimeoutTime" BU_SG_REL_ Fahrerdisplay_Kombi SG_ 1702 Wischer_vorne_defekt 5000;
BA_REL_ "GenSigTimeoutTime" BU_SG_REL_ Fahrerdisplay_Kombi SG_ 2463978663 VZE_FoD_Status 2000;
BA_REL_ "GenSigTimeoutTime" BU_SG_REL_ Fahrerdisplay_Kombi SG_ 2463978663 VZE_Hinweistext 2000;
BA_REL_ "GenSigTimeoutTime" BU_SG_REL_ Fahrerdisplay_Kombi SG_ 2463978663 VZE_Modus_OptischeWarnung 2000;
BA_REL_ "GenSigTimeoutTime" BU_SG_REL_ Fahrerdisplay_Kombi SG_ 2463978663 VZE_SLWF_Status 2000;
BA_REL_ "GenSigTimeoutTime" BU_SG_REL_ HUD SG_ 2463978710 OPS_ComfortReadyStatus 1000;
BA_REL_ "GenSigTimeoutTime" BU_SG_REL_ HUD SG_ 2463978710 OPS_DriverPresenceStatus 1000;
BA_REL_ "GenSigTimeoutTime" BU_SG_REL_ ICAS1_X_Gateway SG_ 830 WFS_Diag_LF_Aktiv_02 5000;
BA_REL_ "GenSigTimeoutTime" BU_SG_REL_ ICAS1_X_Gateway SG_ 830 WFS_LF_aktiv_02 5000;
BA_REL_ "GenSigTimeoutTime" BU_SG_REL_ ICAS1_X_Gateway SG_ 830 WFS_Transp_Mod_Unterbrechung_02 5000;
BA_REL_ "GenSigTimeoutTime" BU_SG_REL_ ICAS1_X_Gateway SG_ 830 WFS_Verbau_Transp_Ant_02 5000;
BA_REL_ "GenSigTimeoutTime" BU_SG_REL_ ICAS1_X_Gateway SG_ 2589283965 DFB_CILState_ADA 5000;
BA_REL_ "GenSigTimeoutTime" BU_SG_REL_ ICAS1_X_Gateway SG_ 2589283965 DFB_InteractionStatus_ADA 5000;
BA_REL_ "GenSigTimeoutTime" BU_SG_REL_ ICAS1_X_Gateway SG_ 2589283965 SpeechAssistant_State 5000;
BA_REL_ "GenSigTimeoutTime" BU_SG_REL_ ICAS3_Gateway SG_ 916 WBA_Anforderung_Akustik 1600;
BA_REL_ "GenSigTimeoutTime" BU_SG_REL_ ICAS3_Gateway SG_ 974 HFS_Tuer_geoeffnet 1000;
BA_REL_ "GenSigTimeoutTime" BU_SG_REL_ ICAS3_Gateway SG_ 975 HBFS_Tuer_geoeffnet 1000;
BA_REL_ "GenSigTimeoutTime" BU_SG_REL_ ICAS3_Gateway SG_ 1411 ZV_BT_offen 2000;
BA_REL_ "GenSigTimeoutTime" BU_SG_REL_ ICAS3_Gateway SG_ 1411 ZV_FT_offen 2000;
BA_REL_ "GenSigTimeoutTime" BU_SG_REL_ ICAS3_Gateway SG_ 1411 ZV_HBFS_offen 2000;
BA_REL_ "GenSigTimeoutTime" BU_SG_REL_ ICAS3_Gateway SG_ 1411 ZV_HD_offen 2000;
BA_REL_ "GenSigTimeoutTime" BU_SG_REL_ ICAS3_Gateway SG_ 1411 ZV_HFS_offen 2000;
BA_REL_ "GenSigTimeoutTime" BU_SG_REL_ ICAS3_Gateway SG_ 1411 ZV_verriegelt_extern_soll 2000;
BA_REL_ "GenSigTimeoutTime" BU_SG_REL_ ICAS3_Gateway SG_ 1716 VIN_01_MUX 2000;
BA_REL_ "GenSigTimeoutTime" BU_SG_REL_ ICAS3_Gateway SG_ 1716 VIN_1 2000;
BA_REL_ "GenSigTimeoutTime" BU_SG_REL_ ICAS3_Gateway SG_ 1716 VIN_10 2000;
BA_REL_ "GenSigTimeoutTime" BU_SG_REL_ ICAS3_Gateway SG_ 1716 VIN_11 2000;
BA_REL_ "GenSigTimeoutTime" BU_SG_REL_ ICAS3_Gateway SG_ 1716 VIN_12 2000;
BA_REL_ "GenSigTimeoutTime" BU_SG_REL_ ICAS3_Gateway SG_ 1716 VIN_13 2000;
BA_REL_ "GenSigTimeoutTime" BU_SG_REL_ ICAS3_Gateway SG_ 1716 VIN_14 2000;
BA_REL_ "GenSigTimeoutTime" BU_SG_REL_ ICAS3_Gateway SG_ 1716 VIN_15 2000;
BA_REL_ "GenSigTimeoutTime" BU_SG_REL_ ICAS3_Gateway SG_ 1716 VIN_16 2000;
BA_REL_ "GenSigTimeoutTime" BU_SG_REL_ ICAS3_Gateway SG_ 1716 VIN_17 2000;
BA_REL_ "GenSigTimeoutTime" BU_SG_REL_ ICAS3_Gateway SG_ 1716 VIN_2 2000;
BA_REL_ "GenSigTimeoutTime" BU_SG_REL_ ICAS3_Gateway SG_ 1716 VIN_3 2000;
BA_REL_ "GenSigTimeoutTime" BU_SG_REL_ ICAS3_Gateway SG_ 1716 VIN_4 2000;
BA_REL_ "GenSigTimeoutTime" BU_SG_REL_ ICAS3_Gateway SG_ 1716 VIN_5 2000;
BA_REL_ "GenSigTimeoutTime" BU_SG_REL_ ICAS3_Gateway SG_ 1716 VIN_6 2000;
BA_REL_ "GenSigTimeoutTime" BU_SG_REL_ ICAS3_Gateway SG_ 1716 VIN_7 2000;
BA_REL_ "GenSigTimeoutTime" BU_SG_REL_ ICAS3_Gateway SG_ 1716 VIN_8 2000;
BA_REL_ "GenSigTimeoutTime" BU_SG_REL_ ICAS3_Gateway SG_ 1716 VIN_9 2000;
BA_REL_ "GenSigTimeoutTime" BU_SG_REL_ ICAS3_Gateway SG_ 2463978710 OPS_ComfortReadyStatus 1000;
BA_REL_ "GenSigTimeoutTime" BU_SG_REL_ ICAS3_Gateway SG_ 2463978710 OPS_DriverPresenceStatus 1000;
BA_REL_ "GenSigTimeoutTime" BU_SG_REL_ ICAS3_Gateway SG_ 2589283611 WLC1_Charger_laedt 5000;
BA_REL_ "GenSigTimeoutTime" BU_SG_REL_ ICAS3_Gateway SG_ 2589283611 WLC1_Fremdobjekt_erkannt 5000;
BA_REL_ "GenSigTimeoutTime" BU_SG_REL_ ICC_IO_Node SG_ 1411 ZV_FT_offen 2000;
BA_REL_ "GenSigTimeoutTime" BU_SG_REL_ ICC_IO_Node SG_ 1411 ZV_verriegelt_extern_soll 2000;
BA_REL_ "GenSigTimeoutTime" BU_SG_REL_ ICC_IO_Node SG_ 1716 VIN_01_MUX 2000;
BA_REL_ "GenSigTimeoutTime" BU_SG_REL_ ICC_IO_Node SG_ 2463978710 OPS_ComfortReadyStatus 1000;
BA_REL_ "GenSigTimeoutTime" BU_SG_REL_ ICC_IO_Node SG_ 2463978710 OPS_DriverPresenceStatus 1000;
BA_REL_ "GenSigTimeoutTime" BU_SG_REL_ Kombi SG_ 708 BCM_Waehlhebel_P_Hinweis 5000;
BA_REL_ "GenSigTimeoutTime" BU_SG_REL_ Kombi SG_ 708 ZV_HD_Parkbremse_Hinweis 5000;
BA_REL_ "GenSigTimeoutTime" BU_SG_REL_ Kombi SG_ 916 WBA_03_BZ 1600;
BA_REL_ "GenSigTimeoutTime" BU_SG_REL_ Kombi SG_ 916 WBA_03_CRC 1600;
BA_REL_ "GenSigTimeoutTime" BU_SG_REL_ Kombi SG_ 916 WBA_Anforderung_Akustik 1600;
BA_REL_ "GenSigTimeoutTime" BU_SG_REL_ Kombi SG_ 916 WBA_Fahrstufe_02 1600;
BA_REL_ "GenSigTimeoutTime" BU_SG_REL_ Kombi SG_ 916 WBA_GE_Texte 1600;
BA_REL_ "GenSigTimeoutTime" BU_SG_REL_ Kombi SG_ 916 WBA_GE_Texte_02 1600;
BA_REL_ "GenSigTimeoutTime" BU_SG_REL_ Kombi SG_ 916 WBA_GE_Warnung_02 1600;
BA_REL_ "GenSigTimeoutTime" BU_SG_REL_ Kombi SG_ 974 HFS_Tuerschloss_defekt 1000;
BA_REL_ "GenSigTimeoutTime" BU_SG_REL_ Kombi SG_ 975 HBFS_Tuerschloss_defekt 1000;
BA_REL_ "GenSigTimeoutTime" BU_SG_REL_ Kombi SG_ 1057 VLK_Hinweis_Rollfaehigkeit 1000;
BA_REL_ "GenSigTimeoutTime" BU_SG_REL_ Kombi SG_ 1057 VLK_VLW_Anf 1000;
BA_REL_ "GenSigTimeoutTime" BU_SG_REL_ Kombi SG_ 1057 VLK_autom_Absch_Signalisierung 1000;
BA_REL_ "GenSigTimeoutTime" BU_SG_REL_ Kombi SG_ 1361 WFS_Fahrerhinweise 2000;
BA_REL_ "GenSigTimeoutTime" BU_SG_REL_ Kombi SG_ 1361 WFS_LZ 2000;
BA_REL_ "GenSigTimeoutTime" BU_SG_REL_ Kombi SG_ 1361 WFS_Safe 2000;
BA_REL_ "GenSigTimeoutTime" BU_SG_REL_ Kombi SG_ 1361 WFS_Schluessel_Ist 2000;
BA_REL_ "GenSigTimeoutTime" BU_SG_REL_ Kombi SG_ 1361 WFS_Schluessel_Soll 2000;
BA_REL_ "GenSigTimeoutTime" BU_SG_REL_ Kombi SG_ 1411 FBS_Warn_Schluessel_Batt 2000;
BA_REL_ "GenSigTimeoutTime" BU_SG_REL_ Kombi SG_ 1411 ZV_BT_offen 2000;
BA_REL_ "GenSigTimeoutTime" BU_SG_REL_ Kombi SG_ 1411 ZV_FT_offen 2000;
BA_REL_ "GenSigTimeoutTime" BU_SG_REL_ Kombi SG_ 1411 ZV_HBFS_offen 2000;
BA_REL_ "GenSigTimeoutTime" BU_SG_REL_ Kombi SG_ 1411 ZV_HD_offen 2000;
BA_REL_ "GenSigTimeoutTime" BU_SG_REL_ Kombi SG_ 1411 ZV_HFS_offen 2000;
BA_REL_ "GenSigTimeoutTime" BU_SG_REL_ Kombi SG_ 1411 ZV_SafeFunktion_aktiv 2000;
BA_REL_ "GenSigTimeoutTime" BU_SG_REL_ Kombi SG_ 1411 ZV_verriegelt_extern_ist 2000;
BA_REL_ "GenSigTimeoutTime" BU_SG_REL_ Kombi SG_ 1411 ZV_verriegelt_extern_soll 2000;
BA_REL_ "GenSigTimeoutTime" BU_SG_REL_ Kombi SG_ 1702 Wischer_WH_Typ 5000;
BA_REL_ "GenSigTimeoutTime" BU_SG_REL_ Kombi SG_ 1702 Wischer_vorne_defekt 5000;
BA_REL_ "GenSigTimeoutTime" BU_SG_REL_ Kombi SG_ 1716 VIN_01_MUX 2000;
BA_REL_ "GenSigTimeoutTime" BU_SG_REL_ Kombi SG_ 1716 VIN_1 2000;
BA_REL_ "GenSigTimeoutTime" BU_SG_REL_ Kombi SG_ 1716 VIN_10 2000;
BA_REL_ "GenSigTimeoutTime" BU_SG_REL_ Kombi SG_ 1716 VIN_11 2000;
BA_REL_ "GenSigTimeoutTime" BU_SG_REL_ Kombi SG_ 1716 VIN_12 2000;
BA_REL_ "GenSigTimeoutTime" BU_SG_REL_ Kombi SG_ 1716 VIN_13 2000;
BA_REL_ "GenSigTimeoutTime" BU_SG_REL_ Kombi SG_ 1716 VIN_14 2000;
BA_REL_ "GenSigTimeoutTime" BU_SG_REL_ Kombi SG_ 1716 VIN_15 2000;
BA_REL_ "GenSigTimeoutTime" BU_SG_REL_ Kombi SG_ 1716 VIN_16 2000;
BA_REL_ "GenSigTimeoutTime" BU_SG_REL_ Kombi SG_ 1716 VIN_17 2000;
BA_REL_ "GenSigTimeoutTime" BU_SG_REL_ Kombi SG_ 1716 VIN_2 2000;
BA_REL_ "GenSigTimeoutTime" BU_SG_REL_ Kombi SG_ 1716 VIN_3 2000;
BA_REL_ "GenSigTimeoutTime" BU_SG_REL_ Kombi SG_ 1716 VIN_4 2000;
BA_REL_ "GenSigTimeoutTime" BU_SG_REL_ Kombi SG_ 1716 VIN_5 2000;
BA_REL_ "GenSigTimeoutTime" BU_SG_REL_ Kombi SG_ 1716 VIN_6 2000;
BA_REL_ "GenSigTimeoutTime" BU_SG_REL_ Kombi SG_ 1716 VIN_7 2000;
BA_REL_ "GenSigTimeoutTime" BU_SG_REL_ Kombi SG_ 1716 VIN_8 2000;
BA_REL_ "GenSigTimeoutTime" BU_SG_REL_ Kombi SG_ 1716 VIN_9 2000;
BA_REL_ "GenSigTimeoutTime" BU_SG_REL_ Kombi SG_ 2463978663 VZE_Akustik_Limitwechsel 2000;
BA_REL_ "GenSigTimeoutTime" BU_SG_REL_ Kombi SG_ 2463978663 VZE_FoD_Status 2000;
BA_REL_ "GenSigTimeoutTime" BU_SG_REL_ Kombi SG_ 2463978663 VZE_Verkehrszeichen_5 2000;
BA_REL_ "GenSigTimeoutTime" BU_SG_REL_ Kombi SG_ 2463978663 VZE_Warnung_Verkehrszeichen_5 2000;
BA_REL_ "GenSigTimeoutTime" BU_SG_REL_ Kombi SG_ 2589283768 BasicUTC_Day 5000;
BA_REL_ "GenSigTimeoutTime" BU_SG_REL_ Kombi SG_ 2589283768 BasicUTC_Hour 5000;
BA_REL_ "GenSigTimeoutTime" BU_SG_REL_ Kombi SG_ 2589283768 BasicUTC_Minute 5000;
BA_REL_ "GenSigTimeoutTime" BU_SG_REL_ Kombi SG_ 2589283768 BasicUTC_Month 5000;
BA_REL_ "GenSigTimeoutTime" BU_SG_REL_ Kombi SG_ 2589283768 BasicUTC_Quality 5000;
BA_REL_ "GenSigTimeoutTime" BU_SG_REL_ Kombi SG_ 2589283768 BasicUTC_Second 5000;
BA_REL_ "GenSigTimeoutTime" BU_SG_REL_ Kombi SG_ 2589283768 BasicUTC_Year 5000;
BA_REL_ "GenSigTimeoutTime" BU_SG_REL_ SmartLight_01 SG_ 1411 BCM_FH_Freigabe 2000;
BA_REL_ "GenSigTimeoutTime" BU_SG_REL_ SmartLight_01 SG_ 1411 BCM_Komfortfkt_Freigabe 2000;
BA_REL_ "GenSigTimeoutTime" BU_SG_REL_ SmartLight_01 SG_ 1411 DWA_aktiv 2000;
BA_REL_ "GenSigTimeoutTime" BU_SG_REL_ SmartLight_01 SG_ 1411 FBS_IDG_in_Reichweite 2000;
BA_REL_ "GenSigTimeoutTime" BU_SG_REL_ SmartLight_01 SG_ 1411 FBS_Warn_Schluessel_Batt 2000;
BA_REL_ "GenSigTimeoutTime" BU_SG_REL_ SmartLight_01 SG_ 1411 FFB_Auf_Taste 2000;
BA_REL_ "GenSigTimeoutTime" BU_SG_REL_ SmartLight_01 SG_ 1411 FFB_HDF_Taste 2000;
BA_REL_ "GenSigTimeoutTime" BU_SG_REL_ SmartLight_01 SG_ 1411 FFB_Komfortoeffnen 2000;
BA_REL_ "GenSigTimeoutTime" BU_SG_REL_ SmartLight_01 SG_ 1411 FFB_Komfortschliessen 2000;
BA_REL_ "GenSigTimeoutTime" BU_SG_REL_ SmartLight_01 SG_ 1411 FFB_Panik_Taste 2000;
BA_REL_ "GenSigTimeoutTime" BU_SG_REL_ SmartLight_01 SG_ 1411 FFB_Zu_Taste 2000;
BA_REL_ "GenSigTimeoutTime" BU_SG_REL_ SmartLight_01 SG_ 1411 IRUE_aktiv 2000;
BA_REL_ "GenSigTimeoutTime" BU_SG_REL_ SmartLight_01 SG_ 1411 ZV_BT_offen 2000;
BA_REL_ "GenSigTimeoutTime" BU_SG_REL_ SmartLight_01 SG_ 1411 ZV_Einzeltuerentriegelung 2000;
BA_REL_ "GenSigTimeoutTime" BU_SG_REL_ SmartLight_01 SG_ 1411 ZV_FT_offen 2000;
BA_REL_ "GenSigTimeoutTime" BU_SG_REL_ SmartLight_01 SG_ 1411 ZV_HBFS_offen 2000;
BA_REL_ "GenSigTimeoutTime" BU_SG_REL_ SmartLight_01 SG_ 1411 ZV_HD_offen 2000;
BA_REL_ "GenSigTimeoutTime" BU_SG_REL_ SmartLight_01 SG_ 1411 ZV_HFS_offen 2000;
BA_REL_ "GenSigTimeoutTime" BU_SG_REL_ SmartLight_01 SG_ 1411 ZV_Heckeinzelentriegelung 2000;
BA_REL_ "GenSigTimeoutTime" BU_SG_REL_ SmartLight_01 SG_ 1411 ZV_Oeffnungsmodus 2000;
BA_REL_ "GenSigTimeoutTime" BU_SG_REL_ SmartLight_01 SG_ 1411 ZV_Rollo_auf 2000;
BA_REL_ "GenSigTimeoutTime" BU_SG_REL_ SmartLight_01 SG_ 1411 ZV_Rollo_zu 2000;
BA_REL_ "GenSigTimeoutTime" BU_SG_REL_ SmartLight_01 SG_ 1411 ZV_SAD_auf 2000;
BA_REL_ "GenSigTimeoutTime" BU_SG_REL_ SmartLight_01 SG_ 1411 ZV_SAD_zu 2000;
BA_REL_ "GenSigTimeoutTime" BU_SG_REL_ SmartLight_01 SG_ 1411 ZV_SafeFunktion_aktiv 2000;
BA_REL_ "GenSigTimeoutTime" BU_SG_REL_ SmartLight_01 SG_ 1411 ZV_Schluessel_Zugang 2000;
BA_REL_ "GenSigTimeoutTime" BU_SG_REL_ SmartLight_01 SG_ 1411 ZV_gesafet_extern_ist 2000;
BA_REL_ "GenSigTimeoutTime" BU_SG_REL_ SmartLight_01 SG_ 1411 ZV_gesafet_extern_soll 2000;
BA_REL_ "GenSigTimeoutTime" BU_SG_REL_ SmartLight_01 SG_ 1411 ZV_ist_Zustand_verfuegbar 2000;
BA_REL_ "GenSigTimeoutTime" BU_SG_REL_ SmartLight_01 SG_ 1411 ZV_verriegelt_extern_ist 2000;
BA_REL_ "GenSigTimeoutTime" BU_SG_REL_ SmartLight_01 SG_ 1411 ZV_verriegelt_extern_soll 2000;
BA_REL_ "GenSigTimeoutTime" BU_SG_REL_ SmartLight_01 SG_ 1411 ZV_verriegelt_intern_ist 2000;
BA_REL_ "GenSigTimeoutTime" BU_SG_REL_ SmartLight_01 SG_ 1411 ZV_verriegelt_intern_soll 2000;
BA_REL_ "GenSigTimeoutTime" BU_SG_REL_ SmartLight_01 SG_ 1716 VIN_01_MUX 2000;
BA_REL_ "GenSigTimeoutTime" BU_SG_REL_ SmartLight_01 SG_ 1716 VIN_1 2000;
BA_REL_ "GenSigTimeoutTime" BU_SG_REL_ SmartLight_01 SG_ 1716 VIN_10 2000;
BA_REL_ "GenSigTimeoutTime" BU_SG_REL_ SmartLight_01 SG_ 1716 VIN_11 2000;
BA_REL_ "GenSigTimeoutTime" BU_SG_REL_ SmartLight_01 SG_ 1716 VIN_12 2000;
BA_REL_ "GenSigTimeoutTime" BU_SG_REL_ SmartLight_01 SG_ 1716 VIN_13 2000;
BA_REL_ "GenSigTimeoutTime" BU_SG_REL_ SmartLight_01 SG_ 1716 VIN_14 2000;
BA_REL_ "GenSigTimeoutTime" BU_SG_REL_ SmartLight_01 SG_ 1716 VIN_15 2000;
BA_REL_ "GenSigTimeoutTime" BU_SG_REL_ SmartLight_01 SG_ 1716 VIN_16 2000;
BA_REL_ "GenSigTimeoutTime" BU_SG_REL_ SmartLight_01 SG_ 1716 VIN_17 2000;
BA_REL_ "GenSigTimeoutTime" BU_SG_REL_ SmartLight_01 SG_ 1716 VIN_2 2000;
BA_REL_ "GenSigTimeoutTime" BU_SG_REL_ SmartLight_01 SG_ 1716 VIN_3 2000;
BA_REL_ "GenSigTimeoutTime" BU_SG_REL_ SmartLight_01 SG_ 1716 VIN_4 2000;
BA_REL_ "GenSigTimeoutTime" BU_SG_REL_ SmartLight_01 SG_ 1716 VIN_5 2000;
BA_REL_ "GenSigTimeoutTime" BU_SG_REL_ SmartLight_01 SG_ 1716 VIN_6 2000;
BA_REL_ "GenSigTimeoutTime" BU_SG_REL_ SmartLight_01 SG_ 1716 VIN_7 2000;
BA_REL_ "GenSigTimeoutTime" BU_SG_REL_ SmartLight_01 SG_ 1716 VIN_8 2000;
BA_REL_ "GenSigTimeoutTime" BU_SG_REL_ SmartLight_01 SG_ 1716 VIN_9 2000;
BA_REL_ "GenSigTimeoutTime" BU_SG_REL_ ZR_MIB_TOP_ab_Gen3 SG_ 916 WBA_Fahrstufe_02 1600;
BA_REL_ "GenSigTimeoutTime" BU_SG_REL_ ZR_MIB_TOP_ab_Gen3 SG_ 974 HFS_Tuer_geoeffnet 1000;
BA_REL_ "GenSigTimeoutTime" BU_SG_REL_ ZR_MIB_TOP_ab_Gen3 SG_ 975 HBFS_Tuer_geoeffnet 1000;
BA_REL_ "GenSigTimeoutTime" BU_SG_REL_ ZR_MIB_TOP_ab_Gen3 SG_ 1361 WFS_Schluessel_Fahrberecht 2000;
BA_REL_ "GenSigTimeoutTime" BU_SG_REL_ ZR_MIB_TOP_ab_Gen3 SG_ 1361 WFS_Schluessel_Ist 2000;
BA_REL_ "GenSigTimeoutTime" BU_SG_REL_ ZR_MIB_TOP_ab_Gen3 SG_ 1361 WFS_Schluessel_Soll 2000;
BA_REL_ "GenSigTimeoutTime" BU_SG_REL_ ZR_MIB_TOP_ab_Gen3 SG_ 1411 ZV_BT_offen 2000;
BA_REL_ "GenSigTimeoutTime" BU_SG_REL_ ZR_MIB_TOP_ab_Gen3 SG_ 1411 ZV_FT_offen 2000;
BA_REL_ "GenSigTimeoutTime" BU_SG_REL_ ZR_MIB_TOP_ab_Gen3 SG_ 1411 ZV_HBFS_offen 2000;
BA_REL_ "GenSigTimeoutTime" BU_SG_REL_ ZR_MIB_TOP_ab_Gen3 SG_ 1411 ZV_HD_offen 2000;
BA_REL_ "GenSigTimeoutTime" BU_SG_REL_ ZR_MIB_TOP_ab_Gen3 SG_ 1411 ZV_HFS_offen 2000;
BA_REL_ "GenSigTimeoutTime" BU_SG_REL_ ZR_MIB_TOP_ab_Gen3 SG_ 1411 ZV_verriegelt_extern_soll 2000;
BA_REL_ "GenSigTimeoutTime" BU_SG_REL_ ZR_MIB_TOP_ab_Gen3 SG_ 1716 KS_Geheimnis_1 2000;
BA_REL_ "GenSigTimeoutTime" BU_SG_REL_ ZR_MIB_TOP_ab_Gen3 SG_ 1716 KS_Geheimnis_2 2000;
BA_REL_ "GenSigTimeoutTime" BU_SG_REL_ ZR_MIB_TOP_ab_Gen3 SG_ 1716 KS_Geheimnis_3 2000;
BA_REL_ "GenSigTimeoutTime" BU_SG_REL_ ZR_MIB_TOP_ab_Gen3 SG_ 1716 KS_Geheimnis_4 2000;
BA_REL_ "GenSigTimeoutTime" BU_SG_REL_ ZR_MIB_TOP_ab_Gen3 SG_ 1716 VIN_01_MUX 2000;
BA_REL_ "GenSigTimeoutTime" BU_SG_REL_ ZR_MIB_TOP_ab_Gen3 SG_ 1716 VIN_1 2000;
BA_REL_ "GenSigTimeoutTime" BU_SG_REL_ ZR_MIB_TOP_ab_Gen3 SG_ 1716 VIN_10 2000;
BA_REL_ "GenSigTimeoutTime" BU_SG_REL_ ZR_MIB_TOP_ab_Gen3 SG_ 1716 VIN_11 2000;
BA_REL_ "GenSigTimeoutTime" BU_SG_REL_ ZR_MIB_TOP_ab_Gen3 SG_ 1716 VIN_12 2000;
BA_REL_ "GenSigTimeoutTime" BU_SG_REL_ ZR_MIB_TOP_ab_Gen3 SG_ 1716 VIN_13 2000;
BA_REL_ "GenSigTimeoutTime" BU_SG_REL_ ZR_MIB_TOP_ab_Gen3 SG_ 1716 VIN_14 2000;
BA_REL_ "GenSigTimeoutTime" BU_SG_REL_ ZR_MIB_TOP_ab_Gen3 SG_ 1716 VIN_15 2000;
BA_REL_ "GenSigTimeoutTime" BU_SG_REL_ ZR_MIB_TOP_ab_Gen3 SG_ 1716 VIN_16 2000;
BA_REL_ "GenSigTimeoutTime" BU_SG_REL_ ZR_MIB_TOP_ab_Gen3 SG_ 1716 VIN_17 2000;
BA_REL_ "GenSigTimeoutTime" BU_SG_REL_ ZR_MIB_TOP_ab_Gen3 SG_ 1716 VIN_2 2000;
BA_REL_ "GenSigTimeoutTime" BU_SG_REL_ ZR_MIB_TOP_ab_Gen3 SG_ 1716 VIN_3 2000;
BA_REL_ "GenSigTimeoutTime" BU_SG_REL_ ZR_MIB_TOP_ab_Gen3 SG_ 1716 VIN_4 2000;
BA_REL_ "GenSigTimeoutTime" BU_SG_REL_ ZR_MIB_TOP_ab_Gen3 SG_ 1716 VIN_5 2000;
BA_REL_ "GenSigTimeoutTime" BU_SG_REL_ ZR_MIB_TOP_ab_Gen3 SG_ 1716 VIN_6 2000;
BA_REL_ "GenSigTimeoutTime" BU_SG_REL_ ZR_MIB_TOP_ab_Gen3 SG_ 1716 VIN_7 2000;
BA_REL_ "GenSigTimeoutTime" BU_SG_REL_ ZR_MIB_TOP_ab_Gen3 SG_ 1716 VIN_8 2000;
BA_REL_ "GenSigTimeoutTime" BU_SG_REL_ ZR_MIB_TOP_ab_Gen3 SG_ 1716 VIN_9 2000;
BA_REL_ "GenSigTimeoutTime" BU_SG_REL_ ZR_MIB_TOP_ab_Gen3 SG_ 2463978663 VZE_FoD_Status 2000;
BA_REL_ "GenSigTimeoutTime" BU_SG_REL_ ZR_MIB_TOP_ab_Gen3 SG_ 2463978710 OPS_ComfortReadyStatus 1000;
BA_REL_ "GenSigTimeoutTime" BU_SG_REL_ ZR_MIB_TOP_ab_Gen3 SG_ 2589283611 WLC1_Charger_laedt 5000;
BA_REL_ "GenSigTimeoutTime" BU_SG_REL_ ZR_MIB_TOP_ab_Gen3 SG_ 2589283611 WLC1_Fremdobjekt_erkannt 5000;
VAL_ 975 ASW_Warnung_aktiv_HBFS 0 "nicht_angefordert" 1 "angefordert" ;
VAL_ 975 HBFS_FH_Bew_hoch 0 "inaktiv" 1 "aktiv" ;
VAL_ 975 HBFS_FH_Bew_tief 0 "inaktiv" 1 "aktiv" ;
VAL_ 975 HBFS_FH_Block 0 "inaktiv" 1 "aktiv" ;
VAL_ 975 HBFS_FH_Fang 0 "ausserhalb_Fangbereich" 1 "innerhalb_Fangbereich" ;
VAL_ 975 HBFS_FH_normiert 0 "inaktiv" 1 "aktiv" ;
VAL_ 975 HBFS_FH_S_AutoHoch 0 "nicht_betaetigt" 1 "betaetigt" ;
VAL_ 975 HBFS_FH_S_AutoTief 0 "nicht_betaetigt" 1 "betaetigt" ;
VAL_ 975 HBFS_FH_S_HFS_AutoHoch 0 "keine_Bedienung" 1 "Automatiklauf_Angefordert" ;
VAL_ 975 HBFS_FH_S_HFS_AutoTief 0 "keine_Bedienung" 1 "Automatiklauf_Angefordert" ;
VAL_ 975 HBFS_FH_S_HFS_ManHoch 0 "keine_Bedienung" 1 "Manueller_Lauf_Angefordert" ;
VAL_ 975 HBFS_FH_S_HFS_ManTief 0 "keine_Bedienung" 1 "Manueller_Lauf_Angefordert" ;
VAL_ 975 HBFS_FH_S_ManHoch 0 "nicht_betaetigt" 1 "betaetigt" ;
VAL_ 975 HBFS_FH_S_ManTief 0 "nicht_betaetigt" 1 "betaetigt" ;
VAL_ 975 HBFS_FH_Thermo 0 "inaktiv" 1 "aktiv" ;
VAL_ 975 HBFS_gesafet 0 "nicht_gesafet" 1 "gesafet" ;
VAL_ 975 HBFS_Heckrollotaster_betaetigt 0 "keine_Verfahranweisung_in_Richtung_Hoch" 1 "In_Richtung_Hoch_Verfahren" ;
VAL_ 975 HBFS_Lock_Taster 0 "nicht_betaetigt" 1 "betaetigt" ;
VAL_ 975 HBFS_Lock_Taster_inv 0 "Lock Taster betï?½tgit" 1 "Lock Taster nicht betï?½tigt" ;
VAL_ 975 HBFS_MRollo_Schalter 0 "nicht_betaetigt" 1 "ZU_manuell" 2 "ZU_automatik" 3 "AUF_manuell" 4 "AUF_automatik" 5 "nicht_verfuegbar" 6 "Init" 7 "Fehler" ;
VAL_ 975 HBFS_Oben_Block_erw 0 "Fensterheber_nicht_in_Blockerwar" 1 "Fensterheber_in_Blockerwartung_o" ;
VAL_ 975 HBFS_SAD_Schalter 0 "nicht_betaetigt" 5 "AUF_manuell" 6 "AUF_automatik" 7 "ZU_manuell" 8 "ZU_automatik" 13 "nicht_verfuegbar" 14 "Init" 15 "Fehler" ;
VAL_ 975 HBFS_Seitenrollo_hoch 1 "Seitenrollo_in_Bewegung_hoch" ;
VAL_ 975 HBFS_Seitenrollo_tief 0 "Init" 1 "Seitenrollo_in_Bewegung_tief" ;
VAL_ 975 HBFS_SK_betaetigt 0 "ausgehoben" 1 "eingefallen" ;
VAL_ 975 HBFS_Sperrklinke 0 "Schloss_in_Vorraste_und_Hauptraste" 1 "Tuer_auf_oder_Tuer_Position_zwischen_Vor_und_Hauptraste" ;
VAL_ 975 HBFS_Status_eTAG 0 "Init" 1 "Griff_ausgefahren" 2 "Griff_eingefahren" 3 "Fehler" ;
VAL_ 975 HBFS_Status_KiSi 0 "inaktiv" 1 "aktiv" ;
VAL_ 975 HBFS_Status_KiSi_inv 0 "aktiv" 1 "inaktiv" ;
VAL_ 975 HBFS_TAG_betaetigt 0 "nicht_betaetigt" 1 "betaetigt" ;
VAL_ 975 HBFS_TIG_betaetigt 0 "nicht_betaetigt" 1 "betaetigt" ;
VAL_ 975 HBFS_TIG_betaetigt_oeffnen 0 "nicht_betaetigt" 1 "betaetigt" ;
VAL_ 975 HBFS_TIG_betaetigt_schliessen 0 "nicht_betaetigt" 1 "betaetigt" ;
VAL_ 975 HBFS_Tuer_geoeffnet 0 "geschlossen" 1 "offen" ;
VAL_ 975 HBFS_Tuer_Status 0 "Init" 1 "Tuer_geschlossen" 2 "Tuer_offen" 3 "Fehler" ;
VAL_ 975 HBFS_Tuer_Status_QBit 0 "Status_Tuerkontakt_sicher" 1 "Status_Tuerkontakt_unsicher" ;
VAL_ 975 HBFS_Tueroeffnen_Warnung 0 "Tuerwarnung_nicht_aktiv" 1 "Tuerwarnung_aktiv" ;
VAL_ 975 HBFS_Tuerschloss_defekt 0 "Tuerschloss_funktionsfaehig" 1 "Tuerschloss_defekt" ;
VAL_ 975 HBFS_UEKB_aktiviert 0 "inaktiv" 1 "aktiv" ;
VAL_ 975 HBFS_Unlock_Taster 0 "nicht_betaetigt" 1 "betaetigt" ;
VAL_ 975 HBFS_Unten_Block_erw 0 "Fensterheber_nicht_in_Blockerwar" 1 "Fensterheber_in_Blockerwartung_u" ;
VAL_ 975 HBFS_verriegelt 0 "nicht_verriegelt" 1 "verriegelt" ;
VAL_ 975 HBFS_Vorraste_betaetigt 0 "nicht_in_Vorraste" 1 "in_Vorraste" ;
VAL_ 975 HBFS_Zuziehhilfe_aktiv 0 "Init" 1 "Zuziehhilfe_aktiv" ;
VAL_ 975 MTHBFS_M_Taste 0 "nicht_betaetigt" 1 "betaetigt" ;
VAL_ 975 MTHBFS_Pos1 0 "nicht_betaetigt" 1 "betaetigt" ;
VAL_ 975 MTHBFS_Pos2 0 "nicht_betaetigt" 1 "betaetigt" ;
VAL_ 975 MTHBFS_Pos3 0 "nicht_betaetigt" 1 "betaetigt" ;
VAL_ 975 SSR_HBFS_Pos_Unten 0 "SSR_Oben" 1 "SSR_Unten" ;
VAL_ 974 ASW_Warnung_aktiv_HFS 0 "nicht_angefordert" 1 "angefordert" ;
VAL_ 974 HFS_FH_Bew_hoch 0 "inaktiv" 1 "aktiv" ;
VAL_ 974 HFS_FH_Bew_tief 0 "inaktiv" 1 "aktiv" ;
VAL_ 974 HFS_FH_Block 0 "inaktiv" 1 "aktiv" ;
VAL_ 974 HFS_FH_Fang 0 "ausserhalb_Fangbereich" 1 "innerhalb_Fangbereich" ;
VAL_ 974 HFS_FH_normiert 0 "inaktiv" 1 "aktiv" ;
VAL_ 974 HFS_FH_S_AutoHoch 0 "nicht_betaetigt" 1 "betaetigt" ;
VAL_ 974 HFS_FH_S_AutoTief 0 "nicht_betaetigt" 1 "betaetigt" ;
VAL_ 974 HFS_FH_S_HBFS_AutoHoch 0 "keine_Bedienung" 1 "Automatiklauf_Angefordert" ;
VAL_ 974 HFS_FH_S_HBFS_AutoTief 0 "keine_Bedienung" 1 "Automatiklauf_Angefordert" ;
VAL_ 974 HFS_FH_S_HBFS_ManHoch 0 "keine_Bedienung" 1 "Manueller_Lauf_Angefordert" ;
VAL_ 974 HFS_FH_S_HBFS_ManTief 0 "keine_Bedienung" 1 "Manueller_Lauf_Angefordert" ;
VAL_ 974 HFS_FH_S_ManHoch 0 "nicht_betaetigt" 1 "betaetigt" ;
VAL_ 974 HFS_FH_S_ManTief 0 "nicht_betaetigt" 1 "betaetigt" ;
VAL_ 974 HFS_FH_Thermo 0 "inaktiv" 1 "aktiv" ;
VAL_ 974 HFS_gesafet 0 "nicht_gesafet" 1 "gesafet" ;
VAL_ 974 HFS_Heckrollotaster_betaetigt 0 "keine_Verfahranweisung_in_Richtung_Hoch" 1 "In_Richtung_Hoch_Verfahren" ;
VAL_ 974 HFS_Lock_Taster 0 "nicht_betaetigt" 1 "betaetigt" ;
VAL_ 974 HFS_Lock_Taster_inv 0 "Lock Taster betï?½tgit" 1 "Lock Taster nicht betï?½tigt" ;
VAL_ 974 HFS_MRollo_Schalter 0 "nicht_betaetigt" 1 "ZU_manuell" 2 "ZU_automatik" 3 "AUF_manuell" 4 "AUF_automatik" 5 "nicht_verfuegbar" 6 "Init" 7 "Fehler" ;
VAL_ 974 HFS_Oben_Block_erw 0 "Fensterheber_nicht_in_Blockerwar" 1 "Fensterheber_in_Blockerwartung_o" ;
VAL_ 974 HFS_SAD_Schalter 0 "nicht_betaetigt" 5 "AUF_manuell" 6 "AUF_automatik" 7 "ZU_manuell" 8 "ZU_automatik" 13 "nicht_verfuegbar" 14 "Init" 15 "Fehler" ;
VAL_ 974 HFS_Seitenrollo_hoch 0 "Init" 1 "Seitenrollo_in_Bewegung_hoch" ;
VAL_ 974 HFS_Seitenrollo_tief 0 "Init" 1 "Seitenrollo_in_Bewegung_tief" ;
VAL_ 974 HFS_SK_betaetigt 0 "ausgehoben" 1 "eingefallen" ;
VAL_ 974 HFS_Sperrklinke 0 "Schloss_in_Vorraste_und_Hauptraste" 1 "Tuer_auf_oder_Tuer_Position_zwischen_Vor_und_Hauptraste" ;
VAL_ 974 HFS_Status_eTAG 0 "Init" 1 "Griff_ausgefahren" 2 "Griff_eingefahren" 3 "Fehler" ;
VAL_ 974 HFS_Status_KiSi 0 "inaktiv" 1 "aktiv" ;
VAL_ 974 HFS_TAG_betaetigt 0 "nicht_betaetigt" 1 "betaetigt" ;
VAL_ 974 HFS_TCR_Mode_aktiv 0 "TCR_Mode_deaktiv" 1 "TCR_Mode_aktiv" ;
VAL_ 974 HFS_TIG_betaetigt 0 "nicht_betaetigt" 1 "betaetigt" ;
VAL_ 974 HFS_TIG_betaetigt_oeffnen 0 "nicht_betaetigt" 1 "betaetigt" ;
VAL_ 974 HFS_TIG_betaetigt_schliessen 0 "nicht_betaetigt" 1 "betaetigt" ;
VAL_ 974 HFS_Tuer_geoeffnet 0 "geschlossen" 1 "offen" ;
VAL_ 974 HFS_Tuer_Status 0 "Init" 1 "Tuer_geschlossen" 2 "Tuer_offen" 3 "Fehler" ;
VAL_ 974 HFS_Tuer_Status_QBit 0 "Status_Tuerkontakt_sicher" 1 "Status_Tuerkontakt_unsicher" ;
VAL_ 974 HFS_Tueroeffnen_Warnung 0 "Tuerwarnung_nicht_aktiv" 1 "Tuerwarnung_aktiv" ;
VAL_ 974 HFS_Tuerschloss_defekt 0 "Tuerschloss_funktionsfaehig" 1 "Tuerschloss_defekt" ;
VAL_ 974 HFS_UEKB_aktiviert 0 "inaktiv" 1 "aktiv" ;
VAL_ 974 HFS_Unlock_Taster 0 "nicht_betaetigt" 1 "betaetigt" ;
VAL_ 974 HFS_Unten_Block_erw 0 "Fensterheber_nicht_in_Blockerwar" 1 "Fensterheber_in_Blockerwartung_u" ;
VAL_ 974 HFS_verriegelt 0 "nicht_verriegelt" 1 "verriegelt" ;
VAL_ 974 HFS_Vorraste_betaetigt 0 "nicht_in_Vorraste" 1 "in_Vorraste" ;
VAL_ 974 HFS_Zuziehhilfe_aktiv 0 "Init" 1 "Zuziehhilfe_aktiv" ;
VAL_ 974 MTHFS_M_Taste 0 "nicht_betaetigt" 1 "betaetigt" ;
VAL_ 974 MTHFS_Pos1 0 "nicht_betaetigt" 1 "betaetigt" ;
VAL_ 974 MTHFS_Pos2 0 "nicht_betaetigt" 1 "betaetigt" ;
VAL_ 974 MTHFS_Pos3 0 "nicht_betaetigt" 1 "betaetigt" ;
VAL_ 974 SSR_HFS_Pos_Unten 0 "SSR_Oben" 1 "SSR_Unten" ;
VAL_ 2463978710 OPS_ComfortReadyStatus 0 "Init" 1 "aktiv" 2 "inaktiv" 3 "Fehler" ;
VAL_ 2463978710 OPS_DriverPresenceStatus 0 "Init" 1 "reserviert" 2 "DriverAbsent" 3 "reserviert" 4 "DriverEntry" 5 "reserviert" 6 "DriverPresent" 7 "reserviert" 8 "DriverPresentVerified" 9 "reserviert" 10 "reserviert" 11 "DriverExitIntent" 12 "reserviert" 13 "DriverExit" 14 "reserviert" 15 "Fehler" ;
VAL_ 2463978710 OPS_OccupantPresenceStatus 0 "Init" 1 "OccupantAbsent" 2 "reserviert" 3 "OccupantEntryExit" 4 "reserviert" 5 "OccupantPresent" 6 "OccupantPresentVerified" 7 "Fehler" ;
VAL_ 2463978710 OPS_QBit_DriverPresence 0 "gueltiger_Wert" 1 "Ersatz_Init_oder_Fehlerwert" ;
VAL_ 2463978710 OPS_SafeDriverPresence_available 0 "Verfuegbar" 1 "Verfuegbar_eingeschr_Performance" ;
VAL_ 2463978710 OPS_SafeDriverPresenceStatus 0 "Init" 1 "Driver_Safe_Present" 2 "Driver_Not_Safe_Present" 3 "Fehler" ;
VAL_ 1057 VLK_Anf_Antrieb 0 "Init" 1 "Freigabe" 2 "VKM_Zustand_einfrieren" 3 "Zustartverbot_fuer_Fahrer" 5 "Startanforderung" 7 "Fehler" ;
VAL_ 1057 VLK_Anforderung_HMS 0 "keine_Anforderung" 1 "halten" 2 "parken" 3 "halten_Standby" 4 "anfahren" 5 "Loesen_ueber_Rampe" 6 "Parken_mit_P" 7 "HMS_uebernehmen" ;
VAL_ 1057 VLK_Anforderung_Rollfaehigkeit 0 "Rollfaehigkeitsmode_inaktiv_Init" 1 "Rollfaehigkeitsmodus_aktiv" ;
VAL_ 1057 VLK_Antriebsdeaktivierung 0 "Keine_Einschraenkung" 1 "Antrieb_deaktivieren" 3 "Fehler" ;
VAL_ 1057 VLK_autom_Absch_Signalisierung 0 "Init" 1 "Automatisierte_Abschaltung" ;
VAL_ 1057 VLK_Hinweis_Rollfaehigkeit 0 "Init_keinHinweis" 1 "Hinweis_ohne_Akustik" 2 "Hinweis_mit_Akustik" 3 "reserviert" ;
VAL_ 1057 VLK_Parken_beibehalten_HMS 0 "Parken_nicht_beibehalten" 1 "Parken_beibehalten" 2 "Init" 3 "Fehler" ;
VAL_ 1057 VLK_VLW_Anf 0 "Init" 1 "VLW_angefordert" 2 "degradierte_VLW_FT_Fehler" 3 "reserved" ;
VAL_ 2463978663 VZE_Akustik_Limitwechsel 0 "keine_akustische_Signalisierung" 1 "akustische_Signalisierung_an" ;
VAL_ 2463978663 VZE_Akustik_Limitwechsel_Status 0 "keine_akustische_Signalisierung" 1 "akustische_Signalisierung_an" ;
VAL_ 2463978663 VZE_Anhaenger_Vmax 14 "Init" 15 "Fehler" ;
VAL_ 2463978663 VZE_Anzeige_VZ_1 0 "kein_Verkehrszeichen" ;
VAL_ 2463978663 VZE_Anzeige_VZ_2 0 "kein_Verkehrszeichen" ;
VAL_ 2463978663 VZE_Anzeige_VZ_3 0 "kein_Verkehrszeichen" ;
VAL_ 2463978663 VZE_Anzeige_ZS_1 0 "Init" ;
VAL_ 2463978663 VZE_Anzeige_ZS_2 0 "Init" ;
VAL_ 2463978663 VZE_Anzeige_ZS_3 0 "Init" ;
VAL_ 2463978663 VZE_Anzeigemodus 0 "EU_RDW" 1 "USA" 2 "Canada" 3 "China" ;
VAL_ 2463978663 VZE_Anzeigeunterdrueck_Zeichen_1 0 "anzeigerelevant" 1 "nicht_anzeigerelevant" ;
VAL_ 2463978663 VZE_Anzeigeunterdrueck_Zeichen_2 0 "anzeigerelevant" 1 "nicht_anzeigerelevant" ;
VAL_ 2463978663 VZE_Anzeigeunterdrueck_Zeichen_3 0 "anzeigerelevant" 1 "nicht_anzeigerelevant" ;
VAL_ 2463978663 VZE_Anzeigeunterdrueck_Zeichen_4 0 "anzeigerelevant" 1 "nicht_anzeigerelevant" ;
VAL_ 2463978663 VZE_Anzeigeunterdrueck_Zeichen_5 0 "anzeigerelevant" 1 "nicht_anzeigerelevant" ;
VAL_ 2463978663 VZE_Baustelle 0 "Keine_Baustelle" 1 "Baustelle_erkannt" ;
VAL_ 2463978663 VZE_Erweiterte_Information 0 "keine_Information" ;
VAL_ 2463978663 VZE_FoD_Status 0 "Init" 1 "Funktion_inaktiv" 2 "Funktion_aktiv" ;
VAL_ 2463978663 VZE_Gong 0 "Gong_deaktiv" 1 "Gong_aktiv" ;
VAL_ 2463978663 VZE_Hinweistext 0 "kein_Hinweistext" ;
VAL_ 2463978663 VZE_Hinweistext_03 0 "kein_Hinweistext" ;
VAL_ 2463978663 VZE_Land 0 "Init" ;
VAL_ 2463978663 VZE_Modus_OptischeWarnung 0 "konstant" 1 "blinkend" ;
VAL_ 2463978663 VZE_SLWF_Status 0 "Init" 1 "aktiv" 2 "deaktiv" ;
VAL_ 2463978663 VZE_Tempowarnung_Einheit 0 "kmh" 1 "mph" ;
VAL_ 2463978663 VZE_Tempowarnung_Offset 0 "Init" ;
VAL_ 2463978663 VZE_Tempowarnung_Status 0 "inaktiv" 1 "aktiv" ;
VAL_ 2463978663 VZE_Umweltinfo_Anhaengerbetrieb 0 "inaktiv" 1 "aktiv" ;
VAL_ 2463978663 VZE_Umweltinfo_Naesse 0 "inaktiv" 1 "aktiv" ;
VAL_ 2463978663 VZE_Umweltinfo_Nebel 0 "inaktiv" 1 "aktiv" ;
VAL_ 2463978663 VZE_Verkehrszeichen_1 0 "kein_Verkehrszeichen" ;
VAL_ 2463978663 VZE_Verkehrszeichen_2 0 "kein_Verkehrszeichen" ;
VAL_ 2463978663 VZE_Verkehrszeichen_3 0 "kein_Verkehrszeichen" ;
VAL_ 2463978663 VZE_Verkehrszeichen_4 0 "kein_Verkehrszeichen" ;
VAL_ 2463978663 VZE_Verkehrszeichen_5 0 "kein_Verkehrszeichen" ;
VAL_ 2463978663 VZE_Verkehrszeichen_6 0 "kein_Verkehrszeichen" ;
VAL_ 2463978663 VZE_Verkehrszeichen_Einheit 0 "kmh" 1 "mph" ;
VAL_ 2463978663 VZE_Warnung_Verkehrszeichen_1 0 "keine_Warnung_Initialwert_Fehlerwert" 1 "Warnung" ;
VAL_ 2463978663 VZE_Warnung_Verkehrszeichen_2 0 "keine_Warnung_Initialwert_Fehlerwert" 1 "Warnung" ;
VAL_ 2463978663 VZE_Warnung_Verkehrszeichen_3 0 "keine_Warnung_Initialwert_Fehlerwert" 1 "Warnung" ;
VAL_ 2463978663 VZE_Warnung_Verkehrszeichen_4 0 "keine_Warnung_Initialwert_Fehlerwert" 1 "Warnung" ;
VAL_ 2463978663 VZE_Warnung_Verkehrszeichen_5 0 "keine_Warnung_Initialwert_Fehlerwert" 1 "Warnung" ;
VAL_ 2463978663 VZE_Warnung_VZ_1 0 "keine_Warnung" 1 "Warnung" ;
VAL_ 2463978663 VZE_Warnung_VZ_2 0 "keine_Warnung" 1 "Warnung" ;
VAL_ 2463978663 VZE_Warnung_VZ_3 0 "keine_Warnung" 1 "Warnung" ;
VAL_ 2463978663 VZE_Zeichen_01_Gesetz 0 "nicht_erkannt" 1 "erkannt" ;
VAL_ 2463978663 VZE_Zeichen_01_Kamera 0 "nicht_erkannt" 1 "erkannt" ;
VAL_ 2463978663 VZE_Zeichen_01_KameraWied 0 "inaktiv" 1 "aktiv" ;
VAL_ 2463978663 VZE_Zeichen_01_Karte 0 "inaktiv" 1 "aktiv" ;
VAL_ 2463978663 VZE_Zeichen_02_Gesetz 0 "nicht_erkannt" 1 "erkannt" ;
VAL_ 2463978663 VZE_Zeichen_02_Kamera 0 "nicht_erkannt" 1 "erkannt" ;
VAL_ 2463978663 VZE_Zeichen_02_KameraWied 0 "inaktiv" 1 "aktiv" ;
VAL_ 2463978663 VZE_Zeichen_02_Karte 0 "inaktiv" 1 "aktiv" ;
VAL_ 2463978663 VZE_Zeichen_03_Gesetz 0 "nicht_erkannt" 1 "erkannt" ;
VAL_ 2463978663 VZE_Zeichen_03_Kamera 0 "nicht_erkannt" 1 "erkannt" ;
VAL_ 2463978663 VZE_Zeichen_03_KameraWied 0 "inaktiv" 1 "aktiv" ;
VAL_ 2463978663 VZE_Zeichen_03_Karte 0 "inaktiv" 1 "aktiv" ;
VAL_ 2463978663 VZE_Zeichen_04_Gesetz 0 "nicht_erkannt" 1 "erkannt" ;
VAL_ 2463978663 VZE_Zeichen_04_Kamera 0 "nicht_erkannt" 1 "erkannt" ;
VAL_ 2463978663 VZE_Zeichen_04_KameraWied 0 "inaktiv" 1 "aktiv" ;
VAL_ 2463978663 VZE_Zeichen_04_Karte 0 "inaktiv" 1 "aktiv" ;
VAL_ 2463978663 VZE_Zeichen_05_Entfernung 0 "Init" ;
VAL_ 2463978663 VZE_Zeichen_05_Entfernung_StdA 0 "Init" ;
VAL_ 2463978663 VZE_Zeichen_05_Gesetz 0 "nicht_erkannt" 1 "erkannt" ;
VAL_ 2463978663 VZE_Zeichen_05_Kamera 0 "nicht_erkannt" 1 "erkannt" ;
VAL_ 2463978663 VZE_Zeichen_05_KameraWied 0 "inaktiv" 1 "aktiv" ;
VAL_ 2463978663 VZE_Zeichen_05_Karte 0 "inaktiv" 1 "aktiv" ;
VAL_ 2463978663 VZE_Zeichen_06_Entfernung 0 "Init" ;
VAL_ 2463978663 VZE_Zeichen_06_Entfernung_StdA 0 "Init" ;
VAL_ 2463978663 VZE_Zusatzschild_1 0 "keine_Zusatzschild_Initialwert_Fehlerwert" ;
VAL_ 2463978663 VZE_Zusatzschild_2 0 "keine_Zusatzschild_Initialwert_Fehlerwert" ;
VAL_ 2463978663 VZE_Zusatzschild_3 0 "keine_Zusatzschild_Initialwert_Fehlerwert" ;
VAL_ 2463978663 VZE_Zusatzschild_4 0 "keine_Zusatzschild_Initialwert_Fehlerwert" ;
VAL_ 2463978663 VZE_Zusatzschild_5 0 "keine_Zusatzschild_Initialwert_Fehlerwert" ;
VAL_ 2463978663 VZE_Zusatzschild_6 0 "keine_Zusatzschild_Initialwert_Fehlerwert" ;
VAL_ 916 GE_Sollgang 0 "keine_Empfehlung" 1 "Gang_1" 2 "Gang_2" 3 "Gang_3" 4 "Gang_4" 5 "Gang_5" 6 "Gang_6" 7 "Gang_7" 8 "Gang_8" 9 "Gang_9" 11 "Gang_10" ;
VAL_ 916 GE_Stoppverbot_Anz_01 0 "keine_Anzeige" 1 "Temperaturbedingung" ;
VAL_ 916 GE_Stoppverbot_Anz_02 0 "keine_Anzeige" 1 "Drucksensorausfall" ;
VAL_ 916 GE_Stoppverbot_Anz_03 0 "keine_Anzeige" 1 "Grundeinstellung" ;
VAL_ 916 GE_Stoppverbot_Anz_04 0 "keine_Anzeige" 1 "Demontagestellung" ;
VAL_ 916 GE_Stoppverbot_Anz_05 0 "keine_Anzeige" 1 "Eingeschraenkte_Fahrfunktion_Notlauf_Liegenbleiber" ;
VAL_ 916 GE_Stoppverbot_Anz_06 0 "keine_Anzeige" 1 "Stoppverbot_ueber_Applikation" ;
VAL_ 916 GE_Stoppverbot_Anz_07 0 "keine_Anzeige" 1 "Schaltung_aktiv" ;
VAL_ 916 GE_Stoppverbot_Anz_Std 0 "keine_Anzeige" 1 "Standard_Stoppvetogrund" ;
VAL_ 916 GE_Tipschaltempf_verfuegbar 0 "nicht_verfuegbar" 1 "verfuegbar" ;
VAL_ 916 GE_Wiederstart_Anz_Std 0 "keine_Anzeige" 1 "Standard_Wiederstartgrund" ;
VAL_ 916 WBA_Anforderung_Akustik 0 "Akustik_aus" 1 "Akustik_ein" ;
VAL_ 916 WBA_Blinken 0 "kein_WBA_Blinken" 1 "WBA_Blinken" ;
VAL_ 916 WBA_eing_Gang_02 0 "keine_Ganganzeige" 1 "Gang_1" 2 "Gang_2" 3 "Gang_3" 4 "Gang_4" 5 "Gang_5" 6 "Gang_6" 7 "Gang_7" 8 "Gang_8" 9 "Gang_9" 10 "Funktion_Ganganzeigeunterdrueckung" 11 "Gang_10" ;
VAL_ 916 WBA_Fahrstufe_02 0 "Zwischenstellung_keine_Position" 1 "Position_P" 2 "Position_R" 3 "Position_N" 4 "Position_D" 5 "Position_S" 6 "Position_M_Tippfunktion" 7 "Kurzzeit_M" 8 "Position_E" 9 "Position_MS" 10 "Position_S_Plus" 11 "Position_MS_Plus" 12 "Position_Offroad" 13 "Position_B" ;
VAL_ 916 WBA_GE_Texte 0 "keine_Anzeige" 1 "zum_Einlegen_einer_Fahrstufe_Fussbremse_betaetigen__ShiftLock_Information" 2 "zum_Einlegen_von_R_N_D_Fussbremse_betaetigen_und_Motor_starten" 3 "Wegrollgefahr_bitte_P_einlegen" 4 "Achtung_Zeitueberschreitung_P_wird_eingelegt" 5 "Wiederanmeldeprozedur_Bremse_betaetigen" 6 "P_nur_im_Stillstand_moeglich" 7 "Rennstart_aktiv" ;
VAL_ 916 WBA_GE_Texte_02 0 "Keine_Anzeige" 1 "Fahrtrichtungswechsel_nur_nach_Stillstandt" 2 "Ladestecker_gesteckt" 3 "zusaetzlicher_Service_erforderlich" 4 "eLaunch_Aktiv" 5 "eLaunch_nicht_moeglich" 6 "WH_S_nicht_moeglich_Offroad" 7 "WH_S_nicht_moeglich_RangeMode" ;
VAL_ 916 WBA_GE_Warnung_02 0 "keine_Anzeige" 1 "Fehlereskalationsstufe_I" 2 "Fehlereskalationsstufe_II" 3 "Weiterfahrt_nur_eingeschraenkt_moeglich__Kein_R_Gang" 4 "Getriebefehler_Weiterfahrt_nur_in_D_moeglich__P_bei_Motor_aus" 5 "Wegrollgefahr__P_nicht_moeglich" 6 "Paddlenotbetrieb_Schema+Warnung" 7 "Paddlenotbetrieb_Schema" 8 "Geschwindigkeitsbegrenzung_Notlauf" 9 "Fehlereskalationsst_o_Einschr" 10 "Fehlereskalationsstufe_v_Limit" 11 "Parksperre_Infostufe" 12 "Parksperre_Warnstufe_I" 13 "Parksperre_Warnstufe_II" ;
VAL_ 916 WBA_GE_Zusatzwarnungen 0 "keine_Anzeige" 1 "Getriebeueberhitzung_Warnstufe_I" 2 "Getriebeueberhitzung_Warnstufe_II" 3 "Getriebefehler_Bitte_anhalten_und_P_einlegen" ;
VAL_ 916 WBA_Schaltschema_02 0 "kein_Schaltschema" 1 "R_N_DS" 2 "R_N_ES" 3 "R_N_DB" 4 "R_N_D" 5 "R_N_SSplus" ;
VAL_ 916 WBA_Schaltschema_Fahreraktion 0 "keine_Fahreraktion" 1 "Fahreraktion" ;
VAL_ 916 WBA_Schaltschema_FS_inaktiv 0 "alle_Fahrstufen_aktiv" 1 "Fahrstufe_Rueckwaerts_inaktiv" 2 "nur_P_und_N_aktiv" 3 "alle_Fahrstufen_inaktiv" ;
VAL_ 916 WBA_Schaltschema_FS_vorwaerts 0 "FS1_aktiv__FS2_moeglich" 1 "FS2_aktiv__FS1_moeglich" 2 "FS1_aktiv__FS2_nicht_moeglich" 3 "FS2_aktiv__FS1_nicht_moeglich" ;
VAL_ 916 WBA_Schaltschema_Tippgasse 0 "keine_Tippgasse_vorhanden" 1 "Tippgasse_vorhanden" ;
VAL_ 916 WBA_Segeln_aktiv 0 "inaktiv" 1 "aktiv" ;
VAL_ 916 WBA_Shiftlock_Lampe 0 "Shiftlock_Lampe_AUS" 1 "Shiftlock_Lampe_EIN" ;
VAL_ 916 WBA_ZielFahrstufe 0 "keine_Gangempfehlung_kein_Gang_eingelegt" 1 "Pfeil_nach_S" 2 "Pfeil_nach_D" 3 "Pfeil_nach_M" 4 "Pfeil_nach_E" ;
VAL_ 1361 WFS_Betrieb_Lesespule 0 "keine_Schluesselkomm_Lesespule" 1 "Schluesselkomm_Lesespule" ;
VAL_ 1361 WFS_ELV_authorisiert 0 "ELV_nicht_authorisiert" 1 "ELV_authorisiert" ;
VAL_ 1361 WFS_Fahrerhinweise 0 "Keine_Anzeigeanforderung" 1 "Schuessel_Auth_niO" 2 "Notlauf_aktiv" 3 "Schluessel_Kessy_nicht_gefunden" ;
VAL_ 1361 WFS_ID_Geb_autorisiert 0 "Schluessel_nicht_authorisiert" 1 "Schluessel_authorisiert" ;
VAL_ 1361 WFS_ID_Geb_autorisiert_in_Kl15 0 "nicht_authorisiert_in_Kl15" 1 "authorisiert_in_Kl15" ;
VAL_ 1361 WFS_ID_Geb_steckt 0 "kein_Schluessel_im_Zuendschloss" 1 "" ;
VAL_ 1361 WFS_Klemmenfreigabe 0 "keine_Freigabe" 1 "Freigabe" ;
VAL_ 1361 WFS_LF_Aktiv 0 "Funktempfang_nicht_aktiv" 1 "LF_Funkempfang_aktiv" ;
VAL_ 1361 WFS_LZ 0 "nicht def." 1 "LZ 1" 2 "LZ 2" 3 "LZ 3" ;
VAL_ 1361 WFS_LZ_02 0 "Lieferant/Init" 1 "fabrikneu" 2 "angelernt" 3 "Schluessel_lernen_Kundendienst" 4 "Schluessel_lernen_Produktion" 8 "WFS_temporaer_nicht_verfuegbar" 9 "Fehler" ;
VAL_ 1361 WFS_Parken_Status 0 "Limitierung_inaktiv" 1 "Limitierung_aktiv" 2 "Abbruch" ;
VAL_ 1361 WFS_Safe 0 "Init" 1 "WFS nicht deaktiviert" ;
VAL_ 1361 WFS_Schluessel_Fahrberecht 0 "kein authorisierter Schluessel erkannt" 1 "aktive_Funkschluessel_Nr_01" 2 "aktive_Funkschluessel_Nr_02" 3 "aktive_Funkschluessel_Nr_03" 4 "aktive_Funkschluessel_Nr_04" 5 "aktive_Funkschluessel_Nr_05" 6 "aktive_Funkschluessel_Nr_06" 7 "aktive_Funkschluessel_Nr_07" 8 "aktive_Funkschluessel_Nr_08" 9 "ungueltig_09" 10 "ungueltig_10" 11 "ungueltig_11" 12 "ungueltig_12" 13 "ungueltig_13" 14 "ungueltig_14" 15 "digitaler_Schluessel_aktiv" ;
VAL_ 1361 WFS_Verbauinfo_ELV 0 "ELV_nicht_verbaut" 1 "ELV_verbaut" ;
VAL_ 830 WFS_Diag_LF_Aktiv_02 0 "inaktiv" 1 "aktiv" ;
VAL_ 830 WFS_LF_aktiv_02 0 "Feld_inaktiv" 1 "Feld_aktiv" ;
VAL_ 830 WFS_Transp_Mod_Unterbrechung_02 0 "kein_Uebergang" 1 "Uebergang_erkannt" ;
VAL_ 830 WFS_Verbau_Transp_Ant_02 0 "inaktiv" 1 "aktiv" ;
VAL_ 1702 BCM1_SRA_aktiv 0 "nicht aktiv" 1 "aktiv" ;
VAL_ 1702 Waschen_vorne_aktiv 0 "inaktiv" 1 "Waschen_aktiv" ;
VAL_ 1702 Wischer1_Wischgeschwindigkeit 0 "0 U/min" 62 "Init" 63 "Fehler" ;
VAL_ 1702 Wischer_Anzeigetext 0 "keine_Anzeige" 1 "Hinweis_Service_Position" 2 "void" 3 "void" ;
VAL_ 1702 Wischer_vorne_aktiv 0 "Init" 1 "Wischer_vorne_laeuft" ;
VAL_ 1702 Wischer_vorne_blockiert 1 "Wischer vorne blockiert" ;
VAL_ 1702 Wischer_vorne_defekt 0 "Init" 1 "Wischer vorne defekt" ;
VAL_ 1702 Wischer_vorne_Normal 1 "Wischer Front normal aktiv" ;
VAL_ 1702 Wischer_vorne_Parklage 0 "Wischer_Front_nicht_in_Parklage" 1 "Wischer_Front_in_Parklage__Initialzustand" ;
VAL_ 1702 Wischer_vorne_Schnell 1 "Wischer vorne schnell aktiv" ;
VAL_ 1702 Wischer_WH_PopUp_Anf 0 "keine_Anzeige" 1 "Intervallstufe_1_aktiv" 2 "Intervallstufe_2_aktiv" 3 "Intervallstufe_3_aktiv" 4 "Intervallstufe_4_aktiv" 5 "Regensensorstufe_1_aktiv" 6 "Regensensorstufe_2_aktiv" 7 "Regensensorstufe_3_aktiv" 8 "Regensensorstufe_4_aktiv" 9 "Wischerstufe_1_aktiv" 10 "Wischerstufe_2_aktiv" 11 "Tippwischen_aktiv" 12 "Heckwischen_aktiv" ;
VAL_ 1702 Wischer_WH_Typ 0 "Lenkstockschalter_0_Int_Stufen" 1 "Lenkstockschalter_2_Int_Stufen" 2 "Lenkstockschalter_4_Int_Stufen" ;
VAL_ 1702 WWSs_01_alt 0 "aktuell" 1 "veraltet" ;
VAL_ 2589283611 WLC1_Fehler 0 "kein_Fehler" 1 "WLC_Kompensor_Kurzschluss" 2 "WLC_Kompensor_Unterbrechung" 4 "WLC_Antenne_Kurzschluss" 8 "WLC_Antenne_Unterbrechung" 16 "Kompensor_keine_Versorgung" 32 "Kompensor_defekt" 64 "WLC_defekt" ;
VAL_ 2589283611 WLC1_Fremdobjekt_erkannt 0 "no_Foreign_object" 1 "Foreign_object_detected" ;
VAL_ 2589283611 WLC1_Objekt_erkannt 0 "no_Device_in_Tray" 1 "non_WLC_Device_in_Tray" ;
VAL_ 2589283611 WLC1_Receiver_erkannt 0 "no_Device_in_tray" 1 "WLC_Device_in_tray" ;
VAL_ 2589283611 WLC1_Receiver_voll_geladen 0 "WLC_not_fully_charged" 1 "WLC_Device_fully_charged" ;
VAL_ 2589283768 BasicUTC_Day 0 "Init" ;
VAL_ 2589283768 BasicUTC_Hour 31 "Init" ;
VAL_ 2589283768 BasicUTC_Minute 63 "Init" ;
VAL_ 2589283768 BasicUTC_Month 15 "Init" ;
VAL_ 2589283768 BasicUTC_Quality 0 "Init" 1 "Zeitbasis_RTC" 2 "Zeitbasis_GNSS" 3 "Fehler" ;
VAL_ 2589283768 BasicUTC_Second 63 "Init" ;
VAL_ 2589283768 BasicUTC_Year 4095 "Init" ;
VAL_ 1140 DI_Screendesign 0 "Automatisch" 1 "Tag" 2 "Nacht" 6 "Init" 7 "Fehler" ;
VAL_ 1140 MMI_State 0 "MMI_OFF" 1 "MMI_IOC" 2 "MMI_STDBY" 3 "MMI_ON" 4 "MMI_STDBY_PWR_SAVE" 5 "MMI_STDBY_RESTR" 6 "MMI_ON_DIAG" 7 "MMI_ON_TEL" 8 "MMI_ON_SWDL" 9 "MMI_ON_CUST_SWDL" 10 "MMI_STDBY_PWR_SAVE_1" 11 "MMI_STDBY_PWR_SAVE_2" 12 "MMI_STANDBY_CUST_SWDL" 13 "MMI_ONLINE_IOC" 14 "MMI_ONLINE" 15 "MMI_PHONE_IOC" 16 "MMI_PHONE" 17 "MMI_RTC" 18 "MMI_DCI" ;
VAL_ 1140 SI_ICAN 0 "keine_Busruhe" 1 "Busruhe" ;
VAL_ 1140 WLC1_Systemzustand 0 "Wireless_Charger_off" 1 "InitWert_Wireless_Charger_on" ;
VAL_ 1140 WLC2_Systemzustand 0 "Wireless_Charger_off" 1 "InitWert_Wireless_Charger_on" ;
VAL_ 1140 ZR_DimOffs_DU_1 14 "Init" ;
VAL_ 1140 ZR_DimOffs_DU_2 14 "Init" ;
VAL_ 1140 ZR_DimOffs_DU_3 14 "Init" ;
VAL_ 1140 ZR_DimOffs_DU_4 14 "Init" ;
VAL_ 1140 ZR_Lenkerposition 0 "links" 1 "rechts" ;
VAL_ 1140 ZR_State_DU_1 0 "Disp_Off" 1 "Disp_On" 2 "LowPow" ;
VAL_ 1140 ZR_State_DU_2 0 "Disp_Off" 1 "Disp_On" 2 "LowPow" ;
VAL_ 1140 ZR_State_DU_3 0 "Disp_Off" 1 "Disp_On" 2 "LowPow" ;
VAL_ 1140 ZR_State_DU_4 0 "Disp_Off" 1 "Disp_On" 2 "LowPow" ;
VAL_ 1140 ZR_WecktGesp 0 "entsperrt" 1 "gesperrt" ;
VAL_ 2589283965 DFB_CILState_ADA 0 "idle" 1 "onZero" 2 "onUnblock" 3 "onWarn" 4 "onBlock" 5 "unblockPassenger" 6 "error" 7 "reserved" ;
VAL_ 2589283965 DFB_InteractionStatus_ADA 0 "idle" 1 "no_interaction" 2 "interaction" 3 "error" ;
VAL_ 2589283965 SpeechAssistant_State 0 "init" 1 "nicht_aktiv" 2 "aktiv" 3 "nicht_verbaut" ;
VAL_ 2589283965 ZR_Plattform 0 "Init" 1 "MQB" 2 "MQB2020_MQB_W" 3 "MQBw_Baseline" 4 "Reserviert" 5 "Reserviert" 6 "MLBevo_Gen2" 7 "Reserviert" 8 "Reserviert" 9 "E3_1_1_MEB" 10 "E3_1_1_UNECE" 11 "E3_1_2_Premium" 12 "Reserviert" ;
VAL_ 1411 BCM_FH_Freigabe 1 "Funktionsfreigabe Fensterheber" ;
VAL_ 1411 BCM_HSK_Freigabe 0 "erlauben" 1 "sperren" ;
VAL_ 1411 BCM_Komfortfkt_Freigabe 0 "Komfortfunktion gesperrt" 1 "globale Freigabe der Komfortfunktion erteilt" ;
VAL_ 1411 BCM_Verdeck_Freigabe 0 "Verdeckbetrieb nicht erlaubt" 1 "Verdeckbetrieb erlaubt" ;
VAL_ 1411 DWA_aktiv 0 "unscharf" 1 "scharf" ;
VAL_ 1411 FBS_IDG_in_Reichweite 0 "ausser_Reichweite_bzw_nicht_ermittelbar" 1 "innerhalb_Reichweite" ;
VAL_ 1411 FBS_Warn_Schluessel_Batt 0 "i.O." 1 "defekt" ;
VAL_ 1411 FFB_Auf_Taste 0 "Taste_nicht_betaetigt" 1 "Oeffnentaste_betaetigt" ;
VAL_ 1411 FFB_CarFinder 0 "nicht aktiv" 1 "aktiv" ;
VAL_ 1411 FFB_HDF_Taste 0 "Taste_nicht_betaetigt" 1 "HDF_Taste_am_Funkschluessel_betaetigt" ;
VAL_ 1411 FFB_Komfortoeffnen 0 "kein_Komfortoeffnen_empfangen" 1 "Komfortoeffnen ueber Funk empfangen" ;
VAL_ 1411 FFB_Komfortschliessen 0 "kein_Komfortschliessen_empfangen" 1 "Komfortschliessen ueber Funk empfangen" ;
VAL_ 1411 FFB_Panik_Taste 0 "Taste_nicht_betaetigt" 1 "Panik_Taste_am_Funkschluessel_betaetigt" ;
VAL_ 1411 FFB_Zu_Taste 0 "Taste_nicht_betaetigt" 1 "Zu_Taste_am_Funkschluessel_betaetigt" ;
VAL_ 1411 IRUE_aktiv 0 "unscharf" 1 "scharf" ;
VAL_ 1411 IRUE_Taster_Fkts_LED 0 "LED_aus" 1 "LED_ein" ;
VAL_ 1411 VIP_Sensor_STSG_HBFS_betaetigt 0 "keine_VIP_Anforderung_STSG_HBFS" 1 "VIP_Anforderung_STSG_HBFS" ;
VAL_ 1411 VIP_Sensor_STSG_HFS_betaetigt 0 "keine_VIP_Anforderung_STSG_HFS" 1 "VIP_Anforderung_STSG_HFS" ;
VAL_ 1411 ZV_Anf_Challenge_Auth 0 "nicht_aktiv" 1 "aktiv" ;
VAL_ 1411 ZV_BT_offen 0 "BT_geschlossen" 1 "BT_geoeffnet" ;
VAL_ 1411 ZV_Einzeltuerentriegelung 1 "Fahrzeug an Einzeltuer entriegelt" ;
VAL_ 1411 ZV_eRWK_Umfeld_Pruefung 0 "nicht_aktiv" 1 "aktiv" ;
VAL_ 1411 ZV_FT_offen 0 "FT_geschlossen" 1 "FT_geoeffnet" ;
VAL_ 1411 ZV_gesafet_extern_ist 1 "Fahrzeug aussen gesafet; Istzustand" ;
VAL_ 1411 ZV_gesafet_extern_soll 1 "Fahrzeug_aussen_gesafet_Sollzustand" ;
VAL_ 1411 ZV_HBFS_offen 0 "geschlossen" 1 "offen" ;
VAL_ 1411 ZV_HD_offen 1 "Heckdeckel_auf" ;
VAL_ 1411 ZV_Heckeinzelentriegelung 1 "Heckdeckeleinzelentriegelung" ;
VAL_ 1411 ZV_HFS_offen 0 "geschlossen" 1 "offen" ;
VAL_ 1411 ZV_HS_offen 0 "Heckscheibe_geschlossen" 1 "Heckscheibe auf" ;
VAL_ 1411 ZV_ist_Zustand_verfuegbar 0 "nicht_verfuegbar" 1 "verfuegbar_alle_TSGs_am_Bus" ;
VAL_ 1411 ZV_Oeffnungsmodus 0 "globale_Oeffnung" 1 "ZV_mit_Einzeltuerentr" 2 "ZV_individuell_selektiv" 3 "ZV_seitenselektiv" ;
VAL_ 1411 ZV_Rollo_auf 0 "inaktiv" 1 "aktiv" ;
VAL_ 1411 ZV_Rollo_zu 0 "inaktiv" 1 "aktiv" ;
VAL_ 1411 ZV_SAD_auf 0 "inaktiv" 1 "aktiv" ;
VAL_ 1411 ZV_SAD_zu 0 "inaktiv" 1 "aktiv" ;
VAL_ 1411 ZV_SafeFunktion_aktiv 0 "inaktiv" 1 "aktiv" ;
VAL_ 1411 ZV_Schluessel_Zugang 0 "kein_auth_Schluessel_erkannt" 1 "aktive_Funkschluessel_Nr_01" 2 "aktive_Funkschluessel_Nr_02" 3 "aktive_Funkschluessel_Nr_03" 4 "aktive_Funkschluessel_Nr_04" 5 "aktive_Funkschluessel_Nr_05" 6 "aktive_Funkschluessel_Nr_06" 7 "aktive_Funkschluessel_Nr_07" 8 "aktive_Funkschluessel_Nr_08" 9 "aktive_SmartDevice_Nr_09" 10 "ungueltig_10" 11 "ungueltig_11" 12 "ungueltig_12" 13 "ungueltig_13" 14 "ungueltig_14" 15 "ungueltig_15" ;
VAL_ 1411 ZV_STSG_HBFS_Anf 0 "keine_Anforderung" 1 "Anforderung" ;
VAL_ 1411 ZV_STSG_HFS_Anf 0 "keine_Anforderung" 1 "Anforderung" ;
VAL_ 1411 ZV_Tankklappe_offen 0 "Tankklappe_geschlossen" 1 "Tankklappe_offen" ;
VAL_ 1411 ZV_verriegeln_Anf 0 "nicht_betaetigt" 1 "betaetigt" ;
VAL_ 1411 ZV_verriegelt_extern_ist 1 "Fahrzeug_aussen_verriegelt_Istzustand" ;
VAL_ 1411 ZV_verriegelt_extern_soll 1 "Fahrzeug verriegelt extern; Sollzusstand" ;
VAL_ 1411 ZV_verriegelt_intern_ist 1 "Fahrzeug innen verriegelt; Istzustand" ;
VAL_ 1411 ZV_verriegelt_intern_soll 1 "Fahrzeug verriegelt intern; Sollzusstand" ;
VAL_ 1411 ZV_verriegelt_soll 0 "Init" 1 "nicht_verriegelt" 2 "verriegelt" ;
VAL_ 708 BCM_Waehlhebel_P_Hinweis 0 "inaktiv" 1 "aktiv" ;
VAL_ 708 UHF_FFB_Funkschluesseltyp 0 "kein_Funk" 1 "Funk_315MHz_Japan_2_Kanalig" 2 "Funk_434MHz_RdW_NAR_2_Kanalig" 3 "Funk_434MHz_Suedkorea_1_Kanalig" ;
VAL_ 708 UHF_FFB_SKC_anlernen 0 "nicht_aktiv" 1 "aktiv" ;
VAL_ 708 ZV_DWA_Einfachhorn_Anf 0 "Keine_Anforderung" 1 "Anforderung" ;
VAL_ 708 ZV_DWA_Einfachhorn_Takt 0 "Horn_aus" 1 "Horn_an" ;
VAL_ 708 ZV_Einfachhorn_Anf 0 "Keine_Anforderung" 1 "Anforderung" ;
VAL_ 708 ZV_Einfachhorn_Takt 0 "Horn_aus" 1 "Horn_an" ;
VAL_ 708 ZV_HBFS_Status_KiSi 0 "inaktiv" 1 "aktiv" ;
VAL_ 708 ZV_HBFS_TAG_betaetigt 0 "nicht_betaetigt" 1 "betaetigt" ;
VAL_ 708 ZV_HBFS_TIG_oeffnen_betaetigt 0 "nicht_betaetigt" 1 "betaetigt" ;
VAL_ 708 ZV_HBFS_TIG_schliessen_betaetigt 0 "nicht_betaetigt" 1 "betaetigt" ;
VAL_ 708 ZV_HD_Parkbremse_Hinweis 0 "inaktiv" 1 "aktiv" ;
VAL_ 708 ZV_HFS_Status_KiSi 0 "inaktiv" 1 "aktiv" ;
VAL_ 708 ZV_HFS_TAG_betaetigt 0 "nicht_betaetigt" 1 "betaetigt" ;
VAL_ 708 ZV_HFS_TIG_oeffnen_betaetigt 0 "nicht_betaetigt" 1 "betaetigt" ;
VAL_ 708 ZV_HFS_TIG_schliessen_betaetigt 0 "nicht_betaetigt" 1 "betaetigt" ;
VAL_ 708 ZV_Hupe_Anf 0 "Keine_Anforderung" 1 "Anforderung" ;
VAL_ 708 ZV_Hupe_Takt 0 "Horn_aus" 1 "Horn_an" ;
VAL_ 708 ZV_HW_Motor_Lock_HK 0 "Schloss_nicht_ansteuern" 1 "Schloss_ansteuern" ;
VAL_ 708 ZV_HW_Motor_Safe_Hinten 0 "Schloss_nicht_ansteuern" 1 "Schloss_ansteuern" ;
VAL_ 708 ZV_HW_TKL_mot_entr 0 "nicht_aktiv" 1 "aktiv" ;
VAL_ 708 ZV_HW_TKL_mot_verr 0 "nicht_aktiv" 1 "aktiv" ;
VAL_ 708 ZV_Laderaumabd_elektr_aktiviert 0 "inaktiv" 1 "aktiv" ;
VAL_ 708 ZV_Status_Cargolock 0 "nicht_aktiv" 1 "aktiv" ;
VAL_ 708 ZV_Status_KiSi_CargoLock 0 "inaktiv" 1 "KiSi_aktiv" 2 "CargoLock_aktiv" 3 "KiSi_gesperrt" 7 "Fehler" ;
VAL_ 708 ZV_verriegelt_extern_soll_03 0 "Fahrzeug_nicht_extern_verriegelt" 1 "Fahrzeug_extern_verriegelt_Sollz" 2 "Init" 3 "Fehler" ;
